VERSION ""

NS_ :

BS_:

BU_: SMART_CORE

BO_ 1911 MGM_DIAG_REQ: 8 SMART_CORE
 SG_ DIAG_MGM_REQ_DATA : 0|64@1+ (1,0) [0|1.8446744074E+019] ""  SMART_CORE

BO_ 1980 LDC_DIAG_RES: 8 Vector__XXX
 SG_ DIAG_LDC_RES_DATA : 0|64@1+ (1,0) [0|1.8446744074E+019] "NA"  SMART_CORE

BO_ 2008 MCU_DIAG_RES: 8 Vector__XXX
 SG_ DIAG_MCU_RES_DATA : 0|64@1+ (1,0) [0|0] ""  SMART_CORE

BO_ 579 VCU_EVCAN_WAKEUP: 8 Vector__XXX
 SG_ VCU_EVCAN_WAKEUPREASONRESERVED2 : 24|40@1+ (1,0) [0|5] "NA"  SMART_CORE
 SG_ VCU_EVCAN_WAKEUPREASONRESERVED1 : 0|8@1+ (1,0) [0|5] "NA"  SMART_CORE
 SG_ VCU_EVCAN_WAKEUPREASON : 8|16@1+ (1,0) [0|5] "NA"  SMART_CORE

BO_ 936 VCU_EVCAN_SLEEP: 8 Vector__XXX
 SG_ VCU_EVCAN_SLEEPRESERVED : 0|64@1+ (1,0) [0|0] "NA"  SMART_CORE

BO_ 1933 ETL_DIAG_RES: 8 Vector__XXX
 SG_ DIAG_ETL_RES_DATA : 0|64@1+ (1,0) [0|1.8446744074E+019] "NA"  SMART_CORE

BO_ 1981 OBC_DIAG_RES: 8 Vector__XXX
 SG_ DIAG_OBC_RES_DATA : 0|64@1+ (1,0) [0|1.8446744074E+019] "NA"  SMART_CORE

BO_ 1976 BMS_DIAG_RES: 8 Vector__XXX
 SG_ DIAG_BMS_RES_DATA : 0|64@1+ (1,0) [0|1.8446744074E+019] "NA"  SMART_CORE

BO_ 1972 LDC_DIAG_REQ: 8 SMART_CORE
 SG_ DIAG_LDC_REQ_DATA : 0|64@1+ (1,0) [0|1.8446744074E+019] "NA" Vector__XXX

BO_ 1925 ETL_DIAG_REQ: 8 SMART_CORE
 SG_ DIAG_ETL_REQ_DATA : 0|64@1+ (1,0) [0|1.8446744074E+019] "NA" Vector__XXX

BO_ 1973 OBC_DIAG_REQ: 8 SMART_CORE
 SG_ DIAG_OBC_REQ_DATA : 0|64@1+ (1,0) [0|1.8446744074E+019] "NA" Vector__XXX

BO_ 2000 MCU_DIAG_REQ: 8 SMART_CORE
 SG_ DIAG_MCU_REQ_DATA : 0|64@1+ (1,0) [0|1.8446744074E+019] "NA" Vector__XXX

BO_ 1968 BMS_DIAG_REQ: 8 SMART_CORE
 SG_ DIAG_BMS_REQ_DATA : 0|64@1+ (1,0) [0|1.8446744074E+019] "NA" Vector__XXX

BO_ 336 BMS18_50: 8 Vector__XXX
 SG_ BMS_TotalCycle_Time : 48|16@1+ (1,0) [0|65535] "Min"  SMART_CORE
 SG_ BMS_DischargeCycle_Time : 32|16@1+ (1,0) [0|65535] "Min"  SMART_CORE
 SG_ BMS_ChargeCycle_Time : 16|16@1+ (1,0) [0|65535] "Min"  SMART_CORE
 SG_ BMS_CycleNumber : 0|16@1+ (1,0) [0|65534] ""  SMART_CORE

BO_ 285 BMS16_10: 8 Vector__XXX
 SG_ BMS_BattPack_PwrLimitErr_Common : 39|1@1+ (1,0) [0|1] ""  SMART_CORE
 SG_ BMS_Bat_I_OvrExtCurr_Flt_Dischrg : 41|1@1+ (1,0) [0|1] ""  SMART_CORE
 SG_ BMS_Bat_I_OverCurr_Flt_Discharge : 42|1@1+ (1,0) [0|1] ""  SMART_CORE
 SG_ BMS_BattOverVolt_Cutoff_Charge : 6|1@1+ (1,0) [0|1] ""  SMART_CORE
 SG_ BMS_ClntInlet_High_Temp_Charge : 15|1@1+ (1,0) [0|1] ""  SMART_CORE
 SG_ BMS_ClntInlet_Low_Temp_Charge : 14|1@1+ (1,0) [0|1] ""  SMART_CORE
 SG_ BMS_ClntOutlet_Low_Temp_Charge : 22|1@1+ (1,0) [0|1] ""  SMART_CORE
 SG_ BMS_Clntoutlet_High_Temp_Charge : 23|1@1+ (1,0) [0|1] ""  SMART_CORE
 SG_ BMS_BattOver_Temp_Cutoff_common : 31|1@1+ (1,0) [0|1] ""  SMART_CORE
 SG_ BMS_BattUnder_Temp_Cutoff_common : 30|1@1+ (1,0) [0|1] ""  SMART_CORE
 SG_ BMS_ClntSen_Thres_Fault_Charge : 21|1@1+ (1,0) [0|1] ""  SMART_CORE
 SG_ BMS_ReverseCurrDetect_Charge : 20|1@1+ (1,0) [0|1] ""  SMART_CORE
 SG_ BMS_PLP_Stop_Charge : 19|1@1+ (1,0) [0|1] ""  SMART_CORE
 SG_ BMS_CellUnderVolt_Cutoff_Common : 29|1@1+ (1,0) [0|1] ""  SMART_CORE
 SG_ BMS_BattUnderVolt_Cutoff_Common : 28|1@1+ (1,0) [0|1] ""  SMART_CORE
 SG_ BMS_ModuleOverTemp_Cutoff_Common : 27|1@1+ (1,0) [0|1] ""  SMART_CORE
 SG_ BMS_MdleUnderTemp_Cutoff_Common : 26|1@1+ (1,0) [0|1] ""  SMART_CORE
 SG_ BMS_ShortCircuitCurr_Flt_Common : 38|1@1+ (1,0) [0|1] ""  SMART_CORE
 SG_ BMS_Sensor_Failure_Common : 37|1@1+ (1,0) [0|1] ""  SMART_CORE
 SG_ BMS_Ibatt_392_25sec_Common : 36|1@1+ (1,0) [0|1] ""  SMART_CORE
 SG_ BMS_PilotLine_Detect_Common : 35|1@1+ (1,0) [0|1] ""  SMART_CORE
 SG_ BMS_Revive_Common : 34|1@1+ (1,0) [0|1] ""  SMART_CORE
 SG_ BMS_HeaterSys_Flt_Common : 47|1@1+ (1,0) [0|1] ""  SMART_CORE
 SG_ BMS_Clnt_TempSens_Flt_Common : 46|1@1+ (1,0) [0|1] ""  SMART_CORE
 SG_ BMS_Heater_Flt_Common : 45|1@1+ (1,0) [0|1] ""  SMART_CORE
 SG_ BMS_IsoFLt_Red_Discharge : 44|1@1+ (1,0) [0|1] ""  SMART_CORE
 SG_ BMS_LowSOC_Cutoff_Discharge : 43|1@1+ (1,0) [0|1] ""  SMART_CORE
 SG_ BMS_Bat_I_ExtCurr_Flt_Dischrg : 40|1@1+ (1,0) [0|1] ""  SMART_CORE
 SG_ BMS_MTM_ActvLimit_Common : 33|1@1+ (1,0) [0|1] ""  SMART_CORE
 SG_ BMS_ClntSys_Flt_Common : 32|1@1+ (1,0) [0|1] ""  SMART_CORE
 SG_ BMS_Pump_DryRun_Err_Common : 25|1@1+ (1,0) [0|1] ""  SMART_CORE
 SG_ BMS_CrashDtct_P_F_Open_Common : 24|1@1+ (1,0) [0|1] ""  SMART_CORE
 SG_ BMS_HVIL_Err_Dischrg : 55|1@1+ (1,0) [0|1] ""  SMART_CORE
 SG_ BMS_No_Cntctr_Close : 54|1@1+ (1,0) [0|1] ""  SMART_CORE
 SG_ BMS_CntctrOpen_Rqst_VCU_Dischrg : 52|1@1+ (1,0) [0|1] ""  SMART_CORE
 SG_ BMS_CntctrOpen_Rqst_VCU_Chrg : 53|1@1+ (1,0) [0|1] ""  SMART_CORE
 SG_ BMS_InitCntctrOpen_Dischrg : 51|1@1+ (1,0) [0|1] ""  SMART_CORE
 SG_ BMS_InitCntctrOpen_Charge : 50|1@1+ (1,0) [0|1] ""  SMART_CORE
 SG_ BMS_FSBIM_bAcvDrtdMode : 49|1@1+ (1,0) [0|1] ""  SMART_CORE
 SG_ BMS_FSPLP_bAcvDrtdMode : 48|1@1+ (1,0) [0|1] ""  SMART_CORE
 SG_ BMS_ILC_AcvDrtdCdn : 60|1@1+ (1,0) [0|1] ""  SMART_CORE
 SG_ BMS_IDMStsIsInErr_Yellow : 61|1@1+ (1,0) [0|1] ""  SMART_CORE
 SG_ BMS_FSPLP_bAcvPackOverUDrtd : 63|1@1+ (1,0) [0|1] ""  SMART_CORE
 SG_ BMS_BIM_bAcvHighRateDchaDrdt2 : 59|1@1+ (1,0) [0|1] ""  SMART_CORE
 SG_ BMS_FSPLP_bAcvPackUnderUDrtd : 62|1@1+ (1,0) [0|1] ""  SMART_CORE
 SG_ BMS_BIMbAcvReqDrtdMode : 58|1@1+ (1,0) [0|1] ""  SMART_CORE
 SG_ BMS_BTFD_bAcvReqDrtdMode : 57|1@1+ (1,0) [0|1] ""  SMART_CORE
 SG_ BMS_CUM_bAcvOwDrtd : 56|1@1+ (1,0) [0|1] ""  SMART_CORE
 SG_ BMS_CellOverVolt_Cutoff_Charge : 7|1@1+ (1,0) [0|1] ""  SMART_CORE
 SG_ BMS_Reason_HV_Disconnected : 16|3@1+ (1,0) [0|7] ""  SMART_CORE
 SG_ BMS_Reason_HV_Disconnect_Request : 8|6@1+ (1,0) [0|28] ""  SMART_CORE
 SG_ BMS_Reason_Derating : 0|6@1+ (1,0) [0|30] ""  SMART_CORE

BO_ 1954 ESCL_DIAG_REQ: 8 SMART_CORE
 SG_ DIAG_ESCL_REQ_DATA : 0|64@1+ (1,0) [0|1.84467440737096E+019] "" Vector__XXX

BO_ 1962 ESCL_DIAG_RES: 8 Vector__XXX
 SG_ DIAG_ESCL_RES_DATA : 0|64@1+ (1,0) [0|1.84467440737096E+019] ""  SMART_CORE

BO_ 920 HLCU1_100: 8 Vector__XXX
 SG_ STS_HIGHBEAM_BOOSTER : 0|1@1+ (1,0) [0|1] ""  SMART_CORE
 SG_ HEADLAMP_AUTO_LEVEL : 1|1@1+ (1,0) [0|1] ""  SMART_CORE

BO_ 921 HLCU2_100: 8 Vector__XXX
 SG_ STS_HIGHBEAM_BOOSTER_1 : 0|1@1+ (1,0) [0|1] ""  SMART_CORE

BO_ 667 HLCU2_NSM: 8 Vector__XXX
 SG_ RESERVED_HLCU : 0|64@1+ (1,0) [0|0] ""  SMART_CORE

BO_ 654 IS_NSM: 8 SMART_CORE
 SG_ RESERVED_IS : 0|64@1+ (1,0) [0|0] "" Vector__XXX

BO_ 662 APA_NSM: 8 Vector__XXX
 SG_ RESERVED_APA : 0|64@1+ (1,0) [0|0] ""  SMART_CORE

BO_ 771 FATC2_200: 8 Vector__XXX
 SG_ PASSIVE_VENT_FATC_STS : 36|1@1+ (1,0) [0|1] ""  SMART_CORE
 SG_ DISP_AMBT_TEMP_FATC : 0|8@1+ (1,-40) [-40|215] "deg C."  SMART_CORE

BO_ 809 WLC_NSM: 8 Vector__XXX
 SG_ RESERVED_WLC : 0|64@1+ (1,0) [0|0] ""  SMART_CORE

BO_ 1711 WLC3_2000: 8 Vector__XXX
 SG_ FOD_ALERT : 8|1@1+ (1,0) [0|1] ""  SMART_CORE
 SG_ TIME_TO_CHARGE : 0|8@1+ (1,0) [0|255] "min"  SMART_CORE

BO_ 768 FATC1_200: 8 Vector__XXX
 SG_ STS_IONIZER : 60|1@1+ (1,0) [0|1] ""  SMART_CORE
 SG_ AC_SWT_STS : 48|1@1+ (1,0) [0|1] ""  SMART_CORE
 SG_ AUTO_RECIRC : 46|1@1+ (1,0) [0|1] ""  SMART_CORE
 SG_ AUTO_DEFROST : 63|1@1+ (1,0) [0|1] ""  SMART_CORE
 SG_ STS_REAR_AC : 51|1@1+ (1,0) [0|1] ""  SMART_CORE
 SG_ MEM_DISP : 8|4@1+ (1,0) [0|15] ""  SMART_CORE
 SG_ FRONT_LEFT_SET_TEMP : 32|8@1+ (0.5,-40) [-40|87.5] "Deg C"  SMART_CORE
 SG_ FRESH_RECIRC : 54|2@1+ (1,0) [0|3] ""  SMART_CORE
 SG_ FATC_ECON : 44|2@1+ (1,0) [0|3] ""  SMART_CORE
 SG_ FATC_AUTO : 40|2@1+ (1,0) [0|3] ""  SMART_CORE
 SG_ FRONT_RIGHT_SET_TEMP : 24|8@1+ (0.5,-40) [-40|87] "Deg C"  SMART_CORE
 SG_ DISP_OFF : 56|2@1+ (1,0) [0|3] ""  SMART_CORE
 SG_ DISP_MODE : 16|4@1+ (1,0) [0|15] ""  SMART_CORE
 SG_ DISP_DUAL : 42|2@1+ (1,0) [0|3] ""  SMART_CORE
 SG_ DISP_AC : 49|2@1+ (1,0) [0|3] ""  SMART_CORE
 SG_ INCAR_TEMP : 0|8@1+ (1,-40) [-40|214] "Deg C"  SMART_CORE
 SG_ DISP_BLOWER : 20|4@1+ (1,0) [0|15] ""  SMART_CORE

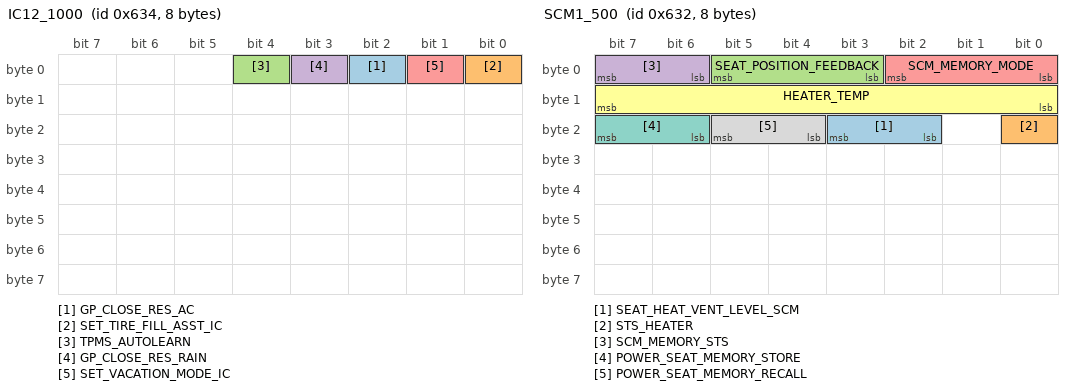
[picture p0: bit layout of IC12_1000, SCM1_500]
BO_ 1588 IC12_1000: 8 SMART_CORE
 SG_ GP_CLOSE_RES_AC : 2|1@1+ (1,0) [0|1] "" Vector__XXX
 SG_ SET_TIRE_FILL_ASST_IC : 0|1@1+ (1,0) [0|1] "" Vector__XXX
 SG_ TPMS_AUTOLEARN : 4|1@1+ (1,0) [0|1] "" Vector__XXX
 SG_ GP_CLOSE_RES_RAIN : 3|1@1+ (1,0) [0|1] "" Vector__XXX
 SG_ SET_VACATION_MODE_IC : 1|1@1+ (1,0) [0|1] "" Vector__XXX

BO_ 1586 SCM1_500: 8 Vector__XXX
 SG_ SEAT_HEAT_VENT_LEVEL_SCM : 18|2@1+ (1,0) [0|3] ""  SMART_CORE
 SG_ STS_HEATER : 16|1@1+ (1,0) [0|1] ""  SMART_CORE
 SG_ SEAT_POSITION_FEEDBACK : 3|3@1+ (1,0) [0|7] ""  SMART_CORE
 SG_ SCM_MEMORY_STS : 6|2@1+ (1,0) [0|3] ""  SMART_CORE
 SG_ SCM_MEMORY_MODE : 0|3@1+ (1,0) [0|7] ""  SMART_CORE
 SG_ HEATER_TEMP : 8|8@1+ (1,-40) [-40|214] "deg C."  SMART_CORE
 SG_ POWER_SEAT_MEMORY_STORE : 22|2@1+ (1,0) [0|3] ""  SMART_CORE
 SG_ POWER_SEAT_MEMORY_RECALL : 20|2@1+ (1,0) [0|3] ""  SMART_CORE

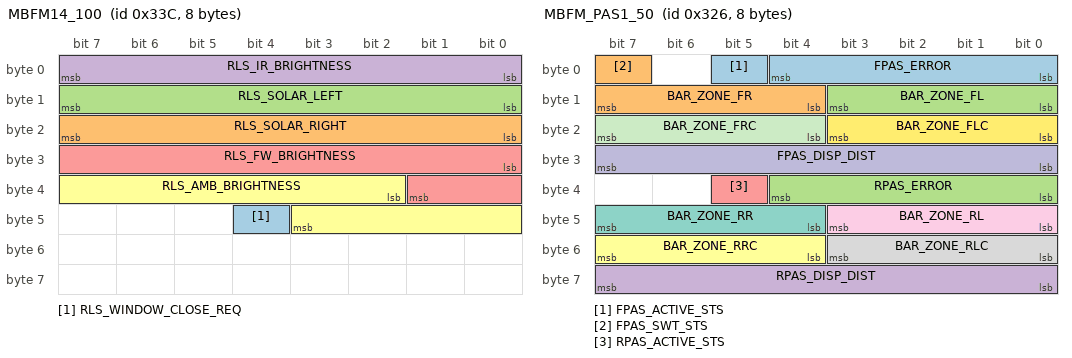
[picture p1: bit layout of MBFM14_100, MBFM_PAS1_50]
BO_ 828 MBFM14_100: 8 Vector__XXX
 SG_ RLS_WINDOW_CLOSE_REQ : 44|1@1+ (1,0) [0|1] ""  SMART_CORE
 SG_ RLS_SOLAR_RIGHT : 16|8@1+ (5,0) [0|1200] "w/m2"  SMART_CORE
 SG_ RLS_SOLAR_LEFT : 8|8@1+ (5,0) [0|1200] "w/m2"  SMART_CORE
 SG_ RLS_IR_BRIGHTNESS : 0|8@1+ (400,0) [0|101200] "Lux"  SMART_CORE
 SG_ RLS_FW_BRIGHTNESS : 24|10@1+ (6,0) [0|6126] "Lux"  SMART_CORE
 SG_ RLS_AMB_BRIGHTNESS : 34|10@1+ (20,0) [0|20460] "Lux"  SMART_CORE

BO_ 806 MBFM_PAS1_50: 8 Vector__XXX
 SG_ FPAS_ACTIVE_STS : 5|1@1+ (1,0) [0|1] ""  SMART_CORE
 SG_ FPAS_SWT_STS : 7|1@1+ (1,0) [0|0] "NA"  SMART_CORE
 SG_ RPAS_ERROR : 32|5@1+ (1,0) [0|31] ""  SMART_CORE
 SG_ RPAS_DISP_DIST : 56|8@1+ (1,0) [0|255] ""  SMART_CORE
 SG_ RPAS_ACTIVE_STS : 37|1@1+ (1,0) [0|1] ""  SMART_CORE
 SG_ BAR_ZONE_RRC : 52|4@1+ (1,0) [0|15] ""  SMART_CORE
 SG_ BAR_ZONE_RR : 44|4@1+ (1,0) [0|15] ""  SMART_CORE
 SG_ BAR_ZONE_RLC : 48|4@1+ (1,0) [0|15] ""  SMART_CORE
 SG_ BAR_ZONE_RL : 40|4@1+ (1,0) [0|15] ""  SMART_CORE
 SG_ FPAS_DISP_DIST : 24|8@1+ (1,0) [0|255] ""  SMART_CORE
 SG_ BAR_ZONE_FRC : 20|4@1+ (1,0) [0|15] ""  SMART_CORE
 SG_ BAR_ZONE_FLC : 16|4@1+ (1,0) [0|15] ""  SMART_CORE
 SG_ FPAS_ERROR : 0|5@1+ (1,0) [0|31] ""  SMART_CORE
 SG_ BAR_ZONE_FR : 12|4@1+ (1,0) [0|15] ""  SMART_CORE
 SG_ BAR_ZONE_FL : 8|4@1+ (1,0) [0|15] ""  SMART_CORE

BO_ 2029 MBFM_DIAG_RES: 8 Vector__XXX
 SG_ DIAG_MBFM_RES_DATA : 0|64@1+ (1,0) [0|1.8446744074E+019] ""  SMART_CORE

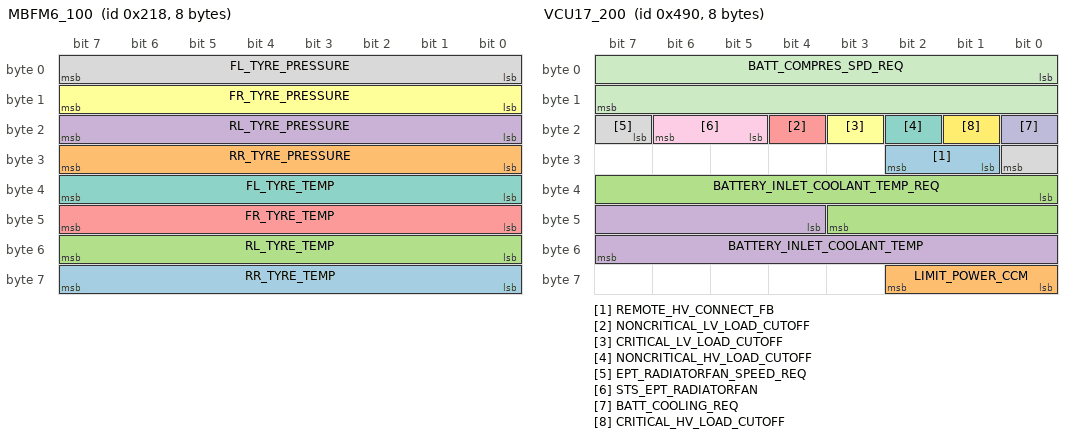
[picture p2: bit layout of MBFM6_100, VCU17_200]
BO_ 536 MBFM6_100: 8 Vector__XXX
 SG_ RR_TYRE_TEMP : 56|8@1+ (1,-40) [-40|214] "deg C"  SMART_CORE
 SG_ RR_TYRE_PRESSURE : 24|8@1+ (0.25,0) [0|63.5] "Psi"  SMART_CORE
 SG_ RL_TYRE_TEMP : 48|8@1+ (1,-40) [-40|214] "deg C"  SMART_CORE
 SG_ RL_TYRE_PRESSURE : 16|8@1+ (0.25,0) [0|63.5] "Psi"  SMART_CORE
 SG_ FR_TYRE_TEMP : 40|8@1+ (1,-40) [-40|214] "deg C"  SMART_CORE
 SG_ FR_TYRE_PRESSURE : 8|8@1+ (0.25,0) [0|63.5] "Psi"  SMART_CORE
 SG_ FL_TYRE_TEMP : 32|8@1+ (1,-40) [-40|214] "deg C"  SMART_CORE
 SG_ FL_TYRE_PRESSURE : 0|8@1+ (0.25,0) [0|63.5] "Psi"  SMART_CORE

BO_ 1056 CCM3_200: 8 Vector__XXX
 SG_ CABIN_HVAC_STS_CCM : 34|2@1+ (1,0) [0|3] ""  SMART_CORE
 SG_ HEATER_INPUT_DC_VOLT : 48|16@1+ (1,0) [0|510] "V"  SMART_CORE
 SG_ CABIN_HEATER_POWER_CONSUMPTION : 24|8@1+ (50,0) [0|10000] "watts"  SMART_CORE
 SG_ AC_OFF_CODE : 0|8@1+ (1,0) [0|202] ""  SMART_CORE
 SG_ REMOTE_HVAC_STS_CCM : 32|2@1+ (1,0) [0|3] ""  SMART_CORE

BO_ 940 CCM_ACTIVE: 8 Vector__XXX
 SG_ RESERVED_CCM_ACTIVE : 0|64@1+ (1,0) [0|1.8446744074E+019] ""  SMART_CORE

BO_ 1001 BMS3_100: 8 Vector__XXX
 SG_ BMS_ChargeVoltageLimit : 48|14@1+ (0.1,0) [0|430] "V"  SMART_CORE
 SG_ BMS_ChargeCurrentLimit : 32|14@1+ (0.1,0) [0|400] "A"  SMART_CORE
 SG_ BMS_DischargeCurrentlimit : 0|14@1+ (0.1,0) [0|500] "A"  SMART_CORE

BO_ 1168 VCU17_200: 8 Vector__XXX
 SG_ REMOTE_HV_CONNECT_FB : 25|2@1+ (1,0) [0|3] ""  SMART_CORE
 SG_ LIMIT_POWER_CCM : 56|3@1+ (1,0) [0|7] ""  SMART_CORE
 SG_ BATTERY_INLET_COOLANT_TEMP_REQ : 32|12@1+ (0.1,-40) [-40|125] "Deg C"  SMART_CORE
 SG_ BATTERY_INLET_COOLANT_TEMP : 44|12@1+ (0.1,-40) [-40|125] "Deg C"  SMART_CORE
 SG_ NONCRITICAL_LV_LOAD_CUTOFF : 20|1@1+ (1,0) [0|1] ""  SMART_CORE
 SG_ CRITICAL_LV_LOAD_CUTOFF : 19|1@1+ (1,0) [0|1] ""  SMART_CORE
 SG_ NONCRITICAL_HV_LOAD_CUTOFF : 18|1@1+ (1,0) [0|1] ""  SMART_CORE
 SG_ EPT_RADIATORFAN_SPEED_REQ : 23|2@1+ (1,0) [0|3] "NA"  SMART_CORE
 SG_ STS_EPT_RADIATORFAN : 21|2@1+ (1,0) [0|3] "NA"  SMART_CORE
 SG_ BATT_COOLING_REQ : 16|1@1+ (1,0) [0|1] ""  SMART_CORE
 SG_ BATT_COMPRES_SPD_REQ : 0|16@1+ (1,0) [0|65534] "RPM"  SMART_CORE
 SG_ CRITICAL_HV_LOAD_CUTOFF : 17|1@1+ (1,0) [0|1] ""  SMART_CORE

BO_ 1865 CCM_DIAG_RES: 8 Vector__XXX
 SG_ DIAG_CCM_RES_DATA : 0|64@1+ (1,0) [0|1.8446744074E+019] ""  SMART_CORE

BO_ 1857 CCM_DIAG_REQ: 8 SMART_CORE
 SG_ DIAG_CCM_REQ_DATA : 0|64@1+ (1,0) [0|1.8446744074E+019] "" Vector__XXX

BO_ 965 IS_ACTIVE: 8 SMART_CORE
 SG_ RESERVED_2 : 0|64@1+ (1,0) [0|1.84467440737096E+019] "" Vector__XXX

BO_ 159 VCU_WAKEUP: 8 Vector__XXX
 SG_ VCU_WAKEUP_REASON : 8|16@1+ (1,0) [0|65535] ""  SMART_CORE

BO_ 942 VCU_SLEEP: 8 Vector__XXX
 SG_ RESERVED_2 : 0|64@1+ (1,0) [0|1.84467440737096E+019] ""  SMART_CORE

BO_ 943 VCU_ACTIVE: 8 Vector__XXX
 SG_ VCU_ACTIVE_RESERVED : 0|64@1+ (1,0) [0|0] "NA"  SMART_CORE

BO_ 954 FATC_ACTIVE: 8 Vector__XXX
 SG_ RESERVED_4 : 0|64@1+ (1,0) [0|1.8446744074E+019] ""  SMART_CORE

BO_ 564 IC_ACTIVE: 8 SMART_CORE
 SG_ RESERVED_2 : 0|64@1+ (1,0) [0|1.84467440737096E+019] "" Vector__XXX

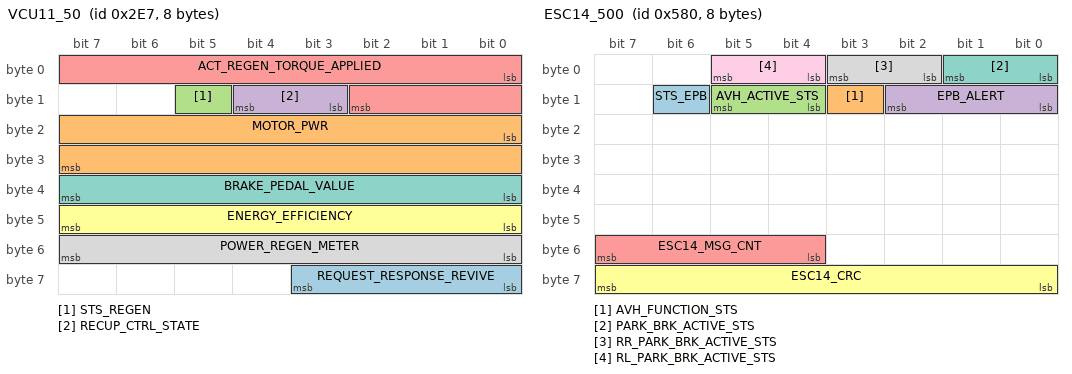
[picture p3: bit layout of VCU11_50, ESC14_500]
BO_ 743 VCU11_50: 8 Vector__XXX
 SG_ REQUEST_RESPONSE_REVIVE : 56|4@1+ (1,0) [0|15] ""  SMART_CORE
 SG_ MOTOR_PWR : 16|16@1+ (5,-163840) [-163840|163835] "W"  SMART_CORE
 SG_ STS_REGEN : 13|1@1+ (1,0) [0|1] ""  SMART_CORE
 SG_ RECUP_CTRL_STATE : 11|2@1+ (1,0) [0|3] ""  SMART_CORE
 SG_ ACT_REGEN_TORQUE_APPLIED : 0|11@1+ (1,-1023) [-1023|1024] "Nm"  SMART_CORE
 SG_ ENERGY_EFFICIENCY : 40|8@1+ (0.1,0) [0|25] "km/kWh"  SMART_CORE
 SG_ BRAKE_PEDAL_VALUE : 32|8@1+ (1,0) [0|100] "%"  SMART_CORE
 SG_ POWER_REGEN_METER : 48|8@1+ (1,-100) [-100|100] "%"  SMART_CORE

BO_ 1416 IS6_500: 8 SMART_CORE
 SG_ WLC_ENABLE_SETTING_IS : 23|1@1+ (1,0) [0|1] "" Vector__XXX
 SG_ IRVM_AUTO_DIMMING_IS : 41|1@1+ (1,0) [0|1] "" Vector__XXX
 SG_ SUNROOF_WINDOW_OPEN_IS : 18|1@1+ (1,0) [0|1] "" Vector__XXX
 SG_ POWER_SEAT_RECALL_IS : 10|2@1+ (1,0) [0|3] "" Vector__XXX
 SG_ SET_AUTO_BRAKE_LAMP_IS : 24|2@1+ (1,0) [0|0] "" Vector__XXX
 SG_ DYNAMIC_TRAJ_LINES_RPAS : 22|1@1+ (1,0) [0|0] "" Vector__XXX
 SG_ DYNAMIC_TRAJ_LINE_FPAS_APA : 21|1@1+ (1,0) [0|0] "" Vector__XXX
 SG_ AUTO_TOPVIEW_ON_PAS_FRONT : 20|1@1+ (1,0) [0|0] "" Vector__XXX
 SG_ RVC_TTS : 17|1@1+ (1,0) [0|0] "" Vector__XXX
 SG_ SET_PARKBRAKE_AUTO_ACT_IS : 13|1@1+ (1,0) [0|0] "" Vector__XXX
 SG_ AVM_CONTROL_IS : 12|1@1+ (1,0) [0|0] "" Vector__XXX
 SG_ FOGLAMP_CONTROL_IS : 6|2@1+ (1,0) [0|0] "" Vector__XXX
 SG_ AUTO_TOPVIEW_ON_PAS_REAR : 19|1@1+ (1,0) [0|0] "" Vector__XXX
 SG_ SET_SERVICE_MODE_IS : 48|1@1+ (1,0) [0|0] "" Vector__XXX
 SG_ STS_PROFILE_LOCK_IS : 15|1@1+ (1,0) [0|1] "" Vector__XXX
 SG_ SET_SMART_ENERGY_IS : 32|2@1+ (1,0) [0|3] "" Vector__XXX
 SG_ HEADLAMP_CONTROL_IS : 4|2@1+ (1,0) [0|0] "" Vector__XXX
 SG_ AMBIENT_LIGHT_CONTROL_IS : 2|2@1+ (1,0) [0|0] "" Vector__XXX
 SG_ SUNROOF_CONTROL_IS : 0|2@1+ (1,0) [0|0] "" Vector__XXX
 SG_ PWR_WINDOW_CONTROL_IS : 26|2@1+ (1,0) [0|3] "" Vector__XXX
 SG_ DOOR_LOCK_CONTROL_IS : 8|2@1+ (1,0) [0|0] "" Vector__XXX
 SG_ SET_REMOTE_ENG_STARTSTOP : 40|1@1+ (1,0) [0|1] "" Vector__XXX
 SG_ SET_WALK_AWAY_LCK_IS : 16|1@1+ (1,0) [0|1] "" Vector__XXX
 SG_ SET_APPROACH_UNLCK_IS : 14|1@1+ (1,0) [0|1] "" Vector__XXX

BO_ 812 MCM_NSM: 8 SMART_CORE
 SG_ RESERVED_MCM : 0|64@1+ (1,0) [0|0] ""  SMART_CORE

BO_ 250 MCM_PKE_SP: 8 SMART_CORE
 SG_ IMMOVAL6 : 0|64@1+ (1,0) [0|1.8446744074] "" Vector__XXX

BO_ 1408 ESC14_500: 8 Vector__XXX
 SG_ STS_EPB : 14|1@1+ (1,0) [0|1] ""  SMART_CORE
 SG_ AVH_FUNCTION_STS : 11|1@1+ (1,0) [0|1] ""  SMART_CORE
 SG_ AVH_ACTIVE_STS : 12|2@1+ (1,0) [0|3] ""  SMART_CORE
 SG_ EPB_ALERT : 8|3@1+ (1,0) [0|7] ""  SMART_CORE
 SG_ ESC14_MSG_CNT : 52|4@1+ (1,0) [0|15] ""  SMART_CORE
 SG_ ESC14_CRC : 56|8@1+ (1,0) [0|255] ""  SMART_CORE
 SG_ PARK_BRK_ACTIVE_STS : 0|2@1+ (1,0) [0|3] ""  SMART_CORE
 SG_ RR_PARK_BRK_ACTIVE_STS : 2|2@1+ (1,0) [0|3] ""  SMART_CORE
 SG_ RL_PARK_BRK_ACTIVE_STS : 4|2@1+ (1,0) [0|3] ""  SMART_CORE

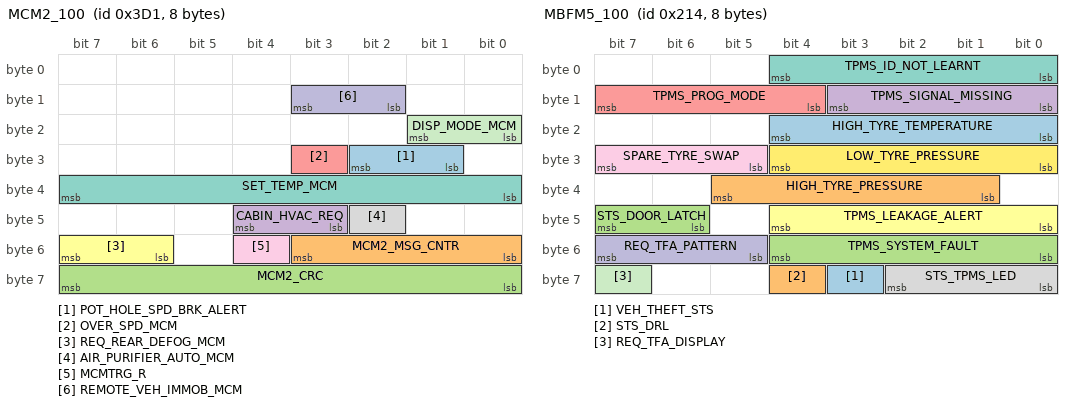
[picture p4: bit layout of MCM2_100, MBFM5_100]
BO_ 977 MCM2_100: 8 SMART_CORE
 SG_ POT_HOLE_SPD_BRK_ALERT : 25|2@1+ (1,0) [0|3] "" Vector__XXX
 SG_ MCM2_MSG_CNTR : 48|4@1+ (1,0) [0|0] "" Vector__XXX
 SG_ MCM2_CRC : 56|8@1+ (1,0) [0|0] "" Vector__XXX
 SG_ CABIN_HVAC_REQ : 43|2@1+ (1,0) [0|3] "" Vector__XXX
 SG_ OVER_SPD_MCM : 27|1@1+ (1,0) [0|1] "" Vector__XXX
 SG_ REQ_REAR_DEFOG_MCM : 54|2@1+ (1,0) [0|3] "" Vector__XXX
 SG_ SET_TEMP_MCM : 32|8@1+ (0.5,-40) [-40|87] "" Vector__XXX
 SG_ AIR_PURIFIER_AUTO_MCM : 42|1@1+ (1,0) [0|0] "" Vector__XXX
 SG_ MCMTRG_R : 52|1@1+ (1,0) [0|1] "" Vector__XXX
 SG_ REMOTE_VEH_IMMOB_MCM : 10|2@1+ (1,0) [0|0] "" Vector__XXX
 SG_ DISP_MODE_MCM : 16|2@1+ (1,0) [0|3] "" Vector__XXX

BO_ 958 ESCL_ACTIVE: 8 Vector__XXX
 SG_ RESERVED_2 : 0|64@1+ (1,0) [0|1.84467440737096E+019] ""  SMART_CORE

BO_ 976 ESCL_NSM: 8 Vector__XXX
 SG_ RESERVED_ESCL : 0|64@1+ (1,0) [0|1.84467440737096E+019] ""  SMART_CORE

BO_ 532 MBFM5_100: 8 Vector__XXX
 SG_ VEH_THEFT_STS : 59|1@1+ (1,0) [0|1] ""  SMART_CORE
 SG_ STS_DRL : 60|1@1+ (1,0) [0|1] ""  SMART_CORE
 SG_ TPMS_SYSTEM_FAULT : 48|5@1+ (1,0) [0|31] ""  SMART_CORE
 SG_ TPMS_SIGNAL_MISSING : 8|4@1+ (1,0) [0|15] ""  SMART_CORE
 SG_ TPMS_PROG_MODE : 12|4@1+ (1,0) [0|15] ""  SMART_CORE
 SG_ TPMS_LEAKAGE_ALERT : 40|5@1+ (1,0) [0|31] ""  SMART_CORE
 SG_ TPMS_ID_NOT_LEARNT : 0|5@1+ (1,0) [0|31] ""  SMART_CORE
 SG_ STS_TPMS_LED : 56|3@1+ (1,0) [0|3] ""  SMART_CORE
 SG_ SPARE_TYRE_SWAP : 29|3@1+ (1,0) [0|4] ""  SMART_CORE
 SG_ REQ_TFA_PATTERN : 53|3@1+ (1,0) [0|5] ""  SMART_CORE
 SG_ REQ_TFA_DISPLAY : 63|1@1+ (1,0) [0|1] ""  SMART_CORE
 SG_ LOW_TYRE_PRESSURE : 24|5@1+ (1,0) [0|31] ""  SMART_CORE
 SG_ HIGH_TYRE_TEMPERATURE : 16|5@1+ (1,0) [0|31] ""  SMART_CORE
 SG_ HIGH_TYRE_PRESSURE : 33|5@1+ (1,0) [0|31] ""  SMART_CORE
 SG_ STS_DOOR_LATCH : 46|2@1+ (1,0) [0|3] ""  SMART_CORE

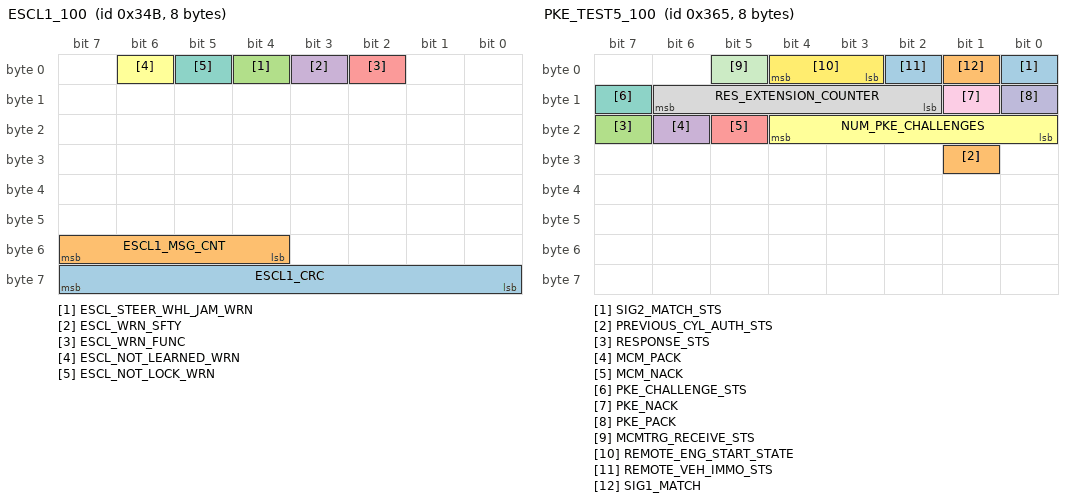
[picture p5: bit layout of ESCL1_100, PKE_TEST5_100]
BO_ 843 ESCL1_100: 8 Vector__XXX
 SG_ ESCL1_CRC : 56|8@1+ (1,0) [0|255] ""  SMART_CORE
 SG_ ESCL1_MSG_CNT : 52|4@1+ (1,0) [0|15] ""  SMART_CORE
 SG_ ESCL_STEER_WHL_JAM_WRN : 4|1@1+ (1,0) [0|1] ""  SMART_CORE
 SG_ ESCL_WRN_SFTY : 3|1@1+ (1,0) [0|1] ""  SMART_CORE
 SG_ ESCL_WRN_FUNC : 2|1@1+ (1,0) [0|1] ""  SMART_CORE
 SG_ ESCL_NOT_LEARNED_WRN : 6|1@1+ (1,0) [0|1] ""  SMART_CORE
 SG_ ESCL_NOT_LOCK_WRN : 5|1@1+ (1,0) [0|1] ""  SMART_CORE

BO_ 151 MBFM_WAKEUP: 8 Vector__XXX
 SG_ MBFM_WAKEUP_REASON : 8|16@1+ (1,0) [0|65535] ""  SMART_CORE

BO_ 964 MBFM_SLEEP: 8 Vector__XXX
 SG_ RESERVED_2 : 0|64@1+ (1,0) [0|1.84467440737096E+019] ""  SMART_CORE

BO_ 961 MBFM_ACTIVE: 8 Vector__XXX
 SG_ RESERVED_2 : 0|64@1+ (1,0) [0|1.84467440737096E+019] ""  SMART_CORE

BO_ 869 PKE_TEST5_100: 8 Vector__XXX
 SG_ SIG2_MATCH_STS : 0|1@1+ (1,0) [0|1] ""  SMART_CORE
 SG_ PREVIOUS_CYL_AUTH_STS : 25|1@1+ (1,0) [0|1] ""  SMART_CORE
 SG_ RESPONSE_STS : 23|1@1+ (1,0) [0|1] ""  SMART_CORE
 SG_ MCM_PACK : 22|1@1+ (1,0) [0|1] ""  SMART_CORE
 SG_ MCM_NACK : 21|1@1+ (1,0) [0|1] ""  SMART_CORE
 SG_ NUM_PKE_CHALLENGES : 16|5@1+ (1,0) [0|31] ""  SMART_CORE
 SG_ PKE_CHALLENGE_STS : 15|1@1+ (1,0) [0|1] ""  SMART_CORE
 SG_ RES_EXTENSION_COUNTER : 10|5@1+ (1,0) [0|31] ""  SMART_CORE
 SG_ PKE_NACK : 9|1@1+ (1,0) [0|0] ""  SMART_CORE
 SG_ PKE_PACK : 8|1@1+ (1,0) [0|0] ""  SMART_CORE
 SG_ MCMTRG_RECEIVE_STS : 5|1@1+ (1,0) [0|1] ""  SMART_CORE
 SG_ REMOTE_ENG_START_STATE : 3|2@1+ (1,0) [0|3] ""  SMART_CORE
 SG_ REMOTE_VEH_IMMO_STS : 2|1@1+ (1,0) [0|1] ""  SMART_CORE
 SG_ SIG1_MATCH : 1|1@1+ (1,0) [0|1] ""  SMART_CORE

BO_ 266 PKE_MCM_SP: 8 Vector__XXX
 SG_ IMMOVAL5 : 0|64@1+ (1,0) [0|1.8446744074] ""  SMART_CORE

BO_ 851 PKE1_100: 8 Vector__XXX
 SG_ LAST_KEYFOB_NUM : 9|3@1+ (1,0) [0|7] ""  SMART_CORE
 SG_ KEYFOB_INSIDE_STATUS : 8|1@1+ (1,0) [0|1] ""  SMART_CORE

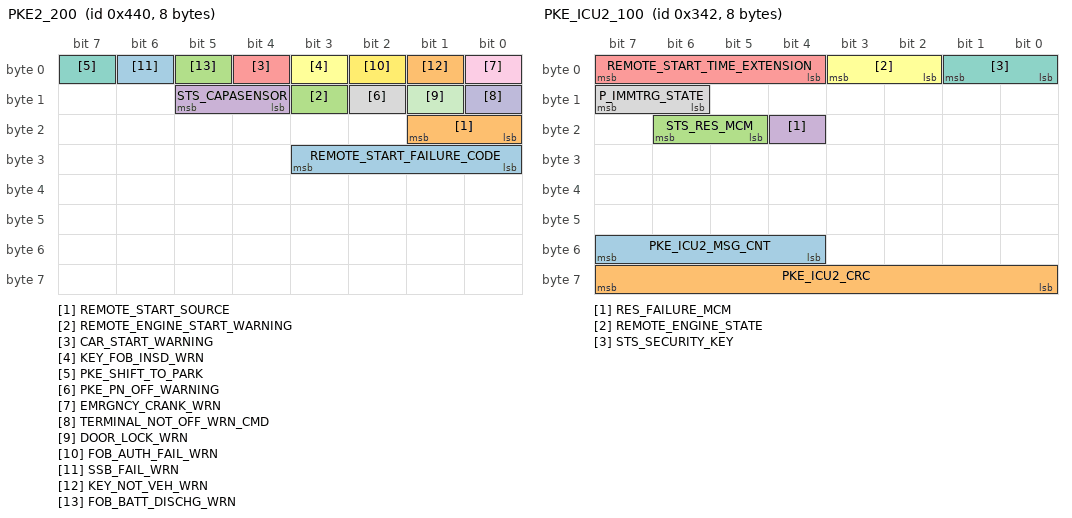
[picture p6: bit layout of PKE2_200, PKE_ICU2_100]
BO_ 1088 PKE2_200: 8 Vector__XXX
 SG_ REMOTE_START_FAILURE_CODE : 24|4@1+ (1,0) [0|0] ""  SMART_CORE
 SG_ REMOTE_START_SOURCE : 16|2@1+ (1,0) [0|0] ""  SMART_CORE
 SG_ REMOTE_ENGINE_START_WARNING : 11|1@1+ (1,0) [0|1] ""  SMART_CORE
 SG_ STS_CAPASENSOR : 12|2@1+ (1,0) [0|3] ""  SMART_CORE
 SG_ CAR_START_WARNING : 4|1@1+ (1,0) [0|1] ""  SMART_CORE
 SG_ KEY_FOB_INSD_WRN : 3|1@1+ (1,0) [0|1] ""  SMART_CORE
 SG_ PKE_SHIFT_TO_PARK : 7|1@1+ (1,0) [0|1] ""  SMART_CORE
 SG_ PKE_PN_OFF_WARNING : 10|1@1+ (1,0) [0|1] ""  SMART_CORE
 SG_ EMRGNCY_CRANK_WRN : 0|1@1+ (1,0) [0|1] ""  SMART_CORE
 SG_ TERMINAL_NOT_OFF_WRN_CMD : 8|1@1+ (1,0) [0|1] ""  SMART_CORE
 SG_ DOOR_LOCK_WRN : 9|1@1+ (1,0) [0|1] ""  SMART_CORE
 SG_ FOB_AUTH_FAIL_WRN : 2|1@1+ (1,0) [0|1] ""  SMART_CORE
 SG_ SSB_FAIL_WRN : 6|1@1+ (1,0) [0|1] ""  SMART_CORE
 SG_ KEY_NOT_VEH_WRN : 1|1@1+ (1,0) [0|1] ""  SMART_CORE
 SG_ FOB_BATT_DISCHG_WRN : 5|1@1+ (1,0) [0|1] ""  SMART_CORE

BO_ 834 PKE_ICU2_100: 8 Vector__XXX
 SG_ PKE_ICU2_MSG_CNT : 52|4@1+ (1,0) [0|15] ""  SMART_CORE
 SG_ PKE_ICU2_CRC : 56|8@1+ (1,0) [0|255] ""  SMART_CORE
 SG_ STS_RES_MCM : 21|2@1+ (1,0) [0|3] ""  SMART_CORE
 SG_ RES_FAILURE_MCM : 20|1@1+ (1,0) [0|0] ""  SMART_CORE
 SG_ REMOTE_START_TIME_EXTENSION : 4|4@1+ (1,0) [0|15] ""  SMART_CORE
 SG_ REMOTE_ENGINE_STATE : 2|2@1+ (1,0) [0|3] ""  SMART_CORE
 SG_ STS_SECURITY_KEY : 0|2@1+ (1,0) [0|3] ""  SMART_CORE
 SG_ P_IMMTRG_STATE : 14|2@1+ (1,0) [0|3] ""  SMART_CORE

BO_ 647 PKE_ICU_NSM: 8 Vector__XXX
 SG_ RESERVED_PKE : 0|64@1+ (1,0) [0|0] ""  SMART_CORE

BO_ 150 PKE_WAKEUP: 8 Vector__XXX
 SG_ PKE_WAKEUP_REASON : 0|16@1+ (1,0) [0|65535] ""  SMART_CORE

BO_ 966 PKE_SLEEP: 8 Vector__XXX
 SG_ RESERVED_2 : 0|64@1+ (1,0) [0|1.84467440737096E+019] ""  SMART_CORE

BO_ 963 PKE_ACTIVE: 8 Vector__XXX
 SG_ RESERVED_2 : 0|64@1+ (1,0) [0|1.84467440737096E+019] ""  SMART_CORE

BO_ 587 FRM1_20: 8 Vector__XXX
 SG_ ACC_SET_DIST : 47|3@1+ (1,0) [0|7] "meter"  SMART_CORE
 SG_ ACC_VEH_SET_SPD : 24|8@1+ (1,0) [0|255] "kmph"  SMART_CORE
 SG_ FRM1_MSG_COUNT : 52|4@1+ (1,0) [0|15] ""  SMART_CORE
 SG_ FRM1_CRC : 56|8@1+ (1,0) [0|255] ""  SMART_CORE
 SG_ ACC_MODE : 50|2@1+ (1,0) [0|3] ""  SMART_CORE

BO_ 928 APA2_50: 8 Vector__XXX
 SG_ FPAS_SPAS_ACTIVE_STS : 57|1@1+ (1,0) [0|1] ""  SMART_CORE
 SG_ FR_SEGMENT : 12|4@1+ (1,0) [0|15] ""  SMART_CORE
 SG_ RL_SEG_WARN : 36|1@1+ (1,0) [0|1] ""  SMART_CORE
 SG_ RPAS_ACTIVE_STS1 : 56|1@1+ (1,0) [0|1] ""  SMART_CORE
 SG_ RL_SEGMENT : 16|4@1+ (1,0) [0|15] ""  SMART_CORE
 SG_ FR_SEG_WARN : 35|1@1+ (1,0) [0|1] ""  SMART_CORE
 SG_ FMR_SEG_WARN : 34|1@1+ (1,0) [0|1] ""  SMART_CORE
 SG_ FML_SEG_WARN : 33|1@1+ (1,0) [0|1] ""  SMART_CORE
 SG_ FL_SEG_WARN : 32|1@1+ (1,0) [0|1] ""  SMART_CORE
 SG_ FMR_SEGMENT : 8|4@1+ (1,0) [0|15] ""  SMART_CORE
 SG_ FML_SEGMENT : 4|4@1+ (1,0) [0|15] ""  SMART_CORE
 SG_ FL_SEGMENT : 0|4@1+ (1,0) [0|15] ""  SMART_CORE
 SG_ RR_SEG_WARN : 39|1@1+ (1,0) [0|1] ""  SMART_CORE
 SG_ RMR_SEG_WARN : 38|1@1+ (1,0) [0|1] ""  SMART_CORE
 SG_ RML_SEG_WARN : 37|1@1+ (1,0) [0|1] ""  SMART_CORE
 SG_ REAR_MIN_DIST : 48|8@1+ (2,0) [0|500] "cm"  SMART_CORE
 SG_ RR_SEGMENT : 28|4@1+ (1,0) [0|15] ""  SMART_CORE
 SG_ RMR_SEGMENT : 24|4@1+ (1,0) [0|0] ""  SMART_CORE
 SG_ RML_SEGMENT : 20|4@1+ (1,0) [0|15] ""  SMART_CORE
 SG_ FRONT_MIN_DIST : 40|8@1+ (2,0) [0|500] "cm"  SMART_CORE

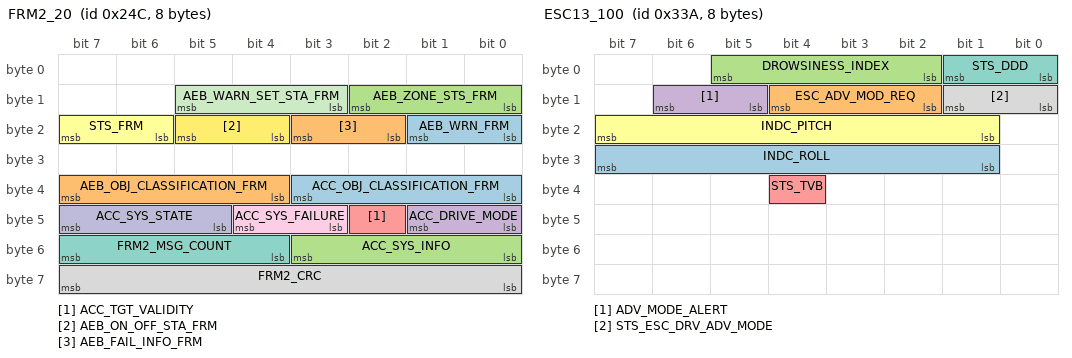
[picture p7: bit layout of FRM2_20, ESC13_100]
BO_ 588 FRM2_20: 8 Vector__XXX
 SG_ ACC_OBJ_CLASSIFICATION_FRM : 32|4@1+ (1,0) [0|15] ""  SMART_CORE
 SG_ AEB_OBJ_CLASSIFICATION_FRM : 36|4@1+ (1,0) [0|15] ""  SMART_CORE
 SG_ ACC_SYS_INFO : 48|4@1+ (1,0) [0|15] ""  SMART_CORE
 SG_ ACC_DRIVE_MODE : 40|2@1+ (1,0) [0|3] ""  SMART_CORE
 SG_ ACC_TGT_VALIDITY : 42|1@1+ (1,0) [0|1] ""  SMART_CORE
 SG_ STS_FRM : 22|2@1+ (1,0) [0|3] ""  SMART_CORE
 SG_ FRM2_MSG_COUNT : 52|4@1+ (1,0) [0|15] ""  SMART_CORE
 SG_ FRM2_CRC : 56|8@1+ (1,0) [0|255] ""  SMART_CORE
 SG_ ACC_SYS_FAILURE : 43|2@1+ (1,0) [0|3] ""  SMART_CORE
 SG_ ACC_SYS_STATE : 45|3@1+ (1,0) [0|7] ""  SMART_CORE
 SG_ AEB_WARN_SET_STA_FRM : 11|3@1+ (1,0) [0|7] ""  SMART_CORE
 SG_ AEB_ON_OFF_STA_FRM : 20|2@1+ (1,0) [0|3] ""  SMART_CORE
 SG_ AEB_WRN_FRM : 16|2@1+ (1,0) [0|3] ""  SMART_CORE
 SG_ AEB_FAIL_INFO_FRM : 18|2@1+ (1,0) [0|3] ""  SMART_CORE
 SG_ AEB_ZONE_STS_FRM : 8|3@1+ (1,0) [0|7] ""  SMART_CORE

BO_ 1843 FCM_DIAG_REQ: 8 SMART_CORE
 SG_ DIAG_FCM_REQ_DATA : 0|64@1+ (1,0) [0|1.8446744074E+019] "" Vector__XXX

BO_ 826 ESC13_100: 8 Vector__XXX
 SG_ INDC_ROLL : 25|7@1+ (1,-62) [-62|65] "Deg"  SMART_CORE
 SG_ ESC_ADV_MOD_REQ : 10|3@1+ (1,0) [0|7] ""  SMART_CORE
 SG_ DROWSINESS_INDEX : 2|4@1+ (1,0) [0|15] ""  SMART_CORE
 SG_ ADV_MODE_ALERT : 13|2@1+ (1,0) [0|3] ""  SMART_CORE
 SG_ STS_TVB : 36|1@1+ (1,0) [0|1] ""  SMART_CORE
 SG_ INDC_PITCH : 17|7@1+ (1,-62) [-62|65] "Deg"  SMART_CORE
 SG_ STS_DDD : 0|2@1+ (1,0) [0|3] ""  SMART_CORE
 SG_ STS_ESC_DRV_ADV_MODE : 8|2@1+ (1,0) [0|3] ""  SMART_CORE

BO_ 829 MBFM15_10: 8 Vector__XXX
 SG_ STS_ELOCKER_MALFUNCTION_LED : 16|1@1+ (1,0) [0|1] ""  SMART_CORE
 SG_ STS_ELOCKER_ACTIVATION_LED : 6|2@1+ (1,0) [0|3] ""  SMART_CORE

BO_ 655 EPS_NSM: 8 Vector__XXX
 SG_ RESERVED_EPS : 0|64@1+ (1,0) [0|0] ""  SMART_CORE

BO_ 651 IC_NSM: 8 SMART_CORE
 SG_ RESERVED_IC : 0|64@1+ (1,0) [0|0] "" Vector__XXX

BO_ 649 ESC_NSM: 8 Vector__XXX
 SG_ RESERVED_ESC : 0|64@1+ (1,0) [0|0] ""  SMART_CORE

BO_ 310 TCU5_10: 8 Vector__XXX
 SG_ SHIFTING : 58|1@1+ (1,0) [0|1] ""  SMART_CORE
 SG_ GEAR_TARGET : 52|4@1+ (1,0) [0|15] ""  SMART_CORE
 SG_ GEAR_ACTUAL : 48|4@1+ (1,0) [0|15] ""  SMART_CORE

BO_ 645 EMS_NSM: 8 Vector__XXX
 SG_ RESERVED_EMS : 0|64@1+ (1,0) [0|0] ""  SMART_CORE

BO_ 643 GW_HEARTBEAT: 8 Vector__XXX
 SG_ GW_CH_STS : 24|8@1+ (1,0) [0|255] ""  SMART_CORE
 SG_ IGN_STS : 0|1@1+ (1,0) [0|1] ""  SMART_CORE
 SG_ IGN_CNTR : 32|16@1+ (1,0) [0|15] ""  SMART_CORE
 SG_ BATT_VOLTAGE : 16|8@1+ (0.1,0) [0|25] "VOLT"  SMART_CORE

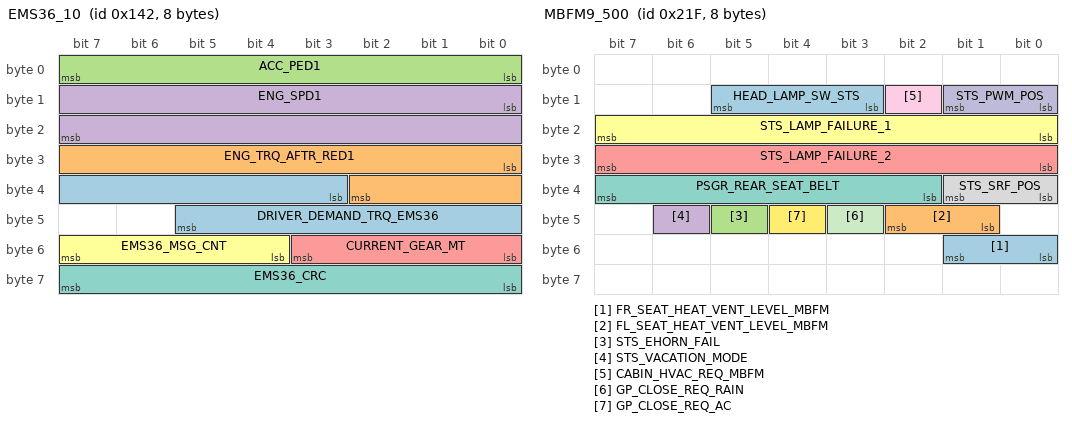
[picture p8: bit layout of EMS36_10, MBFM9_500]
BO_ 322 EMS36_10: 8 Vector__XXX
 SG_ DRIVER_DEMAND_TRQ_EMS36 : 35|11@1+ (1,-1024) [-1024|1022] "Nm"  SMART_CORE
 SG_ ENG_TRQ_AFTR_RED1 : 24|11@1+ (1,-1024) [-1024|1022] "Nm"  SMART_CORE
 SG_ ACC_PED1 : 0|8@1+ (0.4,0) [0|100] "%"  SMART_CORE
 SG_ ENG_SPD1 : 8|16@1+ (1,0) [0|7999] "rpm"  SMART_CORE
 SG_ CURRENT_GEAR_MT : 48|4@1+ (1,0) [0|15] "" Vector__XXX
 SG_ EMS36_MSG_CNT : 52|4@1+ (1,0) [0|15] ""  SMART_CORE
 SG_ EMS36_CRC : 56|8@1+ (1,0) [0|255] ""  SMART_CORE

BO_ 642 ESC12_10: 8 Vector__XXX
 SG_ ODO_DISTANCE_ESC12 : 0|16@1+ (1,0) [0|65535] "m"  SMART_CORE
 SG_ ESC12_MSG_CNT : 52|4@1+ (1,0) [0|15] ""  SMART_CORE
 SG_ ESC12_CRC : 56|8@1+ (1,0) [0|255] ""  SMART_CORE
 SG_ VEHICLE_SPEED_ESC12 : 16|16@1+ (0.015625,0) [0|300] "kmph"  SMART_CORE

BO_ 646 SYNC_MSG_SP: 8 Vector__XXX
 SG_ RESERVED_EMS_SP : 0|64@1+ (1,0) [0|0] ""  SMART_CORE

BO_ 543 MBFM9_500: 8 Vector__XXX
 SG_ FR_SEAT_HEAT_VENT_LEVEL_MBFM : 48|2@1+ (1,0) [0|3] ""  SMART_CORE
 SG_ FL_SEAT_HEAT_VENT_LEVEL_MBFM : 41|2@1+ (1,0) [0|3] ""  SMART_CORE
 SG_ STS_EHORN_FAIL : 45|1@1+ (1,0) [0|0] "NA"  SMART_CORE
 SG_ STS_VACATION_MODE : 46|1@1+ (1,0) [0|1] ""  SMART_CORE
 SG_ STS_LAMP_FAILURE_2 : 24|8@1+ (1,0) [0|255] ""  SMART_CORE
 SG_ STS_LAMP_FAILURE_1 : 16|8@1+ (1,0) [0|255] ""  SMART_CORE
 SG_ PSGR_REAR_SEAT_BELT : 34|6@1+ (1,0) [0|63] ""  SMART_CORE
 SG_ STS_SRF_POS : 32|2@1+ (1,0) [0|3] ""  SMART_CORE
 SG_ CABIN_HVAC_REQ_MBFM : 10|1@1+ (1,0) [0|1] ""  SMART_CORE
 SG_ STS_PWM_POS : 8|2@1+ (1,0) [0|3] ""  SMART_CORE
 SG_ GP_CLOSE_REQ_RAIN : 43|1@1+ (1,0) [0|1] ""  SMART_CORE
 SG_ GP_CLOSE_REQ_AC : 44|1@1+ (1,0) [0|1] ""  SMART_CORE
 SG_ HEAD_LAMP_SW_STS : 11|3@1+ (1,0) [0|7] ""  SMART_CORE

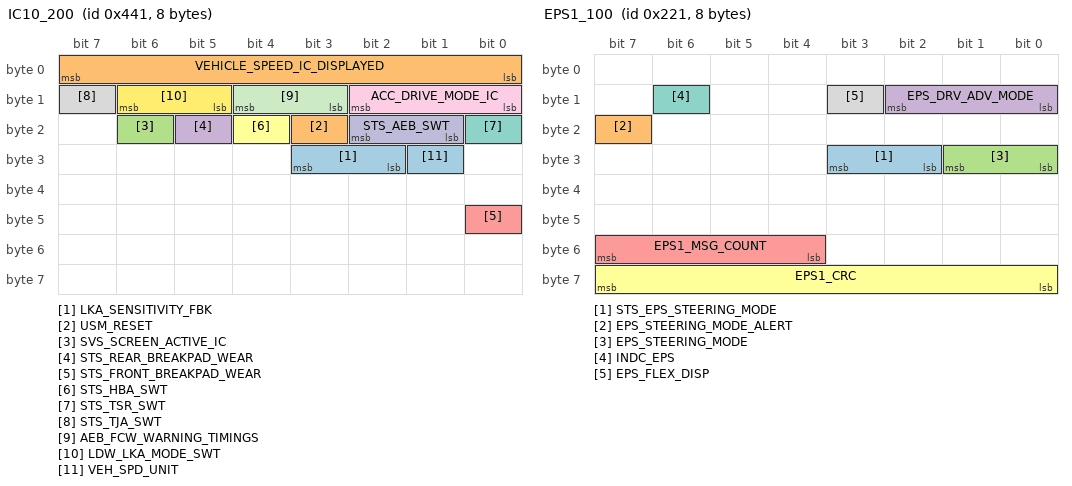
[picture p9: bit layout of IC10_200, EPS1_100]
BO_ 1089 IC10_200: 8 SMART_CORE
 SG_ LKA_SENSITIVITY_FBK : 26|2@1+ (1,0) [0|3] "" Vector__XXX
 SG_ USM_RESET : 19|1@1+ (1,0) [0|1] "" Vector__XXX
 SG_ SVS_SCREEN_ACTIVE_IC : 22|1@1+ (1,0) [0|1] "" Vector__XXX
 SG_ STS_REAR_BREAKPAD_WEAR : 21|1@1+ (1,0) [0|0] "" Vector__XXX
 SG_ STS_FRONT_BREAKPAD_WEAR : 40|1@1+ (1,0) [0|0] "" Vector__XXX
 SG_ STS_HBA_SWT : 20|1@1+ (1,0) [0|1] "" Vector__XXX
 SG_ STS_TSR_SWT : 16|1@1+ (1,0) [0|1] "" Vector__XXX
 SG_ STS_TJA_SWT : 15|1@1+ (1,0) [0|1] "" Vector__XXX
 SG_ ACC_DRIVE_MODE_IC : 8|3@1+ (1,0) [0|7] "" Vector__XXX
 SG_ STS_AEB_SWT : 17|2@1+ (1,0) [0|3] "" Vector__XXX
 SG_ AEB_FCW_WARNING_TIMINGS : 11|2@1+ (1,0) [0|3] "" Vector__XXX
 SG_ LDW_LKA_MODE_SWT : 13|2@1+ (1,0) [0|3] "" Vector__XXX
 SG_ VEH_SPD_UNIT : 25|1@1+ (1,0) [0|1] "" Vector__XXX
 SG_ VEHICLE_SPEED_IC_DISPLAYED : 0|8@1+ (1,0) [0|255] "" Vector__XXX

BO_ 650 MBFM_NSM: 8 Vector__XXX
 SG_ RESERVED_MBFM : 0|64@1+ (1,0) [0|0] ""  SMART_CORE

BO_ 545 EPS1_100: 8 Vector__XXX
 SG_ STS_EPS_STEERING_MODE : 26|2@1+ (1,0) [0|3] ""  SMART_CORE
 SG_ EPS_STEERING_MODE_ALERT : 23|1@1+ (1,0) [0|1] ""  SMART_CORE
 SG_ EPS_STEERING_MODE : 24|2@1+ (1,0) [0|3] ""  SMART_CORE
 SG_ EPS_DRV_ADV_MODE : 8|3@1+ (1,0) [0|7] ""  SMART_CORE
 SG_ EPS1_MSG_COUNT : 52|4@1+ (1,0) [0|15] ""  SMART_CORE
 SG_ EPS1_CRC : 56|8@1+ (1,0) [0|255] ""  SMART_CORE
 SG_ INDC_EPS : 14|1@1+ (1,0) [0|1] ""  SMART_CORE
 SG_ EPS_FLEX_DISP : 11|1@1+ (1,0) [0|1] ""  SMART_CORE

BO_ 1851 FCM_DIAG_RES: 8 Vector__XXX
 SG_ DIAG_FCM_RES_DATA : 0|64@1+ (1,0) [0|1.8446744074E+019] ""  SMART_CORE

BO_ 1407 FCM_TSR_100: 8 Vector__XXX
 SG_ TSR_OVER_TAKE_SIGN : 12|2@1+ (1,0) [0|3] ""  SMART_CORE
 SG_ FCM_TSR_OPT_USM : 10|2@1+ (1,0) [0|3] ""  SMART_CORE
 SG_ TSR_DSP_SPD : 0|8@1+ (1,0) [0|255] ""  SMART_CORE
 SG_ TSR_SYS_STATE : 8|2@1+ (1,0) [0|3] ""  SMART_CORE

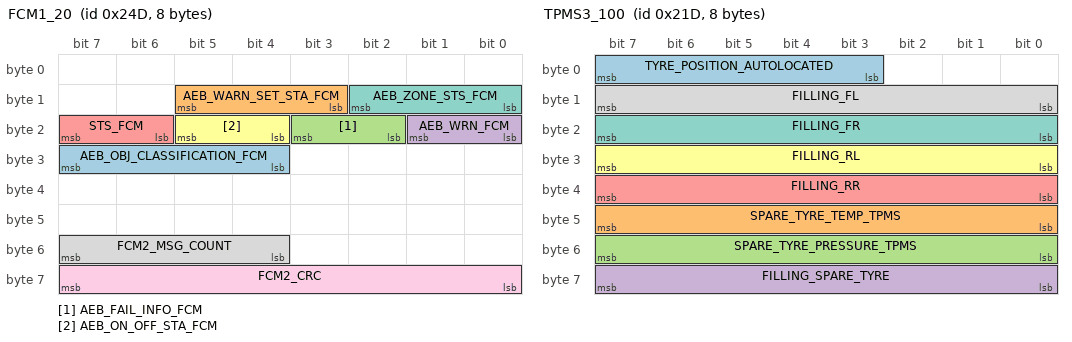
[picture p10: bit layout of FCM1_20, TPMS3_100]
BO_ 589 FCM1_20: 8 Vector__XXX
 SG_ AEB_OBJ_CLASSIFICATION_FCM : 28|4@1+ (1,0) [0|15] ""  SMART_CORE
 SG_ AEB_WARN_SET_STA_FCM : 11|3@1+ (1,0) [0|7] ""  SMART_CORE
 SG_ AEB_FAIL_INFO_FCM : 18|2@1+ (1,0) [0|3] ""  SMART_CORE
 SG_ AEB_WRN_FCM : 16|2@1+ (1,0) [0|3] ""  SMART_CORE
 SG_ STS_FCM : 22|2@1+ (1,0) [0|3] ""  SMART_CORE
 SG_ AEB_ON_OFF_STA_FCM : 20|2@1+ (1,0) [0|3] ""  SMART_CORE
 SG_ AEB_ZONE_STS_FCM : 8|3@1+ (1,0) [0|7] ""  SMART_CORE
 SG_ FCM2_MSG_COUNT : 52|4@1+ (1,0) [0|15] ""  SMART_CORE
 SG_ FCM2_CRC : 56|8@1+ (1,0) [0|255] ""  SMART_CORE

BO_ 592 SBW1_10: 8 Vector__XXX
 SG_ SBW1_MSG_COUNT : 52|4@1+ (1,0) [0|15] ""  SMART_CORE
 SG_ SBW_WARN : 8|8@1+ (1,0) [0|255] ""  SMART_CORE
 SG_ SBW1_CRC : 56|8@1+ (1,0) [0|255] ""  SMART_CORE
 SG_ SBW_FAULT : 3|2@1+ (1,0) [0|3] ""  SMART_CORE
 SG_ SBW_LEVER : 0|3@1+ (1,0) [0|7] ""  SMART_CORE

BO_ 971 IS4_500: 8 SMART_CORE
 SG_ STS_AUTO_HEAT : 62|1@1+ (1,0) [0|1] "" Vector__XXX
 SG_ STS_SEAT_POSITION_DISPLAY : 23|1@1+ (1,0) [0|1] "" Vector__XXX
 SG_ STS_AUTO_VENT : 63|1@1+ (1,0) [0|1] "" Vector__XXX
 SG_ APA_HMI_FBK : 56|6@1+ (1,0) [0|64] "" Vector__XXX
 SG_ PASSIVE_VENT_CONTROL_IS : 51|1@1+ (1,0) [0|1] "" Vector__XXX
 SG_ PASSIVE_VENT_TIMER : 48|3@1+ (1,0) [0|7] "" Vector__XXX
 SG_ PASSIVE_VENT_CYCLE : 46|2@1+ (1,0) [0|3] "" Vector__XXX
 SG_ STS_AUTO_DIP : 19|1@1+ (1,0) [0|1] "" Vector__XXX
 SG_ STS_EASY_ENTRY : 34|1@1+ (1,0) [0|1] "" Vector__XXX
 SG_ STS_EASY_EXIT : 35|1@1+ (1,0) [0|1] "" Vector__XXX
 SG_ STS_SEAT_PROFILE_IS : 24|2@1+ (1,0) [0|3] "" Vector__XXX
 SG_ STS_BS_ORVM_ADJUST : 18|1@1+ (1,0) [0|1] "" Vector__XXX
 SG_ STS_REV_GEAR_SIREN : 16|1@1+ (1,0) [0|1] "" Vector__XXX
 SG_ STS_AUTO_TURN_LAMP : 15|1@1+ (1,0) [0|1] "" Vector__XXX
 SG_ STS_HEAT_VENT_IS : 20|3@1+ (1,0) [0|7] "" Vector__XXX
 SG_ STS_SELECT_UNLOCK : 17|1@1+ (1,0) [0|1] "" Vector__XXX
 SG_ FR_SEAT_HEAT_VENT_LEVEL_IS : 32|2@1+ (1,0) [0|3] "" Vector__XXX
 SG_ FL_SEAT_HEAT_VENT_LEVEL_IS : 52|2@1+ (1,0) [0|3] "" Vector__XXX
 SG_ SET_TIRE_FILL_ASST_IS : 26|1@1+ (1,0) [0|1] "" Vector__XXX
 SG_ TPMS_AUTOLEARN_IS : 7|1@1+ (1,0) [0|1] "" Vector__XXX
 SG_ INST_ECO_INDEX : 8|7@1+ (1,0) [0|127] "" Vector__XXX
 SG_ ECO_INDEX : 0|7@1+ (1,0) [0|127] "" Vector__XXX
 SG_ RES_DRIVESCORE_INFO : 55|1@1+ (1,0) [0|1] "" Vector__XXX

BO_ 299 BMS22_100: 8 Vector__XXX
 SG_ BMS_IsolationResis : 32|16@1+ (0.01,0) [0|655.35] "Mohm"  SMART_CORE
 SG_ BMS_NC_Count : 16|16@1+ (1,0) [0|65534] ""  SMART_CORE
 SG_ BMS_FC_Count : 0|16@1+ (1,0) [0|65534] ""  SMART_CORE

BO_ 1004 BMS20_100: 8 Vector__XXX
 SG_ BMS_CellVoltage44 m7 : 14|10@1+ (5,0) [0|5000] "mV"  SMART_CORE
 SG_ BMS_CellVoltage43 m7 : 4|10@1+ (5,0) [0|5000] "mV"  SMART_CORE
 SG_ BMS_CellVoltage42 m6 : 54|10@1+ (5,0) [0|5000] "mV"  SMART_CORE
 SG_ BMS_CellVoltage41 m6 : 44|10@1+ (5,0) [0|5000] "mV"  SMART_CORE
 SG_ BMS_CellVoltage40 m6 : 34|10@1+ (5,0) [0|5000] "mV"  SMART_CORE
 SG_ BMS_CellVoltage4 m0 : 34|10@1+ (5,0) [0|5000] "mV"  SMART_CORE
 SG_ BMS_CellVoltage39 m6 : 24|10@1+ (5,0) [0|5000] "mV"  SMART_CORE
 SG_ BMS_CellVoltage38 m6 : 14|10@1+ (5,0) [0|5000] "mV"  SMART_CORE
 SG_ BMS_CellVoltage37 m6 : 4|10@1+ (5,0) [0|5000] "mV"  SMART_CORE
 SG_ BMS_CellVoltage36 m5 : 54|10@1+ (5,0) [0|5000] "mV"  SMART_CORE
 SG_ BMS_CellVoltage35 m5 : 44|10@1+ (5,0) [0|5000] "mV"  SMART_CORE
 SG_ BMS_CellVoltage34 m5 : 34|10@1+ (5,0) [0|5000] "mV"  SMART_CORE
 SG_ BMS_CellVoltage33 m5 : 24|10@1+ (5,0) [0|5000] "mV"  SMART_CORE
 SG_ BMS_CellVoltage32 m5 : 14|10@1+ (5,0) [0|5000] "mV"  SMART_CORE
 SG_ BMS_CellVoltage31 m5 : 4|10@1+ (5,0) [0|5000] "mV"  SMART_CORE
 SG_ BMS_CellVoltage30 m4 : 54|10@1+ (5,0) [0|5000] "mV"  SMART_CORE
 SG_ BMS_CellVoltage3 m0 : 24|10@1+ (5,0) [0|5000] "mV"  SMART_CORE
 SG_ BMS_CellVoltage29 m4 : 44|10@1+ (5,0) [0|5000] "mV"  SMART_CORE
 SG_ BMS_CellVoltage28 m4 : 34|10@1+ (5,0) [0|5000] "mV"  SMART_CORE
 SG_ BMS_CellVoltage27 m4 : 24|10@1+ (5,0) [0|5000] "mV"  SMART_CORE
 SG_ BMS_CellVoltage26 m4 : 14|10@1+ (5,0) [0|5000] "mV"  SMART_CORE
 SG_ BMS_CellVoltage25 m4 : 4|10@1+ (5,0) [0|5000] "mV"  SMART_CORE
 SG_ BMS_CellVoltage24 m3 : 54|10@1+ (5,0) [0|5000] "mV"  SMART_CORE
 SG_ BMS_CellVoltage23 m3 : 44|10@1+ (5,0) [0|5000] "mV"  SMART_CORE
 SG_ BMS_CellVoltage22 m3 : 34|10@1+ (5,0) [0|5000] "mV"  SMART_CORE
 SG_ BMS_CellVoltage21 m3 : 24|10@1+ (5,0) [0|5000] "mV"  SMART_CORE
 SG_ BMS_CellVoltage20 m3 : 14|10@1+ (5,0) [0|5000] "mV"  SMART_CORE
 SG_ BMS_CellVoltage96 m15 : 54|10@1+ (5,0) [0|5000] "mV"  SMART_CORE
 SG_ BMS_CellVoltage95 m15 : 44|10@1+ (5,0) [0|5000] "mV"  SMART_CORE
 SG_ BMS_CellVoltage94 m15 : 34|10@1+ (5,0) [0|5000] "mV"  SMART_CORE
 SG_ BMS_CellVoltage93 m15 : 24|10@1+ (5,0) [0|5000] "mV"  SMART_CORE
 SG_ BMS_CellVoltage92 m15 : 14|10@1+ (5,0) [0|5000] "mV"  SMART_CORE
 SG_ BMS_CellVoltage91 m15 : 4|10@1+ (5,0) [0|5000] "mV"  SMART_CORE
 SG_ BMS_CellVoltage90 m14 : 54|10@1+ (5,0) [0|5000] "mV"  SMART_CORE
 SG_ BMS_CellVoltage9 m1 : 24|10@1+ (5,0) [0|5000] "mV"  SMART_CORE
 SG_ BMS_CellVoltage89 m14 : 44|10@1+ (5,0) [0|5000] "mV"  SMART_CORE
 SG_ BMS_CellVoltage88 m14 : 34|10@1+ (5,0) [0|5000] "mV"  SMART_CORE
 SG_ BMS_CellVoltage87 m14 : 24|10@1+ (5,0) [0|5000] "mV"  SMART_CORE
 SG_ BMS_CellVoltage86 m14 : 14|10@1+ (5,0) [0|5000] "mV"  SMART_CORE
 SG_ BMS_CellVoltage85 m14 : 4|10@1+ (5,0) [0|5000] "mV"  SMART_CORE
 SG_ BMS_CellVoltage84 m13 : 54|10@1+ (5,0) [0|5000] "mV"  SMART_CORE
 SG_ BMS_CellVoltage83 m13 : 44|10@1+ (5,0) [0|5000] "mV"  SMART_CORE
 SG_ BMS_CellVoltage82 m13 : 34|10@1+ (5,0) [0|5000] "mV"  SMART_CORE
 SG_ BMS_CellVoltage81 m13 : 24|10@1+ (5,0) [0|5000] "mV"  SMART_CORE
 SG_ BMS_CellVoltage80 m13 : 14|10@1+ (5,0) [0|5000] "mV"  SMART_CORE
 SG_ BMS_CellVoltage8 m1 : 14|10@1+ (5,0) [0|5000] "mV"  SMART_CORE
 SG_ BMS_CellVoltage79 m13 : 4|10@1+ (5,0) [0|5000] "mV"  SMART_CORE
 SG_ BMS_CellVoltage78 m12 : 54|10@1+ (5,0) [0|5000] "mV"  SMART_CORE
 SG_ BMS_CellVoltage77 m12 : 44|10@1+ (5,0) [0|5000] "mV"  SMART_CORE
 SG_ BMS_CellVoltage76 m12 : 34|10@1+ (5,0) [0|5000] "mV"  SMART_CORE
 SG_ BMS_CellVoltage75 m12 : 24|10@1+ (5,0) [0|5000] "mV"  SMART_CORE
 SG_ BMS_CellVoltage74 m12 : 14|10@1+ (5,0) [0|5000] "mV"  SMART_CORE
 SG_ BMS_CellVoltage73 m12 : 4|10@1+ (5,0) [0|5000] "mV"  SMART_CORE
 SG_ BMS_CellVoltage72 m11 : 54|10@1+ (5,0) [0|5000] "mV"  SMART_CORE
 SG_ BMS_CellVoltage71 m11 : 44|10@1+ (5,0) [0|5000] "mV"  SMART_CORE
 SG_ BMS_CellVoltage70 m11 : 34|10@1+ (5,0) [0|5000] "mV"  SMART_CORE
 SG_ BMS_CellVoltage7 m1 : 4|10@1+ (5,0) [0|5000] "mV"  SMART_CORE
 SG_ BMS_CellVoltage69 m11 : 24|10@1+ (5,0) [0|5000] "mV"  SMART_CORE
 SG_ BMS_CellVoltage68 m11 : 14|10@1+ (5,0) [0|5000] "mV"  SMART_CORE
 SG_ BMS_CellVoltage67 m11 : 4|10@1+ (5,0) [0|5000] "mV"  SMART_CORE
 SG_ BMS_CellVoltage66 m10 : 54|10@1+ (5,0) [0|5000] "mV"  SMART_CORE
 SG_ BMS_CellVoltage65 m10 : 44|10@1+ (5,0) [0|5000] "mV"  SMART_CORE
 SG_ BMS_CellVoltage64 m10 : 34|10@1+ (5,0) [0|5000] "mV"  SMART_CORE
 SG_ BMS_CellVoltage63 m10 : 24|10@1+ (5,0) [0|5000] "mV"  SMART_CORE
 SG_ BMS_CellVoltage62 m10 : 14|10@1+ (5,0) [0|5000] "mV"  SMART_CORE
 SG_ BMS_CellVoltage61 m10 : 4|10@1+ (5,0) [0|5000] "mV"  SMART_CORE
 SG_ BMS_CellVoltage60 m9 : 54|10@1+ (5,0) [0|5000] "mV"  SMART_CORE
 SG_ BMS_CellVoltage6 m0 : 54|10@1+ (5,0) [0|5000] "mV"  SMART_CORE
 SG_ BMS_CellVoltage59 m9 : 44|10@1+ (5,0) [0|5000] "mV"  SMART_CORE
 SG_ BMS_CellVoltage58 m9 : 34|10@1+ (5,0) [0|5000] "mV"  SMART_CORE
 SG_ BMS_CellVoltage57 m9 : 24|10@1+ (5,0) [0|5000] "mV"  SMART_CORE
 SG_ BMS_CellVoltage56 m9 : 14|10@1+ (5,0) [0|5000] "mV"  SMART_CORE
 SG_ BMS_CellVoltage55 m9 : 4|10@1+ (5,0) [0|5000] "mV"  SMART_CORE
 SG_ BMS_CellVoltage54 m8 : 54|10@1+ (5,0) [0|5000] "mV"  SMART_CORE
 SG_ BMS_CellVoltage53 m8 : 44|10@1+ (5,0) [0|5000] "mV"  SMART_CORE
 SG_ BMS_CellVoltage52 m8 : 34|10@1+ (5,0) [0|5000] "mV"  SMART_CORE
 SG_ BMS_CellVoltage51 m8 : 24|10@1+ (5,0) [0|5000] "mV"  SMART_CORE
 SG_ BMS_CellVoltage50 m8 : 14|10@1+ (5,0) [0|5000] "mV"  SMART_CORE
 SG_ BMS_CellVoltage5 m0 : 44|10@1+ (5,0) [0|5000] "mV"  SMART_CORE
 SG_ BMS_CellVoltage49 m8 : 4|10@1+ (5,0) [0|5000] "mV"  SMART_CORE
 SG_ BMS_CellVoltage48 m7 : 54|10@1+ (5,0) [0|5000] "mV"  SMART_CORE
 SG_ BMS_CellVoltage47 m7 : 44|10@1+ (5,0) [0|5000] "mV"  SMART_CORE
 SG_ BMS_CellVoltage46 m7 : 34|10@1+ (5,0) [0|5000] "mV"  SMART_CORE
 SG_ BMS_CellVoltage45 m7 : 24|10@1+ (5,0) [0|5000] "mV"  SMART_CORE
 SG_ BMS_CellVoltage2 m0 : 14|10@1+ (5,0) [0|5000] "mV"  SMART_CORE
 SG_ BMS_CellVoltage19 m3 : 4|10@1+ (5,0) [0|5000] "mV"  SMART_CORE
 SG_ BMS_CellVoltage18 m2 : 54|10@1+ (5,0) [0|5000] "mV"  SMART_CORE
 SG_ BMS_CellVoltage17 m2 : 44|10@1+ (5,0) [0|5000] "mV"  SMART_CORE
 SG_ BMS_CellVoltage16 m2 : 34|10@1+ (5,0) [0|5000] "mV"  SMART_CORE
 SG_ BMS_CellVoltage15 m2 : 24|10@1+ (5,0) [0|5000] "mV"  SMART_CORE
 SG_ BMS_CellVoltage14 m2 : 14|10@1+ (5,0) [0|5000] "mV"  SMART_CORE
 SG_ BMS_CellVoltage13 m2 : 4|10@1+ (5,0) [0|5000] "mV"  SMART_CORE
 SG_ BMS_CellVoltage12 m1 : 54|10@1+ (5,0) [0|5000] "mV"  SMART_CORE
 SG_ BMS_CellVoltage11 m1 : 44|10@1+ (5,0) [0|5000] "mV"  SMART_CORE
 SG_ BMS_CellVoltage10 m1 : 34|10@1+ (5,0) [0|5000] "mV"  SMART_CORE
 SG_ BMS_CellVoltage1 m0 : 4|10@1+ (5,0) [0|5000] "mV"  SMART_CORE
 SG_ BMS_CellVoltage_Index M : 0|4@1+ (1,0) [0|15] ""  SMART_CORE

BO_ 770 CCM1_200: 8 Vector__XXX
 SG_ DISCHARGE_LINE_PRESSURE : 52|9@1+ (0.1,0) [0|51.1] "bar"  SMART_CORE
 SG_ STS_PTC_HEATER : 16|2@1+ (1,0) [0|3] ""  SMART_CORE
 SG_ REQ_ACC_ON : 47|1@1+ (1,0) [0|1] ""  SMART_CORE
 SG_ COMPRESSURE_SPD : 0|16@1+ (1,0) [0|65534] "rpm"  SMART_CORE

BO_ 1849 RVC_DIAG_RES: 8 Vector__XXX
 SG_ DIAG_RVC_RES_DATA : 0|64@1+ (1,0) [0|1.8446744074] ""  SMART_CORE

BO_ 1841 RVC_DIAG_REQ: 8 SMART_CORE
 SG_ DIAG_RVC_REQ_DATA : 0|64@1+ (1,0) [0|1.8446744074E+019] "" Vector__XXX

BO_ 541 TPMS3_100: 8 Vector__XXX
 SG_ TYRE_POSITION_AUTOLOCATED : 3|5@1+ (1,0) [0|32] ""  SMART_CORE
 SG_ SPARE_TYRE_TEMP_TPMS : 40|8@1+ (1,-40) [-40|214] "deg C"  SMART_CORE
 SG_ SPARE_TYRE_PRESSURE_TPMS : 48|8@1+ (0.25,0) [0|63.5] "Psi"  SMART_CORE
 SG_ FILLING_SPARE_TYRE : 56|8@1+ (1,0) [0|255] ""  SMART_CORE
 SG_ FILLING_RR : 32|8@1+ (1,0) [0|255] ""  SMART_CORE
 SG_ FILLING_RL : 24|8@1+ (1,0) [0|255] ""  SMART_CORE
 SG_ FILLING_FR : 16|8@1+ (1,0) [0|255] ""  SMART_CORE
 SG_ FILLING_FL : 8|8@1+ (1,0) [0|255] ""  SMART_CORE

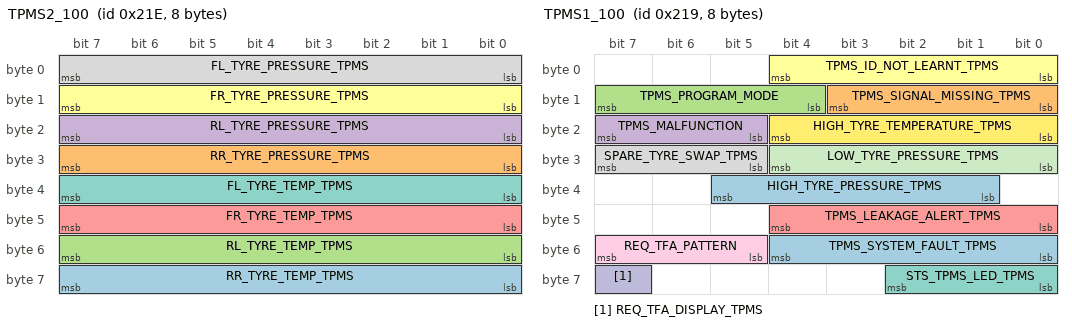
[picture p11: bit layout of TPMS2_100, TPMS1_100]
BO_ 542 TPMS2_100: 8 Vector__XXX
 SG_ RR_TYRE_TEMP_TPMS : 56|8@1+ (1,-40) [-40|214] "deg C"  SMART_CORE
 SG_ RR_TYRE_PRESSURE_TPMS : 24|8@1+ (0.25,0) [0|63.5] "Psi"  SMART_CORE
 SG_ RL_TYRE_TEMP_TPMS : 48|8@1+ (1,-40) [-40|214] "deg C"  SMART_CORE
 SG_ RL_TYRE_PRESSURE_TPMS : 16|8@1+ (0.25,0) [0|63.5] "Psi"  SMART_CORE
 SG_ FR_TYRE_TEMP_TPMS : 40|8@1+ (1,-40) [-40|214] "deg C"  SMART_CORE
 SG_ FR_TYRE_PRESSURE_TPMS : 8|8@1+ (0.25,0) [0|63.5] "Psi"  SMART_CORE
 SG_ FL_TYRE_TEMP_TPMS : 32|8@1+ (1,-40) [-40|214] "deg C"  SMART_CORE
 SG_ FL_TYRE_PRESSURE_TPMS : 0|8@1+ (0.25,0) [0|63.5] "Psi"  SMART_CORE

BO_ 537 TPMS1_100: 8 Vector__XXX
 SG_ TPMS_SYSTEM_FAULT_TPMS : 48|5@1+ (1,0) [0|31] ""  SMART_CORE
 SG_ TPMS_SIGNAL_MISSING_TPMS : 8|4@1+ (1,0) [0|15] ""  SMART_CORE
 SG_ TPMS_PROGRAM_MODE : 12|4@1+ (1,0) [0|15] ""  SMART_CORE
 SG_ TPMS_MALFUNCTION : 21|3@1+ (1,0) [0|7] ""  SMART_CORE
 SG_ TPMS_LEAKAGE_ALERT_TPMS : 40|5@1+ (1,0) [0|31] ""  SMART_CORE
 SG_ TPMS_ID_NOT_LEARNT_TPMS : 0|5@1+ (1,0) [0|31] ""  SMART_CORE
 SG_ STS_TPMS_LED_TPMS : 56|3@1+ (1,0) [0|3] ""  SMART_CORE
 SG_ SPARE_TYRE_SWAP_TPMS : 29|3@1+ (1,0) [0|4] ""  SMART_CORE
 SG_ REQ_TFA_PATTERN : 53|3@1+ (1,0) [0|5] "" Vector__XXX
 SG_ REQ_TFA_DISPLAY_TPMS : 63|1@1+ (1,0) [0|1] ""  SMART_CORE
 SG_ LOW_TYRE_PRESSURE_TPMS : 24|5@1+ (1,0) [0|31] ""  SMART_CORE
 SG_ HIGH_TYRE_TEMPERATURE_TPMS : 16|5@1+ (1,0) [0|31] ""  SMART_CORE
 SG_ HIGH_TYRE_PRESSURE_TPMS : 33|5@1+ (1,0) [0|31] ""  SMART_CORE

BO_ 1872 IS_DIAG_REQ: 8 Vector__XXX
 SG_ DIAG_IS_REQ_DATA : 0|64@1+ (1,0) [0|1.8446744074E+019] ""  SMART_CORE

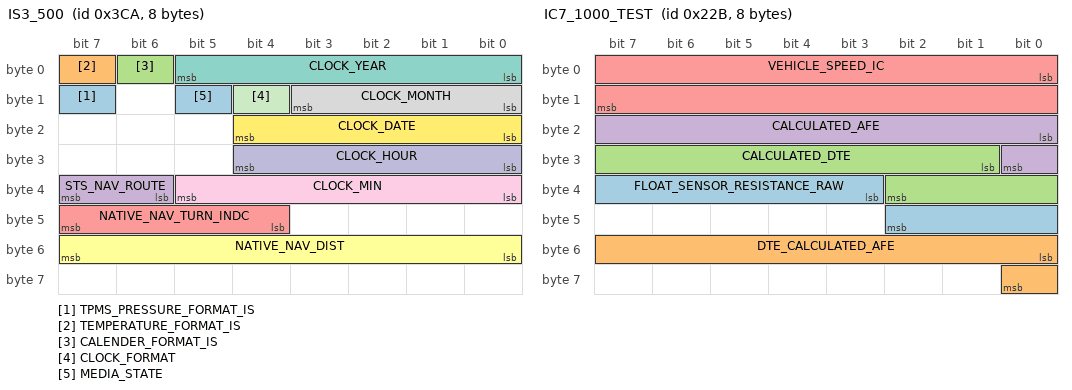
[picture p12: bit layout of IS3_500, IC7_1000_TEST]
BO_ 970 IS3_500: 8 SMART_CORE
 SG_ TPMS_PRESSURE_FORMAT_IS : 15|1@1+ (1,0) [0|0] "" Vector__XXX
 SG_ TEMPERATURE_FORMAT_IS : 7|1@1+ (1,0) [0|0] "" Vector__XXX
 SG_ CALENDER_FORMAT_IS : 6|1@1+ (1,0) [0|0] "" Vector__XXX
 SG_ STS_NAV_ROUTE : 38|2@1+ (1,0) [0|3] "" Vector__XXX
 SG_ NATIVE_NAV_TURN_INDC : 44|4@1+ (1,0) [0|15] "" Vector__XXX
 SG_ NATIVE_NAV_DIST : 48|8@1+ (10,0) [0|500] "Mts" Vector__XXX
 SG_ CLOCK_YEAR : 0|6@1+ (1,2000) [2016|2063] "" Vector__XXX
 SG_ CLOCK_MONTH : 8|4@1+ (1,0) [0|12] "" Vector__XXX
 SG_ CLOCK_MIN : 32|6@1+ (1,0) [0|59] "Minute" Vector__XXX
 SG_ CLOCK_HOUR : 24|5@1+ (1,0) [0|23] "Hour" Vector__XXX
 SG_ CLOCK_FORMAT : 12|1@1+ (1,0) [0|1] "" Vector__XXX
 SG_ CLOCK_DATE : 16|5@1+ (1,0) [0|31] "" Vector__XXX
 SG_ MEDIA_STATE : 13|1@1+ (1,0) [0|1] "" Vector__XXX

BO_ 1880 IS_DIAG_RES: 8 SMART_CORE
 SG_ DIAG_IS_RES_DATA : 0|64@1+ (1,0) [0|1.8446744074E+019] "" Vector__XXX

BO_ 769 EMS9_500: 8 Vector__XXX
 SG_ REMAINING_OIL_LIFE_PERCENT : 48|7@1+ (1,0) [0|100] "%"  SMART_CORE
 SG_ DPF_ANAMOLY_RESERVED : 11|4@1- (1,0) [0|0] ""  SMART_CORE
 SG_ DPF_BAD_REGEN_EFFICIENCY : 6|2@1- (1,0) [0|3] ""  SMART_CORE
 SG_ BATT_OCV : 55|9@1+ (20,6000) [6000|16000] "mV"  SMART_CORE

BO_ 555 IC7_1000_TEST: 8 SMART_CORE
 SG_ FLOAT_SENSOR_RESISTANCE_RAW : 35|8@1+ (1,0) [0|255] "" Vector__XXX
 SG_ DTE_CALCULATED_AFE : 48|9@1+ (0.1,0) [0|51] "kmpl" Vector__XXX
 SG_ CALCULATED_DTE : 25|10@1+ (1,0) [0|999] "km" Vector__XXX
 SG_ CALCULATED_AFE : 16|9@1+ (0.1,0) [0|51] "kmpl" Vector__XXX
 SG_ VEHICLE_SPEED_IC : 0|16@1+ (0.015625,0) [0|300] "kmph" Vector__XXX

BO_ 547 IC6_1000_TEST: 8 SMART_CORE
 SG_ CALCULATED_AFE_GD : 52|9@1+ (0.1,0) [0|51] "KMPL" Vector__XXX
 SG_ FLOAT_RESISTANCE_FILTER : 42|10@1+ (0.00489,0) [0|5] "Volt" Vector__XXX
 SG_ FLOAT_RESISTANCE_RAW : 32|10@1+ (0.00489,0) [0|5] "Volt" Vector__XXX
 SG_ FUEL_LVL_DTE_FILTER : 16|16@1+ (1,0) [0|65535] "" Vector__XXX
 SG_ FUEL_LVL_RAW : 0|16@1+ (1,0) [0|65534] "" Vector__XXX

BO_ 548 IC4_1000_TEST: 8 SMART_CORE
 SG_ FUEL_CONSMP_ACCUMULATED : 48|16@1+ (1,0) [0|65534] "ml" Vector__XXX
 SG_ AFE_ACCUMULATED_FUEL_CONSMP : 16|13@1+ (1,0) [0|5000] "ml" Vector__XXX
 SG_ AFE_ACCUMULATED_DISTANCE : 0|11@1+ (0.01,0) [0|20] "km" Vector__XXX

BO_ 2016 EMS_DIAG_REQ: 8 SMART_CORE
 SG_ DIAG_EMS_REQ_DATA : 0|64@1+ (1,0) [0|1.8446744074E+019] "" Vector__XXX

BO_ 2024 EMS_DIAG_RES: 8 Vector__XXX
 SG_ DIAG_EMS_RES_DATA : 0|64@1+ (1,0) [0|1.8446744074] ""  SMART_CORE

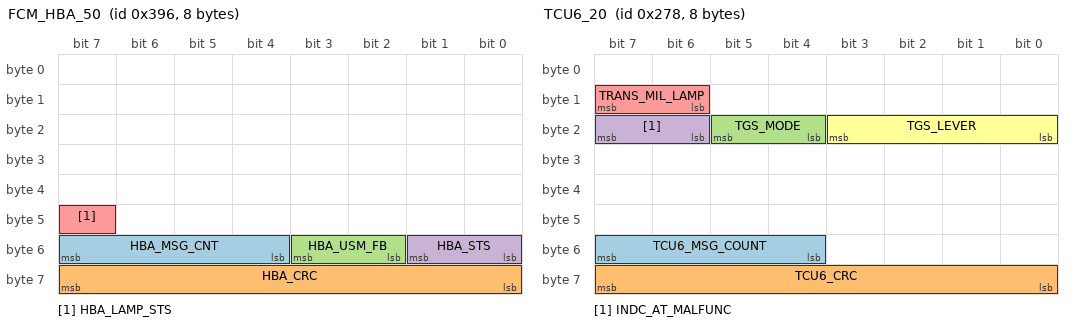
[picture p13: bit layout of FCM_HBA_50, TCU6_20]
BO_ 918 FCM_HBA_50: 8 Vector__XXX
 SG_ HBA_MSG_CNT : 52|4@1+ (1,0) [0|15] ""  SMART_CORE
 SG_ HBA_CRC : 56|8@1+ (1,0) [0|255] ""  SMART_CORE
 SG_ HBA_USM_FB : 50|2@1+ (1,0) [0|2] ""  SMART_CORE
 SG_ HBA_STS : 48|2@1+ (1,0) [0|3] ""  SMART_CORE
 SG_ HBA_LAMP_STS : 47|1@1+ (1,0) [0|1] ""  SMART_CORE

BO_ 902 ACC2_500: 8 Vector__XXX
 SG_ ACC_HVIL_STATUS : 44|2@1+ (1,0) [0|3] ""  SMART_CORE
 SG_ COMPRESSOR_TEMPERATURE : 8|8@1+ (1,-50) [-50|150] "degC"  SMART_CORE
 SG_ ACC_CTRL_OUTPUT_POWER : 16|16@1+ (1,0) [0|4000] "W"  SMART_CORE

BO_ 901 ACC1_500: 8 Vector__XXX
 SG_ STS_ACC_COMPRESSOR : 48|1@1+ (1,0) [0|1] ""  SMART_CORE
 SG_ ACC_CONTROLLER_OVERHEAT_FAULT : 46|1@1+ (1,0) [0|1] ""  SMART_CORE
 SG_ ACC_OVERCURRENT_FAULT : 45|1@1+ (1,0) [0|1] ""  SMART_CORE
 SG_ ACC_OVERVOLTAGE_FAULT : 44|1@1+ (1,0) [0|1] ""  SMART_CORE
 SG_ ACC_UNDERVOLTAGE_FAULT : 43|1@1+ (1,0) [0|1] ""  SMART_CORE
 SG_ ACC_MOTOR_OVERHEAT_FAULT : 42|1@1+ (1,0) [0|1] ""  SMART_CORE
 SG_ ACC_INPUT_DC_CURRENT : 32|6@1+ (1,0) [0|63] "A"  SMART_CORE
 SG_ ACC_COM_FAULT : 49|1@1+ (1,0) [0|1] ""  SMART_CORE

BO_ 632 TCU6_20: 8 Vector__XXX
 SG_ TCU6_MSG_COUNT : 52|4@1+ (1,0) [0|15] ""  SMART_CORE
 SG_ TCU6_CRC : 56|8@1+ (1,0) [0|255] ""  SMART_CORE
 SG_ TGS_MODE : 20|2@1+ (1,0) [0|3] ""  SMART_CORE
 SG_ INDC_AT_MALFUNC : 22|2@1+ (1,0) [0|2] ""  SMART_CORE
 SG_ TRANS_MIL_LAMP : 14|2@1+ (1,0) [0|2] ""  SMART_CORE
 SG_ TGS_LEVER : 16|4@1+ (1,0) [0|15] ""  SMART_CORE

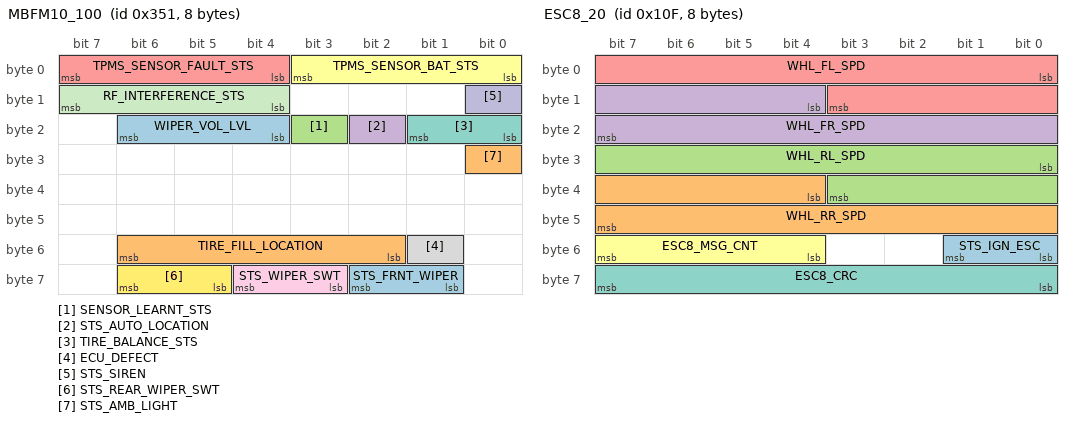
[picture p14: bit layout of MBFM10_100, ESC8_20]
BO_ 849 MBFM10_100: 8 Vector__XXX
 SG_ WIPER_VOL_LVL : 20|3@1+ (1,0) [0|7] ""  SMART_CORE
 SG_ TIRE_FILL_LOCATION : 50|5@1+ (1,0) [0|31] ""  SMART_CORE
 SG_ SENSOR_LEARNT_STS : 19|1@1+ (1,0) [0|1] ""  SMART_CORE
 SG_ STS_AUTO_LOCATION : 18|1@1+ (1,0) [0|1] ""  SMART_CORE
 SG_ TPMS_SENSOR_FAULT_STS : 4|4@1+ (1,0) [0|15] ""  SMART_CORE
 SG_ TPMS_SENSOR_BAT_STS : 0|4@1+ (1,0) [0|15] ""  SMART_CORE
 SG_ TIRE_BALANCE_STS : 16|2@1+ (1,0) [0|3] ""  SMART_CORE
 SG_ ECU_DEFECT : 49|1@1+ (1,0) [0|1] ""  SMART_CORE
 SG_ STS_WIPER_SWT : 59|2@1+ (1,0) [0|3] ""  SMART_CORE
 SG_ STS_SIREN : 8|1@1+ (1,0) [0|1] ""  SMART_CORE
 SG_ RF_INTERFERENCE_STS : 12|4@1+ (1,0) [0|15] ""  SMART_CORE
 SG_ STS_REAR_WIPER_SWT : 61|2@1+ (1,0) [0|3] ""  SMART_CORE
 SG_ STS_FRNT_WIPER : 57|2@1+ (1,0) [0|3] ""  SMART_CORE
 SG_ STS_AMB_LIGHT : 24|1@1+ (1,0) [0|1] ""  SMART_CORE

BO_ 2020 ESC_DIAG_REQ: 8 SMART_CORE
 SG_ DIAG_ESC_REQ_DATA : 0|64@1+ (1,0) [0|1.8446744074E+019] "" Vector__XXX

BO_ 2028 ESC_DIAG_RES: 8 Vector__XXX
 SG_ DIAG_ESC_RES_DATA : 0|64@1+ (1,0) [0|1.8446744074E+019] ""  SMART_CORE

BO_ 369 ESC10_20: 8 Vector__XXX
 SG_ MASTER_CYL_PRESSURE : 0|16@1+ (0.05,-40) [-40|400] "Bar"  SMART_CORE

BO_ 368 ESC7_20: 8 Vector__XXX
 SG_ YAW_RATE : 32|16@1+ (0.005,-163.84) [-163.84|163.83] "deg/sec"  SMART_CORE
 SG_ LONG_ACCEL : 16|16@1+ (0.000127465,-4.1768) [-4.1768|4.1765] "g"  SMART_CORE
 SG_ LATTERAL_ACCEL : 0|16@1+ (0.000127465,-4.1768) [-4.1768|4.1765] "g"  SMART_CORE
 SG_ ESC7_MSG_CNT : 52|4@1+ (1,0) [0|15] ""  SMART_CORE
 SG_ ESC7_CRC : 56|8@1+ (1,0) [0|255] ""  SMART_CORE

BO_ 271 ESC8_20: 8 Vector__XXX
 SG_ STS_IGN_ESC : 48|2@1+ (1,0) [0|3] ""  SMART_CORE
 SG_ WHL_RR_SPD : 36|12@1+ (1,0) [0|4095] "rpm"  SMART_CORE
 SG_ WHL_RL_SPD : 24|12@1+ (1,0) [0|4095] "rpm"  SMART_CORE
 SG_ WHL_FR_SPD : 12|12@1+ (1,0) [0|4095] "rpm"  SMART_CORE
 SG_ WHL_FL_SPD : 0|12@1+ (1,0) [0|4095] "rpm"  SMART_CORE
 SG_ ESC8_MSG_CNT : 52|4@1+ (1,0) [0|15] ""  SMART_CORE
 SG_ ESC8_CRC : 56|8@1+ (1,0) [0|255] ""  SMART_CORE

BO_ 544 IS1_100: 8 SMART_CORE
 SG_ FRONT_RIGHT_SET_TEMP_IS : 0|8@1+ (0.5,-40) [-40|87.5] "Deg C" Vector__XXX
 SG_ FRONT_LEFT_SET_TEMP_IS : 8|8@1+ (0.5,-40) [-40|87.5] "Deg C" Vector__XXX
 SG_ DISP_DUAL_IS : 59|2@1+ (1,0) [0|3] "" Vector__XXX
 SG_ VALET_MODE_STATE : 57|2@1+ (1,0) [0|3] "" Vector__XXX
 SG_ STS_REAR_DEFOG_IS : 42|2@1+ (1,0) [0|3] "" Vector__XXX
 SG_ STS_REAR_AC_IS : 54|2@1+ (1,0) [0|2] "" Vector__XXX
 SG_ MEM_DISP_IS : 32|4@1+ (1,0) [0|15] "" Vector__XXX
 SG_ REQ_TRIP_RESET : 56|1@1+ (1,0) [0|1] "" Vector__XXX
 SG_ ILLUMINATION_LEVEL : 24|4@1+ (1,0) [0|15] "" Vector__XXX
 SG_ FRESH_RECIRC_IS : 30|2@1+ (1,0) [0|2] "" Vector__XXX
 SG_ IS_RVC_VIDEO_ENBL : 51|3@1+ (1,0) [0|7] "" Vector__XXX
 SG_ CMD_USER_INPUT1 : 48|3@1+ (1,0) [0|6] "" Vector__XXX
 SG_ RESET_AFE : 63|1@1+ (1,0) [0|1] "" Vector__XXX
 SG_ DRL_EN_SW : 62|1@1+ (1,0) [0|1] "" Vector__XXX
 SG_ DISP_OFF_IS : 40|2@1+ (1,0) [0|2] "" Vector__XXX
 SG_ DISP_ECON_IS : 46|2@1+ (1,0) [0|2] "" Vector__XXX
 SG_ DISP_BLOWER_IS : 20|4@1+ (1,0) [0|14] "" Vector__XXX
 SG_ DISP_AUTO_IS : 28|2@1+ (1,0) [0|2] "" Vector__XXX
 SG_ AC_REQ_IS : 44|2@1+ (1,0) [0|3] "" Vector__XXX
 SG_ DISP_MODE_IS : 16|4@1+ (1,0) [0|14] "" Vector__XXX

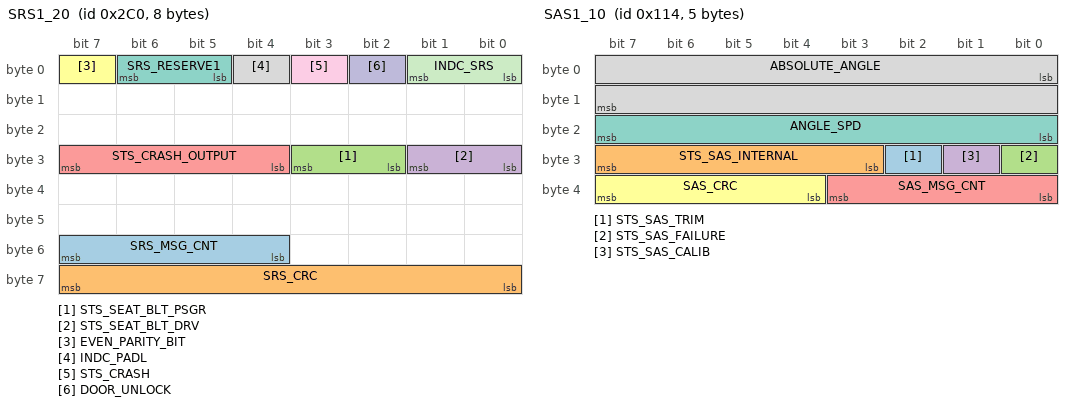
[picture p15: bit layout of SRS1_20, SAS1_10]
BO_ 704 SRS1_20: 8 Vector__XXX
 SG_ SRS_MSG_CNT : 52|4@1+ (1,0) [0|15] ""  SMART_CORE
 SG_ SRS_CRC : 56|8@1+ (1,0) [0|255] ""  SMART_CORE
 SG_ STS_SEAT_BLT_PSGR : 26|2@1+ (1,0) [0|3] ""  SMART_CORE
 SG_ STS_SEAT_BLT_DRV : 24|2@1+ (1,0) [0|3] ""  SMART_CORE
 SG_ STS_CRASH_OUTPUT : 28|4@1+ (1,0) [0|15] ""  SMART_CORE
 SG_ EVEN_PARITY_BIT : 7|1@1+ (1,0) [0|1] ""  SMART_CORE
 SG_ SRS_RESERVE1 : 5|2@1+ (1,0) [0|3] ""  SMART_CORE
 SG_ INDC_PADL : 4|1@1+ (1,0) [0|1] ""  SMART_CORE
 SG_ STS_CRASH : 3|1@1+ (1,0) [0|1] ""  SMART_CORE
 SG_ DOOR_UNLOCK : 2|1@1+ (1,0) [0|1] ""  SMART_CORE
 SG_ INDC_SRS : 0|2@1+ (1,0) [0|3] ""  SMART_CORE

BO_ 276 SAS1_10: 5 Vector__XXX
 SG_ STS_SAS_TRIM : 26|1@1+ (1,0) [0|1] ""  SMART_CORE
 SG_ STS_SAS_INTERNAL : 27|5@1+ (1,0) [0|31] ""  SMART_CORE
 SG_ STS_SAS_FAILURE : 24|1@1+ (1,0) [0|1] ""  SMART_CORE
 SG_ STS_SAS_CALIB : 25|1@1+ (1,0) [0|1] ""  SMART_CORE
 SG_ SAS_MSG_CNT : 32|4@1+ (1,0) [0|15] ""  SMART_CORE
 SG_ SAS_CRC : 36|4@1+ (1,0) [0|15] ""  SMART_CORE
 SG_ ANGLE_SPD : 16|8@1+ (4,0) [0|1020] "deg/sec/bit"  SMART_CORE
 SG_ ABSOLUTE_ANGLE : 0|16@1- (0.1,0) [-780|779.9] "Deg/bit"  SMART_CORE

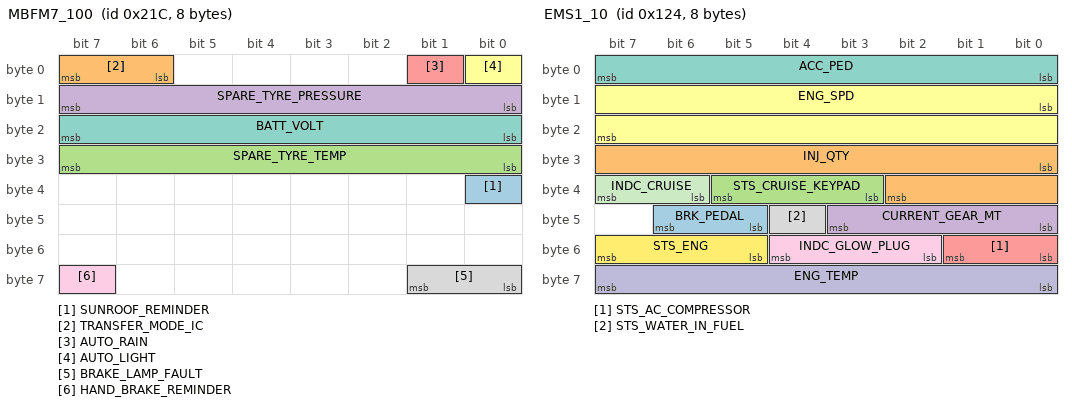
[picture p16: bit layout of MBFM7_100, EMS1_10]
BO_ 540 MBFM7_100: 8 Vector__XXX
 SG_ SUNROOF_REMINDER : 32|1@1+ (1,0) [0|1] ""  SMART_CORE
 SG_ TRANSFER_MODE_IC : 6|2@1+ (1,0) [0|3] "" Vector__XXX
 SG_ SPARE_TYRE_TEMP : 24|8@1+ (1,-40) [-40|214] "deg C"  SMART_CORE
 SG_ SPARE_TYRE_PRESSURE : 8|8@1+ (0.25,0) [0|63.5] "Psi"  SMART_CORE
 SG_ AUTO_RAIN : 1|1@1+ (1,0) [0|1] ""  SMART_CORE
 SG_ AUTO_LIGHT : 0|1@1+ (1,0) [0|1] ""  SMART_CORE
 SG_ BATT_VOLT : 16|8@1+ (0.25,0) [0|63.5] "volt"  SMART_CORE
 SG_ BRAKE_LAMP_FAULT : 56|2@1- (1,0) [0|0] ""  SMART_CORE
 SG_ HAND_BRAKE_REMINDER : 63|1@1+ (1,0) [0|1] ""  SMART_CORE

BO_ 306 EMS14_10: 8 Vector__XXX
 SG_ TURBO_BOOST_PRESSURE_RATIO : 0|7@1+ (1,0) [0|100] ""  SMART_CORE
 SG_ TURBO_BOOST_PRESSURE_ABSOLUTE : 7|5@1+ (1,0) [0|30] "psi"  SMART_CORE
 SG_ T50_STATUS : 62|2@1+ (1,0) [0|3] ""  SMART_CORE

BO_ 960 VCU5_500: 8 Vector__XXX
 SG_ VIN_INDEX M : 56|2@1+ (1,0) [0|3] ""  SMART_CORE
 SG_ VIN_DATA_2 m2 : 0|24@1+ (1,0) [0|16777215] ""  SMART_CORE
 SG_ VIN_DATA_1 m1 : 0|56@1+ (1,0) [0|7.2057594038] ""  SMART_CORE
 SG_ VIN_DATA_0 m0 : 0|56@1+ (1,0) [0|7.2057594038] ""  SMART_CORE

BO_ 293 EMS2_10: 8 Vector__XXX
 SG_ ENG_SPD_RATE : 32|16@1+ (0.5,-16384) [-16384|16383] "rpm/s"  SMART_CORE
 SG_ ODO_DISTANCE_EMS : 16|16@1+ (1,0) [0|65535] "m"  SMART_CORE
 SG_ VEHICLE_SPEED_EMS : 0|16@1+ (0.015625,0) [0|300] "kmph"  SMART_CORE

BO_ 292 EMS1_10: 8 Vector__XXX
 SG_ BRK_PEDAL : 45|2@1+ (1,0) [0|3] ""  SMART_CORE
 SG_ INJ_QTY : 24|11@1+ (0.1,0) [0|204.6] "mg/cyl"  SMART_CORE
 SG_ STS_CRUISE_KEYPAD : 35|3@1+ (1,0) [0|7] ""  SMART_CORE
 SG_ CURRENT_GEAR_MT : 40|4@1+ (1,0) [0|15] ""  SMART_CORE
 SG_ STS_AC_COMPRESSOR : 48|2@1+ (1,0) [0|3] ""  SMART_CORE
 SG_ ENG_SPD : 8|16@1+ (1,0) [0|7999] "rpm"  SMART_CORE
 SG_ ACC_PED : 0|8@1+ (0.4,0) [0|100] "%"  SMART_CORE
 SG_ STS_WATER_IN_FUEL : 44|1@1+ (1,0) [0|1] ""  SMART_CORE
 SG_ INDC_GLOW_PLUG : 50|3@1+ (1,0) [0|7] ""  SMART_CORE
 SG_ ENG_TEMP : 56|8@1+ (1,-40) [-40|214] "DegC"  SMART_CORE
 SG_ INDC_CRUISE : 38|2@1+ (1,0) [0|3] ""  SMART_CORE
 SG_ STS_ENG : 53|3@1+ (1,0) [0|7] ""  SMART_CORE

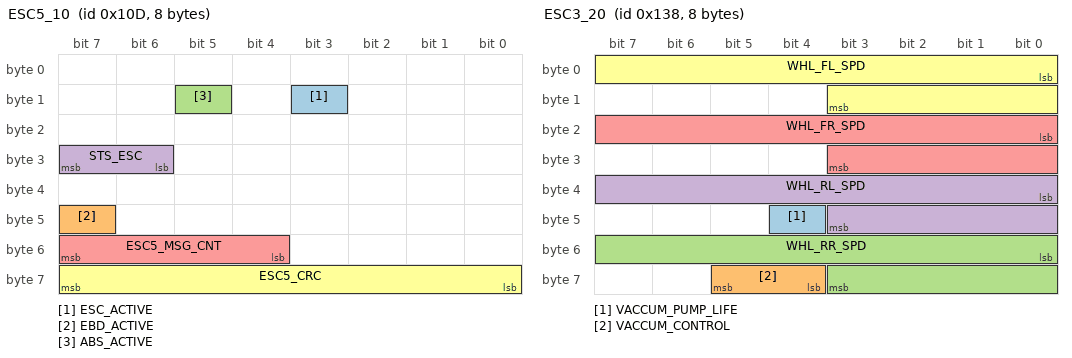
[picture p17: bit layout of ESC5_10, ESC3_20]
BO_ 269 ESC5_10: 8 Vector__XXX
 SG_ ESC_ACTIVE : 11|1@1+ (1,0) [0|1] ""  SMART_CORE
 SG_ EBD_ACTIVE : 47|1@1+ (1,0) [0|1] ""  SMART_CORE
 SG_ ABS_ACTIVE : 13|1@1+ (1,0) [0|1] ""  SMART_CORE
 SG_ STS_ESC : 30|2@1+ (1,0) [0|3] ""  SMART_CORE
 SG_ ESC5_MSG_CNT : 52|4@1+ (1,0) [0|15] ""  SMART_CORE
 SG_ ESC5_CRC : 56|8@1+ (1,0) [0|255] ""  SMART_CORE

BO_ 312 ESC3_20: 8 Vector__XXX
 SG_ VACCUM_PUMP_LIFE : 44|1@1+ (1,0) [0|1] ""  SMART_CORE
 SG_ VACCUM_CONTROL : 60|2@1+ (1,0) [0|3] ""  SMART_CORE
 SG_ WHL_RR_SPD : 48|12@1+ (1,0) [0|4095] "rpm" Vector__XXX
 SG_ WHL_RL_SPD : 32|12@1+ (1,0) [0|4095] "rpm" Vector__XXX
 SG_ WHL_FR_SPD : 16|12@1+ (1,0) [0|4095] "rpm" Vector__XXX
 SG_ WHL_FL_SPD : 0|12@1+ (1,0) [0|4095] "rpm" Vector__XXX

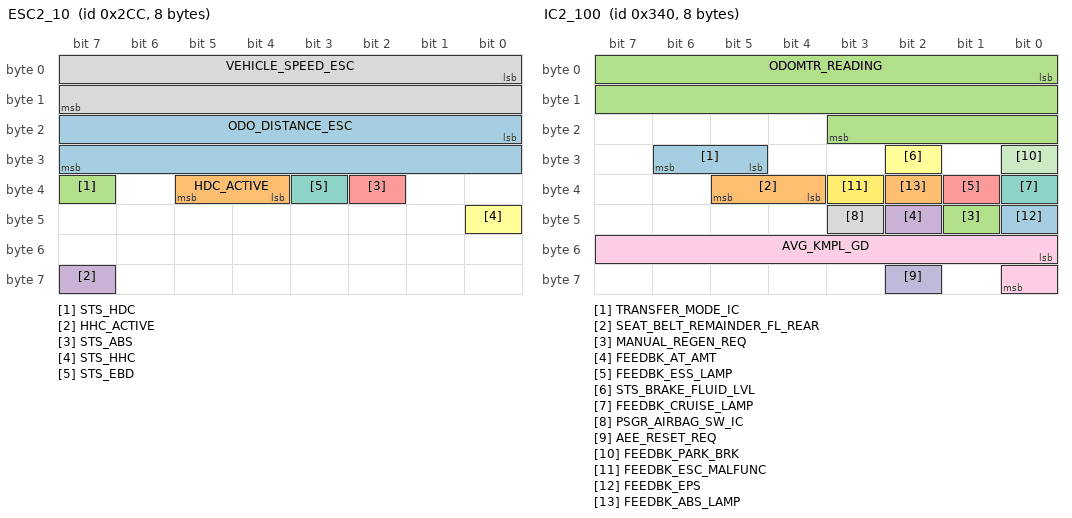
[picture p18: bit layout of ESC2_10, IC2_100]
BO_ 716 ESC2_10: 8 Vector__XXX
 SG_ ODO_DISTANCE_ESC : 16|16@1+ (1,0) [0|65535] "m"  SMART_CORE
 SG_ HDC_ACTIVE : 36|2@1+ (1,0) [0|3] ""  SMART_CORE
 SG_ STS_HDC : 39|1@1+ (1,0) [0|1] ""  SMART_CORE
 SG_ HHC_ACTIVE : 63|1@1+ (1,0) [0|1] ""  SMART_CORE
 SG_ STS_ABS : 34|1@1+ (1,0) [0|1] ""  SMART_CORE
 SG_ STS_HHC : 40|1@1+ (1,0) [0|1] ""  SMART_CORE
 SG_ STS_EBD : 35|1@1+ (1,0) [0|1] ""  SMART_CORE
 SG_ VEHICLE_SPEED_ESC : 0|16@1+ (0.015625,0) [0|300] "kmph"  SMART_CORE

BO_ 832 IC2_100: 8 SMART_CORE
 SG_ TRANSFER_MODE_IC : 29|2@1+ (1,0) [0|3] "" Vector__XXX
 SG_ SEAT_BELT_REMAINDER_FL_REAR : 36|2@1+ (1,0) [0|3] "" Vector__XXX
 SG_ MANUAL_REGEN_REQ : 41|1@1+ (1,0) [0|1] "" Vector__XXX
 SG_ FEEDBK_AT_AMT : 42|1@1+ (1,0) [0|1] "" Vector__XXX
 SG_ FEEDBK_ESS_LAMP : 33|1@1+ (1,0) [0|1] "" Vector__XXX
 SG_ STS_BRAKE_FLUID_LVL : 26|1@1+ (1,0) [0|1] "" Vector__XXX
 SG_ FEEDBK_CRUISE_LAMP : 32|1@1+ (1,0) [0|1] "" Vector__XXX
 SG_ PSGR_AIRBAG_SW_IC : 43|1@1+ (1,0) [0|1] "" Vector__XXX
 SG_ AVG_KMPL_GD : 48|9@1+ (0.1,0) [0|51] "km/l" Vector__XXX
 SG_ AEE_RESET_REQ : 58|1@1+ (1,0) [0|1] "" Vector__XXX
 SG_ FEEDBK_PARK_BRK : 24|1@1+ (1,0) [0|1] "" Vector__XXX
 SG_ FEEDBK_ESC_MALFUNC : 35|1@1+ (1,0) [0|1] "" Vector__XXX
 SG_ FEEDBK_EPS : 40|1@1+ (1,0) [0|1] "" Vector__XXX
 SG_ FEEDBK_ABS_LAMP : 34|1@1+ (1,0) [0|1] "" Vector__XXX
 SG_ ODOMTR_READING : 0|20@1+ (1,0) [0|999999] "km" Vector__XXX

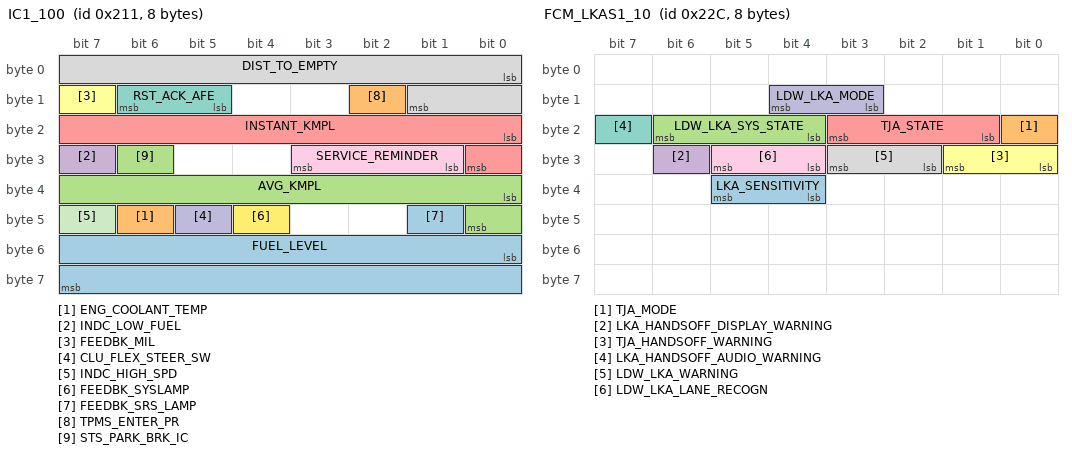
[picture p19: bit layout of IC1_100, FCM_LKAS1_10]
BO_ 529 IC1_100: 8 SMART_CORE
 SG_ FUEL_LEVEL : 48|16@1+ (1,0) [0|65533] "ml" Vector__XXX
 SG_ ENG_COOLANT_TEMP : 46|1@1+ (1,0) [0|1] "" Vector__XXX
 SG_ AVG_KMPL : 32|9@1+ (0.1,0) [0|51] "km/l" Vector__XXX
 SG_ INDC_LOW_FUEL : 31|1@1+ (1,0) [0|1] "" Vector__XXX
 SG_ INSTANT_KMPL : 16|9@1+ (0.1,0) [0|50] "" Vector__XXX
 SG_ FEEDBK_MIL : 15|1@1+ (1,0) [0|1] "" Vector__XXX
 SG_ RST_ACK_AFE : 13|2@1+ (1,0) [0|3] "" Vector__XXX
 SG_ DIST_TO_EMPTY : 0|10@1+ (1,0) [0|1000] "Km" Vector__XXX
 SG_ SERVICE_REMINDER : 25|3@1+ (1,0) [0|7] "" Vector__XXX
 SG_ CLU_FLEX_STEER_SW : 45|1@1+ (1,0) [0|1] "" Vector__XXX
 SG_ INDC_HIGH_SPD : 47|1@1+ (1,0) [0|1] "" Vector__XXX
 SG_ FEEDBK_SYSLAMP : 44|1@1+ (1,0) [0|1] "" Vector__XXX
 SG_ FEEDBK_SRS_LAMP : 41|1@1+ (1,0) [0|1] "" Vector__XXX
 SG_ TPMS_ENTER_PR : 10|1@1+ (1,0) [0|1] "" Vector__XXX
 SG_ STS_PARK_BRK_IC : 30|1@1+ (1,0) [0|1] "" Vector__XXX

BO_ 840 MBFM1_100: 8 Vector__XXX
 SG_ SECURITY_LED_MBFM : 28|2@1+ (1,0) [0|3] ""  SMART_CORE
 SG_ PARK_LAMP_ON_REMINDER : 12|1@1+ (1,0) [0|1] ""  SMART_CORE
 SG_ KEY_IN_REMINDER : 11|1@1+ (1,0) [0|1] ""  SMART_CORE
 SG_ STS_BRAKE_FLUID_LVL : 15|1@1+ (1,0) [0|1] ""  SMART_CORE
 SG_ INDC_PARK_BRK : 2|1@1+ (1,0) [0|1] ""  SMART_CORE
 SG_ INDC_REAR_FOG : 1|1@1+ (1,0) [0|1] ""  SMART_CORE
 SG_ STS_IGN : 8|3@1+ (1,0) [0|7] ""  SMART_CORE
 SG_ STS_RKE : 53|3@1+ (1,0) [0|7] ""  SMART_CORE
 SG_ STS_TRAILER : 44|1@1+ (1,0) [0|1] ""  SMART_CORE
 SG_ STS_RKE_BATT : 38|1@1+ (1,0) [0|1] ""  SMART_CORE
 SG_ ENG_OFF_TIME : 16|11@1+ (1,0) [0|1920] "min"  SMART_CORE
 SG_ STS_REAR_DEFOG_LOAD : 46|1@1+ (1,0) [0|1] ""  SMART_CORE
 SG_ STS_LOW_BEAM : 52|1@1+ (1,0) [0|1] ""  SMART_CORE
 SG_ STS_HIGH_BEAM : 45|1@1+ (1,0) [0|1] ""  SMART_CORE
 SG_ INDC_TURN_FLSHR : 6|2@1+ (1,0) [0|3] ""  SMART_CORE
 SG_ STS_SEAT_BLT_PSGR_MBFM : 50|2@1+ (1,0) [0|3] "" Vector__XXX
 SG_ STS_SEAT_BLT_DRV_MBFM : 48|2@1+ (1,0) [0|3] ""  SMART_CORE
 SG_ STS_DOOR : 32|6@1+ (1,0) [0|63] ""  SMART_CORE
 SG_ STS_PARKLAMP : 4|2@1+ (1,0) [0|3] ""  SMART_CORE
 SG_ INDC_FRNT_FOG : 0|1@1+ (1,0) [0|1] ""  SMART_CORE

BO_ 1848 SRS_DIAG_RES: 8 Vector__XXX
 SG_ DIAG_SRS_RES_DATA : 0|64@1+ (1,0) [0|1.8446744074] ""  SMART_CORE

BO_ 556 FCM_LKAS1_10: 8 Vector__XXX
 SG_ LKA_SENSITIVITY : 36|2@1+ (1,0) [0|3] ""  SMART_CORE
 SG_ TJA_MODE : 16|1@1+ (1,0) [0|1] ""  SMART_CORE
 SG_ LDW_LKA_SYS_STATE : 20|3@1+ (1,0) [0|7] ""  SMART_CORE
 SG_ LKA_HANDSOFF_DISPLAY_WARNING : 30|1@1+ (1,0) [0|1] ""  SMART_CORE
 SG_ TJA_STATE : 17|3@1+ (1,0) [0|7] ""  SMART_CORE
 SG_ TJA_HANDSOFF_WARNING : 24|2@1+ (1,0) [0|3] ""  SMART_CORE
 SG_ LKA_HANDSOFF_AUDIO_WARNING : 23|1@1+ (1,0) [0|1] ""  SMART_CORE
 SG_ LDW_LKA_WARNING : 26|2@1+ (1,0) [0|3] ""  SMART_CORE
 SG_ LDW_LKA_LANE_RECOGN : 28|2@1+ (1,0) [0|3] ""  SMART_CORE
 SG_ LDW_LKA_MODE : 11|2@1+ (1,0) [0|3] ""  SMART_CORE

BO_ 665 FCM_NSM: 8 Vector__XXX
 SG_ RESERVED_FCM : 0|64@1+ (1,0) [0|0] ""  SMART_CORE

BO_ 1840 SRS_DIAG_REQ: 8 SMART_CORE
 SG_ DIAG_SRS_REQ_DATA : 0|64@1+ (1,0) [0|1.8446744074E+019] "" Vector__XXX

BO_ 1970 PKE_DIAG_REQ: 8 SMART_CORE
 SG_ DIAG_PKE_REQ_DATA : 0|64@1+ (1,0) [0|1.8446744074E+019] "" Vector__XXX

BO_ 1978 PKE_DIAG_RES: 8 Vector__XXX
 SG_ DIAG_PKE_RES_DATA : 0|64@1+ (1,0) [0|1.8446744074E+019] ""  SMART_CORE

BO_ 1912 EPS_DIAG_RES: 8 Vector__XXX
 SG_ DIAG_ECPS_RES_DATA : 0|64@1+ (1,0) [0|1.8446744074E+019] ""  SMART_CORE

BO_ 1904 EPS_DIAG_REQ: 8 SMART_CORE
 SG_ DIAG_ECPS_REQ_DATA : 0|64@1+ (1,0) [0|1.8446744074E+019] "" Vector__XXX

BO_ 2021 MBFM_DIAG_REQ: 8 SMART_CORE
 SG_ DIAG_MBFM_REQ_DATA : 0|64@1+ (1,0) [0|1.8446744074E+019] "" Vector__XXX

BO_ 2026 IC_DIAG_RES: 8 SMART_CORE
 SG_ DIAG_IC_RES_DATA : 0|64@1+ (1,0) [0|1.8446744074E+019] "" Vector__XXX

BO_ 2018 IC_DIAG_REQ: 8 Vector__XXX
 SG_ DIAG_IC_REQ_DATA : 0|64@1+ (1,0) [0|1.8446744074E+019] ""  SMART_CORE

BO_ 776 EMS6_500: 8 Vector__XXX
 SG_ DISP_AMBT_TEMP_EMS : 8|8@1+ (1,-40) [-40|214] "deg C."  SMART_CORE
 SG_ STS_REMOTE_ENG : 3|2@1+ (1,0) [0|3] ""  SMART_CORE
 SG_ VALET_MODE_STATUS : 2|1@1+ (1,0) [0|1] ""  SMART_CORE
 SG_ ENG_ON_TIME : 16|16@1+ (1,0) [0|65534] "min"  SMART_CORE

BO_ 1928 VCU_DIAG_RES: 8 Vector__XXX
 SG_ VCU_DIAG_RES_DATA : 0|64@1+ (1,0) [0|1.8446744074E+019] ""  SMART_CORE

BO_ 1920 VCU_DIAG_REQ: 8 SMART_CORE
 SG_ DIAG_VCU_REQ_DATA : 0|64@1+ (1,0) [0|1.8446744074E+019] "NA" Vector__XXX

BO_ 778 VCU10_100: 8 Vector__XXX
 SG_ Reduce_Power_Mode_TT : 28|2@1+ (1,0) [0|3] ""  SMART_CORE
 SG_ REGEN_LEVELS : 61|3@1+ (1,0) [0|7] ""  SMART_CORE
 SG_ Sts_Regen_Cutoff_TT : 7|1@1+ (1,0) [0|3] ""  SMART_CORE
 SG_ LOW_AUX_BATT_TT : 58|2@1+ (1,0) [0|3] ""  SMART_CORE
 SG_ HIGH_TEMP_LIGHT_OP : 56|2@1+ (1,0) [0|3] ""  SMART_CORE
 SG_ STS_SERVICE_LIGHT_TT : 54|2@1+ (1,0) [0|3] ""  SMART_CORE
 SG_ STS_HV_BATT_TT : 52|2@1+ (1,0) [0|3] ""  SMART_CORE
 SG_ STS_EVWARNING_TT : 50|2@1+ (1,0) [0|3] ""  SMART_CORE
 SG_ STS_CHARGE_LIGHT_TT : 48|2@1+ (1,0) [0|3] ""  SMART_CORE
 SG_ ALERT_MSGS : 40|8@1+ (1,0) [0|255] ""  SMART_CORE
 SG_ PRESS_BRAKE : 4|1@1+ (1,0) [0|1] "NA"  SMART_CORE
 SG_ EV_READY_TT : 24|2@1+ (1,0) [0|3] ""  SMART_CORE
 SG_ DRIVE_EFFICIENCY : 8|8@1+ (1,-100) [-100|100] "%"  SMART_CORE
 SG_ TIME_TO_CHARGE_VCU : 32|8@1+ (5,0) [0|1275] "min"  SMART_CORE
 SG_ STATE_OF_CHARGE : 16|8@1+ (1,0) [0|100] "%"  SMART_CORE
 SG_ INDC_DRIVE_ENABLE : 5|2@1+ (1,0) [0|2] ""  SMART_CORE
 SG_ AEE_RESET_REQ_FB : 60|1@1+ (1,0) [0|1] ""  SMART_CORE
 SG_ GEAR_ACTUAL_VCU : 0|4@1+ (1,0) [0|15] ""  SMART_CORE

BO_ 1424 VCU16_500: 8 Vector__XXX
 SG_ AVAIL_PWR_COMPRESSOR : 16|8@1+ (50,0) [0|12750] "W"  SMART_CORE
 SG_ AVAIL_PWR_CABIN_HEATER : 24|8@1+ (50,0) [0|12750] "W"  SMART_CORE
 SG_ DTE : 6|10@1+ (1,0) [0|999] "km"  SMART_CORE
 SG_ VEHICLE_MODE : 1|3@1+ (1,0) [0|7] ""  SMART_CORE
 SG_ VESS_DISABLE : 0|1@1+ (1,0) [0|1] ""  SMART_CORE

BO_ 2015 GLOBAL_DIAG_REQ: 8 Vector__XXX
 SG_ DIAG_GLOBAL_REQ_DATA : 0|64@1+ (1,0) [0|1.8446744074E+019] ""  SMART_CORE

CM_ BO_ 1980 "OBCLDC Diagnostic Response";
CM_ SG_ 1980 DIAG_LDC_RES_DATA "Diagnostic Res from LDC to Tool";
CM_ SG_ 2008 DIAG_MCU_RES_DATA "MCU Diagnostic Response";
CM_ BO_ 579 "VCU EVCAN Wakeup Frame.It would be sent spontaneously after every 20ms for 60ms (3 times)";
CM_ SG_ 579 VCU_EVCAN_WAKEUPREASONRESERVED2 "VCU EV CAN Wakeup Reason";
CM_ SG_ 579 VCU_EVCAN_WAKEUPREASONRESERVED1 "VCU EV CAN Wakeup Reason";
CM_ SG_ 579 VCU_EVCAN_WAKEUPREASON "VCU EV CAN Wakeup Reason";
CM_ BO_ 936 "VCU EVCAN Sleep Frame";
CM_ SG_ 936 VCU_EVCAN_SLEEPRESERVED "VCU EVCAN Sleep Reserved";
CM_ BO_ 1933 "ETL Diagnotic Response";
CM_ SG_ 1933 DIAG_ETL_RES_DATA "Diagnostic Res from ETL  to Tool";
CM_ BO_ 1981 "OBCLDC Diagnostic Response";
CM_ SG_ 1981 DIAG_OBC_RES_DATA "Diagnostic Res from OBC to Tool";
CM_ BO_ 1976 "BMS Diagnostic Response";
CM_ SG_ 1976 DIAG_BMS_RES_DATA "Diagnostic Res from BMS to Tool";
CM_ BO_ 1972 "OBCLDC Diagnostic Request";
CM_ SG_ 1972 DIAG_LDC_REQ_DATA "Diagnostic Req from Tool to LDC";
CM_ BO_ 1925 "ETL Diagnostic Request";
CM_ SG_ 1925 DIAG_ETL_REQ_DATA "Diagnostic Req from Tool to ETL";
CM_ BO_ 1973 "OBCLDC Diagnostic Request";
CM_ SG_ 1973 DIAG_OBC_REQ_DATA "Diagnostic Req from Tool to OBC";
CM_ BO_ 2000 "MCU Diagnostic Request";
CM_ SG_ 2000 DIAG_MCU_REQ_DATA "Diagnostic Req from Tool to MCU";
CM_ BO_ 1968 "BMS Diagnostic Request";
CM_ SG_ 1968 DIAG_BMS_REQ_DATA "Diagnostic Req from Tool to BMS";
CM_ SG_ 336 BMS_TotalCycle_Time "BMS CYCLE TIME 
>Cycle time is the summation of charge cycle time and discharge cycle time
>Cycle time should be calculated at the instant when the cumulative charge cycle number and the discharge cycle get incremented by 1 
";
CM_ SG_ 336 BMS_DischargeCycle_Time "BMSDischargeCycle time
>Discharge cycle time set point is when IGN connected 
>Discharge cycle time finish point is till next charge plug connected or till BMS sleep

";
CM_ SG_ 336 BMS_ChargeCycle_Time "BMS Charge cycle time
>Charge cycle time set point is when charge plug is connected
>Charge cycle time finish point is end of charge concurrence/unplugging of the charger
";
CM_ SG_ 336 BMS_CycleNumber "BMS CYCLE NUMBER ";
CM_ SG_ 285 BMS_BattPack_PwrLimitErr_Common "Battery Pack Power limit Error";
CM_ SG_ 285 BMS_Bat_I_OvrExtCurr_Flt_Dischrg "Battery over extreme current fault during discharge ( I between 392 to 500 A )";
CM_ SG_ 285 BMS_Bat_I_OverCurr_Flt_Discharge "Battery over current fault during discharge ( I = 392 A )";
CM_ SG_ 285 BMS_BattOverVolt_Cutoff_Charge "Battery Over Voltage Cutoff at Charge
";
CM_ SG_ 285 BMS_ClntInlet_High_Temp_Charge "Coolant Inlet High Temp at charging

";
CM_ SG_ 285 BMS_ClntInlet_Low_Temp_Charge "Coolant Inlet Low Temp at Charging";
CM_ SG_ 285 BMS_ClntOutlet_Low_Temp_Charge "Coolant Outlet Low temp while Charging
";
CM_ SG_ 285 BMS_Clntoutlet_High_Temp_Charge "Coolant Outlet High Temp while Charging";
CM_ SG_ 285 BMS_BattOver_Temp_Cutoff_common "Battery Over Temp cutoff
";
CM_ SG_ 285 BMS_BattUnder_Temp_Cutoff_common "Battery Under temp cutoff";
CM_ SG_ 285 BMS_ClntSen_Thres_Fault_Charge "Coolant Sensor Threshold fault during charging";
CM_ SG_ 285 BMS_ReverseCurrDetect_Charge "Reverse current detected while charging
";
CM_ SG_ 285 BMS_PLP_Stop_Charge "Pack Level protection: Stop Charge";
CM_ SG_ 285 BMS_CellUnderVolt_Cutoff_Common "Cell under Voltage Cutoff";
CM_ SG_ 285 BMS_BattUnderVolt_Cutoff_Common "Battery Under Voltage Cutoff";
CM_ SG_ 285 BMS_ModuleOverTemp_Cutoff_Common "Module Over temp cutoff";
CM_ SG_ 285 BMS_MdleUnderTemp_Cutoff_Common "Module Under Temperature cutoff ";
CM_ SG_ 285 BMS_ShortCircuitCurr_Flt_Common "Short Circuit Current Fault";
CM_ SG_ 285 BMS_Sensor_Failure_Common "Sesor Failure";
CM_ SG_ 285 BMS_Ibatt_392_25sec_Common "Ibatt=392 for 25 sec";
CM_ SG_ 285 BMS_PilotLine_Detect_Common "Pilot Line Detection fault";
CM_ SG_ 285 BMS_Revive_Common "Revive fault
";
CM_ SG_ 285 BMS_HeaterSys_Flt_Common "Heater System Fault";
CM_ SG_ 285 BMS_Clnt_TempSens_Flt_Common "Coolant Temperature Sensor Fault";
CM_ SG_ 285 BMS_Heater_Flt_Common "Heater Fault";
CM_ SG_ 285 BMS_IsoFLt_Red_Discharge "Isolation Fault Red during Discharge";
CM_ SG_ 285 BMS_LowSOC_Cutoff_Discharge "Low SOC Cutoff during Dishcharging";
CM_ SG_ 285 BMS_Bat_I_ExtCurr_Flt_Dischrg "Battery extreme current fault during discharge ( Greater than 500 A )";
CM_ SG_ 285 BMS_MTM_ActvLimit_Common "Module Temperature Monitoring active limit";
CM_ SG_ 285 BMS_ClntSys_Flt_Common "Coolant system fault
";
CM_ SG_ 285 BMS_Pump_DryRun_Err_Common "Pump Dry run Error";
CM_ SG_ 285 BMS_CrashDtct_P_F_Open_Common "Crash detected: Pyro fuse Open";
CM_ SG_ 285 BMS_HVIL_Err_Dischrg "BMS HVIL ERROR_discharge";
CM_ SG_ 285 BMS_No_Cntctr_Close "No contactor close";
CM_ SG_ 285 BMS_CntctrOpen_Rqst_VCU_Dischrg "Request Vcu to open conatctors in discharge";
CM_ SG_ 285 BMS_CntctrOpen_Rqst_VCU_Chrg "Request Vcu to open conatctors in charge ";
CM_ SG_ 285 BMS_InitCntctrOpen_Dischrg "BMS initiate conatctor open_discharge";
CM_ SG_ 285 BMS_InitCntctrOpen_Charge "BMS initiate conatctor open_charge";
CM_ SG_ 285 BMS_FSBIM_bAcvDrtdMode "Derate due to FusA- battery current monitoring function";
CM_ SG_ 285 BMS_FSPLP_bAcvDrtdMode "Derate due to pack level protection function";
CM_ SG_ 285 BMS_ILC_AcvDrtdCdn "Derate due to Current limit coordination";
CM_ SG_ 285 BMS_IDMStsIsInErr_Yellow "Derate due to DC isolation monitoring ";
CM_ SG_ 285 BMS_FSPLP_bAcvPackOverUDrtd "Derate due to pack level protection - Over current ";
CM_ SG_ 285 BMS_BIM_bAcvHighRateDchaDrdt2 "Dearte due to high rate discharge";
CM_ SG_ 285 BMS_FSPLP_bAcvPackUnderUDrtd "Derate due to pack level protection function - Under current ";
CM_ SG_ 285 BMS_BTFD_bAcvReqDrtdMode "Derate due to battery thermal fault handling";
CM_ SG_ 285 BMS_CUM_bAcvOwDrtd "Derate due to Cell volatge monitoring";
CM_ SG_ 285 BMS_CellOverVolt_Cutoff_Charge "Cell Over Volatge cutoff while Charging";
CM_ SG_ 285 BMS_Reason_HV_Disconnected "Reason for HV DisconnectReason for HV Disconnect";
CM_ SG_ 285 BMS_Reason_HV_Disconnect_Request "Reason for HV Disconnect RequestReason for HV Disconnect Request";
CM_ SG_ 285 BMS_Reason_Derating "Reason for derated modeReason for derated mode";
CM_ SG_ 920 STS_HIGHBEAM_BOOSTER "Highbeam booster status";
CM_ SG_ 920 HEADLAMP_AUTO_LEVEL "Head Lamp Auto Level  ";
CM_ SG_ 921 STS_HIGHBEAM_BOOSTER_1 "Highbeam booster status";
CM_ SG_ 771 DISP_AMBT_TEMP_FATC "Outside Temperature";
CM_ SG_ 1711 FOD_ALERT "User alert in case of FOD ( Foreign Object Detection)";
CM_ SG_ 1711 TIME_TO_CHARGE "Time to Charge";
CM_ SG_ 768 AUTO_RECIRC "It will indicate the about the status of auto recirculation mode.";
CM_ SG_ 768 AUTO_DEFROST "Auto defrost signal will indicate whether it is enable or disble. When there will be moisture in the window then hot air will be released according to the ambient temperature to defrost it.";
CM_ SG_ 1588 GP_CLOSE_RES_AC "Glasspanel smart close response for AC";
CM_ SG_ 1588 GP_CLOSE_RES_RAIN "Glasspanel smart close response for Rain";
CM_ BO_ 1586 "Seat Control Module";
CM_ SG_ 1586 SEAT_HEAT_VENT_LEVEL_SCM "seat heat/ vent level 
";
CM_ SG_ 1586 STS_HEATER "Heater ON / OFF Status";
CM_ SG_ 1586 SEAT_POSITION_FEEDBACK "Feedback signal ";
CM_ SG_ 1586 SCM_MEMORY_STS "Memory status based on SCM Memory Mode signal (Status will be update to fail or succeed)";
CM_ SG_ 1586 SCM_MEMORY_MODE "SCM Memory and Operation Mode";
CM_ SG_ 1586 HEATER_TEMP "Seat Heater Temperature";
CM_ SG_ 1586 POWER_SEAT_MEMORY_STORE "Power Seat Memory Store

3 seat positions  can be stored in 3 memories M (1, 2 and 3)";
CM_ SG_ 1586 POWER_SEAT_MEMORY_RECALL "Power Seat Memory Restore

Seat position  can be Restored based on stored position in memory";
CM_ SG_ 828 RLS_FW_BRIGHTNESS "RLS Forward Brightness";
CM_ SG_ 828 RLS_AMB_BRIGHTNESS "RLS Ambient Brightness";
CM_ SG_ 806 FPAS_ACTIVE_STS "FPAS Function Active Status";
CM_ SG_ 806 RPAS_ERROR "Bit 0 : Rear left corner
Bit 1 : Rear left center
Bit 2 : Rear right center
Bit 3 : Rear right corner
Bit 4 : ECU fault (RPAS not functional)

0 - No error
1 - Error";
CM_ SG_ 806 RPAS_DISP_DIST "RPAS Display distance";
CM_ SG_ 806 RPAS_ACTIVE_STS "RPAS Function Active Status";
CM_ SG_ 806 BAR_ZONE_RRC "RPAS Bar Zone value for RRC";
CM_ SG_ 806 BAR_ZONE_RR "RPAS Bar Zone value for RR";
CM_ SG_ 806 BAR_ZONE_RLC "RPAS Bar Zone value for RLC";
CM_ SG_ 806 BAR_ZONE_RL "RPAS Bar Zone value for RL";
CM_ SG_ 806 FPAS_DISP_DIST "FPAS Display distance";
CM_ SG_ 806 BAR_ZONE_FRC "FPAS Bar Zone value for FRC";
CM_ SG_ 806 BAR_ZONE_FLC "FPAS Bar Zone value for FLC";
CM_ SG_ 806 FPAS_ERROR "Bit 0 : Frent left corner
Bit 1 : Frent left center
Bit 2 : Frent right center
Bit 3 : Frent right corner
Bit 4 : ECU fault (FPAS not functional)

0 - No error
1 - Error";
CM_ SG_ 806 BAR_ZONE_FR "FPAS Bar Zone value for FR";
CM_ SG_ 806 BAR_ZONE_FL "FPAS Bar Zone value for FL";
CM_ SG_ 2029 DIAG_MBFM_RES_DATA "Keyword 2000 Diagnostic Message Response Data";
CM_ SG_ 1056 HEATER_INPUT_DC_VOLT "Input DC voltage";
CM_ BO_ 1001 "BMS Normal Signals 01";
CM_ SG_ 1001 BMS_ChargeVoltageLimit "Charge Voltage Limit of Battery Pack";
CM_ SG_ 1001 BMS_ChargeCurrentLimit "Charge current request from BMS  (AC / DC Charging Limitation of PACK)";
CM_ SG_ 1001 BMS_DischargeCurrentlimit "HV Battery allowable discharge current limit ";
CM_ SG_ 1168 EPT_RADIATORFAN_SPEED_REQ "EPT COOLING RADIATOR FAN SPEED REQUEST";
CM_ SG_ 1168 STS_EPT_RADIATORFAN "EPT COOLING RADIATOR FAN ON/ OFF REQUEST";
CM_ SG_ 1168 BATT_COOLING_REQ "BATTERY COOLING REQUEST";
CM_ SG_ 1168 BATT_COMPRES_SPD_REQ "BATTERY COMPRESSOR SPEED REQUEST TO ETC";
CM_ SG_ 159 VCU_WAKEUP_REASON "Reason for wake-up.
Need to defined
";
CM_ SG_ 943 VCU_ACTIVE_RESERVED "VCU EVCAN Active Reserved";
CM_ SG_ 743 REQUEST_RESPONSE_REVIVE "Response for Revive Request";
CM_ SG_ 743 MOTOR_PWR "Motor Power";
CM_ SG_ 743 RECUP_CTRL_STATE "Recuperation Inhibition to be updated even if Recup is disabled because of internal or NM faults. Indicates recuperation cannot happen in the vehicle as long as this is 1.";
CM_ SG_ 1416 SUNROOF_WINDOW_OPEN_IS "Sunroof & Window open during door unlock feature turn ON or OFF";
CM_ SG_ 1416 POWER_SEAT_RECALL_IS "Power Seat Recall ";
CM_ SG_ 250 IMMOVAL6 "MCM to PKE Handshaking Message";
CM_ SG_ 1408 AVH_FUNCTION_STS "AVH Function available status";
CM_ SG_ 1408 AVH_ACTIVE_STS "AVH function active status";
CM_ SG_ 1408 EPB_ALERT "Electronic Park Brake Alerts";
CM_ SG_ 1408 PARK_BRK_ACTIVE_STS "Electronic Park Brake Active Status";
CM_ SG_ 1408 RR_PARK_BRK_ACTIVE_STS "Rear Right Electronic Park Brake Active Status";
CM_ SG_ 1408 RL_PARK_BRK_ACTIVE_STS "Rear Left Electronic Park Brake Active Status";
CM_ SG_ 977 CABIN_HVAC_REQ "CABIN COOLING/ HEATING REQUEST";
CM_ SG_ 977 MCMTRG_R "Trigger from MCM to PKE,to wakeup pke to initiate authentication";
CM_ SG_ 532 TPMS_SYSTEM_FAULT "TPMS Malfunction Indication - Sensor Low Battery/ Transmitter Fault

Bit description
0      Front Left tyre
1      Front Right tyre
2      Rear Right tyre
3      Rear Left tyre
4      TPMS Receiver Fault

0 : Normal
1 : Faulty";
CM_ SG_ 532 TPMS_SIGNAL_MISSING "Bit Position Description :-
Bit 0 : FL tyre
Bit 1 : FR tyre
Bit 2 : RR tyre
Bit 3 : RL tyre

Value Description :-
0 : Normal
1 : Signal missing";
CM_ SG_ 532 TPMS_LEAKAGE_ALERT "Bit Position Description :-
Bit 0 : FL tyre
Bit 1 : FR tyre
Bit 2 : RR tyre
Bit 3 : RL tyre
Bit 4 : Spare tyre

Value Description :-
0 : Normal
1 : Leakage";
CM_ BO_ 843 "ESCL MESSAGE";
CM_ SG_ 843 ESCL1_CRC "CRC-Checksum over all signals for E2E-Protection";
CM_ SG_ 843 ESCL1_MSG_CNT "Message counter for E2E protection";
CM_ SG_ 843 ESCL_STEER_WHL_JAM_WRN "ESCL_Prompt_Rotate_Steer_Wheel - Prompt Drive to Rotate Steering Wheel
";
CM_ SG_ 843 ESCL_WRN_SFTY "Warning of Safety Failure";
CM_ SG_ 843 ESCL_WRN_FUNC "ESCL_Warn_function - Warning of Functional Failure";
CM_ BO_ 869 "MCM to PKE Authentication message";
CM_ SG_ 869 PKE_CHALLENGE_STS "PKE Challenge Recieve status";
CM_ SG_ 266 IMMOVAL5 "MCM to PKE Handshaking Message";
CM_ SG_ 851 LAST_KEYFOB_NUM "Last Used Key Fob Number








";
CM_ SG_ 851 KEYFOB_INSIDE_STATUS "PKE KeyFobIn state [Inside the vehicle or not]




";
CM_ SG_ 1088 REMOTE_ENGINE_START_WARNING "Transition from RemoteEngine 
start to Normal(Speed Restriction removed) ";
CM_ SG_ 1088 STS_CAPASENSOR "Because of INTERNAL FAILURE of CAPA Sensor or continuous detection for more than 60 sec.";
CM_ SG_ 1088 CAR_START_WARNING "Just after IGN OFF to ON,
whether break pressed or not";
CM_ SG_ 1088 KEY_FOB_INSD_WRN "ID inside Warning Signal


";
CM_ SG_ 1088 PKE_SHIFT_TO_PARK "Shift 'P' to Turn OFF Warning Signal";
CM_ SG_ 1088 PKE_PN_OFF_WARNING "Shift P/N to Engine Start warning Signal
";
CM_ SG_ 1088 EMRGNCY_CRANK_WRN "Emergency Crank Warning Signal";
CM_ SG_ 1088 TERMINAL_NOT_OFF_WRN_CMD "Terminal Not OFF Warning Signal


";
CM_ SG_ 1088 DOOR_LOCK_WRN "Door open Warning / door lock Warning Signal


";
CM_ SG_ 1088 FOB_AUTH_FAIL_WRN "Transponder Authentication Status
Authentication with Keyfob Fail Signal


Transponder Authentication Status";
CM_ SG_ 1088 SSB_FAIL_WRN "PASEM Fail Warn CmdPASEM Fail Warn Cmd

Status signal for SSB Switch Failure";
CM_ SG_ 1088 KEY_NOT_VEH_WRN "Key not in vehicle Warning RequestCommand";
CM_ SG_ 1088 FOB_BATT_DISCHG_WRN "FOBBattery Discharge Warning Request Command

FOB Low Battery Warning Signal


FOBBattery Discharge Warning Request Command";
CM_ SG_ 834 PKE_ICU2_MSG_CNT "Message counter signal.";
CM_ SG_ 834 PKE_ICU2_CRC "Checksum signal";
CM_ SG_ 150 PKE_WAKEUP_REASON "Reason for PKE wake-up";
CM_ SG_ 587 ACC_VEH_SET_SPD "set vehicle speed";
CM_ SG_ 587 ACC_MODE "Mode Indication for ACC function";
CM_ SG_ 928 FPAS_SPAS_ACTIVE_STS "FPAS Function Active Status";
CM_ SG_ 928 FR_SEGMENT "Front Right Corner Sensor Display Segment .";
CM_ SG_ 928 RL_SEG_WARN "Rear Left Corner Sensor Warning status.";
CM_ SG_ 928 RPAS_ACTIVE_STS1 "RPAS Function Active Status";
CM_ SG_ 928 RL_SEGMENT "Rear Left Corner Sensor Display Segment .";
CM_ SG_ 928 FR_SEG_WARN "Front Right Corner Sensor Warning status.";
CM_ SG_ 928 FMR_SEG_WARN "Front Middle Right Sensor Warning status.";
CM_ SG_ 928 FML_SEG_WARN "Front Middle Left Sensor Warning status.";
CM_ SG_ 928 FL_SEG_WARN "Front Left Corner Sensor Warning status.";
CM_ SG_ 928 FMR_SEGMENT "Front Middle Right Sensor Display Segment.";
CM_ SG_ 928 FML_SEGMENT "Front Middle Left Sensor Display Segment .";
CM_ SG_ 928 FL_SEGMENT "Front Left Corner Sensor Display Segment.";
CM_ SG_ 928 RR_SEG_WARN "Rear Right Corner Sensor Warning status.";
CM_ SG_ 928 RMR_SEG_WARN "Rear Middle Right Sensor Warning status.";
CM_ SG_ 928 RML_SEG_WARN "Rear Middle Left Sensor Warning status.";
CM_ SG_ 928 REAR_MIN_DIST "Minimum obstacle distance detected by RPAS sensors .";
CM_ SG_ 928 RR_SEGMENT "Rear Right Corner Sensor Display Segment .";
CM_ SG_ 928 RMR_SEGMENT "Rear Middle Right Sensor Display Segment .";
CM_ SG_ 928 RML_SEGMENT "Rear Middle Left Sensor Display Segment .";
CM_ SG_ 928 FRONT_MIN_DIST "Minimum obstacle distance detected by FPAS sensors .";
CM_ SG_ 588 ACC_DRIVE_MODE "indicate Driving Beheavior   -  aggressive (fast), Normal / Slow driving pattern";
CM_ SG_ 588 ACC_TGT_VALIDITY "INDICATION TO DETECT VALID OBJECT ";
CM_ SG_ 588 ACC_SYS_STATE "Internal state indication for ACC function.";
CM_ SG_ 588 AEB_ZONE_STS_FRM "AEB warning zones status (prefil,partial braking ,full braking and stop request)";
CM_ SG_ 826 DROWSINESS_INDEX "Driver drowsiness index";
CM_ SG_ 826 ADV_MODE_ALERT "Adventure Drive mode alert.
It is required when there is a need to change in the mode like 2WD or 4WH or 4WL according to drive mode like grass, snow etc.
";
CM_ SG_ 826 STS_TVB "Torque Vectoring By braking";
CM_ SG_ 826 STS_DDD "Driver drowsiness";
CM_ SG_ 310 SHIFTING "Indicates when the transmision is shifting between gears.
Controllable engine loads (example AC Cutch) should not change state when this bit is set";
CM_ SG_ 310 GEAR_TARGET "Target gear";
CM_ SG_ 310 GEAR_ACTUAL "Actual Gear State of the Transmission
If Shifting flag is set then transition to desired gear is occuring
Actual Gear is updated at the end of the shift
Used cruise control shutoff in appropriate gear";
CM_ SG_ 643 GW_CH_STS "bit0: channel 1
bit1: channel 2
bit2:channel 3
bit3: channel 4
bit4:channel 5
bit5:channel 6

0: OK
1: Not OK

the failure of particular channel is indicated.";
CM_ SG_ 322 ENG_SPD1 "Engine Speed Signal";
CM_ SG_ 322 EMS36_MSG_CNT "EMS36 message counter";
CM_ SG_ 322 EMS36_CRC "EMS36 message checksum ";
CM_ SG_ 543 FR_SEAT_HEAT_VENT_LEVEL_MBFM "Seat heat/vent level control from MBFM to SCM";
CM_ SG_ 543 FL_SEAT_HEAT_VENT_LEVEL_MBFM "Seat heat/vent level control from MBFM to SCM";
CM_ SG_ 543 STS_LAMP_FAILURE_2 "BIT 0:- FL Turn Lamp
BIT 1:- FR Turn Lamp
BIT 2:- RL Turn Lamp
BIT 3:- RR Turn Lamp
BIT 4:- Front Fog Lamp
BIT 5:- Rear Fog Lamp
BIT 6:- Left DRL Lamp
BIT 7:- Right DRL Lamp
 
0x0:- OK/Default
0x1:-NOT OK
";
CM_ SG_ 543 STS_LAMP_FAILURE_1 "BIT 0:-FR Corner Lamp
BIT 1:-FL Corner Lamp
BIT 2:- Right Low Beam
BIT 3:- Left Low Beam
BIT 4:- Right High Beam
BIT 5:- Left High Beam
BIT 6:- Rear Park Lamp
BIT 7:- Brake Lamp

 
0x0:- OK/Default
0x1:-NOT OK";
CM_ SG_ 543 PSGR_REAR_SEAT_BELT "BIT 0:- Rear Left Passenger
BIT 1:- Rear Middle Passenger
BIT 2:- Rear Right Passenger
BIT 3:- Rear 3rd RowLeft Passenger
BIT 4:- Rear 3rd Row Middle Passenger
BIT 5:- Rear 3rd Row Right Passenger

0x0:-Not Buckled/DV
0x1:-Buckled";
CM_ SG_ 543 STS_SRF_POS "Status of Sunroof Position.";
CM_ SG_ 543 CABIN_HVAC_REQ_MBFM "Blower ON request";
CM_ SG_ 543 STS_PWM_POS "Status of Power Window Module Position.";
CM_ SG_ 543 GP_CLOSE_REQ_RAIN "Glasspanel Smart Close request due to Rain";
CM_ SG_ 543 GP_CLOSE_REQ_AC "Glasspanel Smart Close request due to AC";
CM_ SG_ 543 HEAD_LAMP_SW_STS "Head lamp Combi switch status signal.";
CM_ SG_ 1089 USM_RESET "Manual Reset ";
CM_ SG_ 1089 STS_TSR_SWT "Traffic Sign Recognization (TSR) Switch Status Indication";
CM_ SG_ 1089 STS_TJA_SWT "Traffic Jam Assist (TJA) Switch Status Indication";
CM_ SG_ 1089 ACC_DRIVE_MODE_IC "ACC Drive Mode Indication ";
CM_ SG_ 1089 STS_AEB_SWT "AEB Switch Status Indication";
CM_ SG_ 1089 AEB_FCW_WARNING_TIMINGS "Autonomous Emergency Braking (AEB) Warning ";
CM_ SG_ 1089 LDW_LKA_MODE_SWT "LDW/ LKAS Function Enable Indication ";
CM_ SG_ 1089 VEHICLE_SPEED_IC_DISPLAYED "Vehicle Speed Displayed by Cluster";
CM_ SG_ 545 STS_EPS_STEERING_MODE "EPS steering Mode status";
CM_ SG_ 545 EPS_STEERING_MODE_ALERT "EPS steering Mode alert";
CM_ SG_ 545 EPS_STEERING_MODE "EPS steering Mode";
CM_ SG_ 545 EPS_DRV_ADV_MODE "Flex & Drive modes have same signal mapping (Feature code control)
Flex steer Tx Map:
0x0 - Mode 1 / Normal 
0x1 - Mode 2 / Sports
0x2 - Mode 3 / Comfort";
CM_ SG_ 545 EPS_FLEX_DISP "Flex Map Display";
CM_ SG_ 1407 TSR_SYS_STATE "TSR(Traffic sign Recognition) system operating state";
CM_ SG_ 589 AEB_ZONE_STS_FCM "AEB warning zones status (prefil,partial braking ,full braking and stop request)";
CM_ SG_ 592 SBW1_MSG_COUNT "Message Counter for TGS message";
CM_ SG_ 592 SBW1_CRC "CRC for TGS message";
CM_ SG_ 592 SBW_FAULT "This Signal will indicate to the AMTCU, as to when should the AMT MIL has to be turned ON";
CM_ SG_ 592 SBW_LEVER "Transmission Gear Select lever position.
This would be used by the instrument cluster when the TCU mode is not DSI Mode or Range Mode";
CM_ SG_ 971 STS_AUTO_HEAT "Auto Heat Enable/ Disable from Smartcore";
CM_ SG_ 971 STS_SEAT_POSITION_DISPLAY "Seat Alert Enable/Disable from Smart Core";
CM_ SG_ 971 STS_AUTO_VENT "Auto Vent Enable/ Disable from Smartcore";
CM_ SG_ 971 STS_AUTO_DIP "When reversed gear is engaged , infotainment will request MBFM to Tilt ORVM downward";
CM_ SG_ 971 STS_EASY_ENTRY "EASY ENTRY  ENABLE FROM IS";
CM_ SG_ 971 STS_EASY_EXIT "EASY EXIT ENABLE FROM IS";
CM_ SG_ 971 STS_SEAT_PROFILE_IS "Keyfob1 linkage with seat position (1,2,3) ";
CM_ SG_ 971 STS_BS_ORVM_ADJUST "ORVM adjust for Blind spot Enable disable from IS";
CM_ SG_ 971 STS_REV_GEAR_SIREN "siren for reverse gear enable disable setting from IS";
CM_ SG_ 971 STS_AUTO_TURN_LAMP "Auto turn lamp enable disable from IS";
CM_ SG_ 971 STS_SELECT_UNLOCK "SECLECTIVE UNLOCK ENABLE FROM IS";
CM_ SG_ 971 FR_SEAT_HEAT_VENT_LEVEL_IS "Seat heat/vent level control through HMI";
CM_ SG_ 971 FL_SEAT_HEAT_VENT_LEVEL_IS "Seat heat/vent level control through HMI";
CM_ SG_ 299 BMS_IsolationResis "Isolation resistance value";
CM_ SG_ 299 BMS_NC_Count "Battery Notmal Charge Count
";
CM_ SG_ 299 BMS_FC_Count "Battery  Fast Charge Count
";
CM_ SG_ 1004 BMS_CellVoltage44 "BMS Cell Voltage 44";
CM_ SG_ 1004 BMS_CellVoltage43 "BMS Cell Voltage 43";
CM_ SG_ 1004 BMS_CellVoltage42 "BMS Cell Voltage 42";
CM_ SG_ 1004 BMS_CellVoltage41 "BMS Cell Voltage 41";
CM_ SG_ 1004 BMS_CellVoltage40 "BMS Cell Voltage 40";
CM_ SG_ 1004 BMS_CellVoltage4 "BMS Cell Voltage 4";
CM_ SG_ 1004 BMS_CellVoltage39 "BMS Cell Voltage 39";
CM_ SG_ 1004 BMS_CellVoltage38 "BMS Cell Voltage 38";
CM_ SG_ 1004 BMS_CellVoltage37 "BMS Cell Voltage 37";
CM_ SG_ 1004 BMS_CellVoltage36 "BMS Cell Voltage 36";
CM_ SG_ 1004 BMS_CellVoltage35 "BMS Cell Voltage 35";
CM_ SG_ 1004 BMS_CellVoltage34 "BMS Cell Voltage 34";
CM_ SG_ 1004 BMS_CellVoltage33 "BMS Cell Voltage 33";
CM_ SG_ 1004 BMS_CellVoltage32 "BMS Cell Voltage 32";
CM_ SG_ 1004 BMS_CellVoltage31 "BMS Cell Voltage 31";
CM_ SG_ 1004 BMS_CellVoltage30 "BMS Cell Voltage 30";
CM_ SG_ 1004 BMS_CellVoltage3 "BMS Cell Voltage 3";
CM_ SG_ 1004 BMS_CellVoltage29 "BMS Cell Voltage 29";
CM_ SG_ 1004 BMS_CellVoltage28 "BMS Cell Voltage 28";
CM_ SG_ 1004 BMS_CellVoltage27 "BMS Cell Voltage 27";
CM_ SG_ 1004 BMS_CellVoltage26 "BMS Cell Voltage 26";
CM_ SG_ 1004 BMS_CellVoltage25 "BMS Cell Voltage 25";
CM_ SG_ 1004 BMS_CellVoltage24 "BMS Cell Voltage 24";
CM_ SG_ 1004 BMS_CellVoltage23 "BMS Cell Voltage 23";
CM_ SG_ 1004 BMS_CellVoltage22 "BMS Cell Voltage 22";
CM_ SG_ 1004 BMS_CellVoltage21 "BMS Cell Voltage 21";
CM_ SG_ 1004 BMS_CellVoltage20 "BMS Cell Voltage 20";
CM_ SG_ 1004 BMS_CellVoltage96 "BMS Cell Voltage 96";
CM_ SG_ 1004 BMS_CellVoltage95 "BMS Cell Voltage 95";
CM_ SG_ 1004 BMS_CellVoltage94 "BMS Cell Voltage 94";
CM_ SG_ 1004 BMS_CellVoltage93 "BMS Cell Voltage 93";
CM_ SG_ 1004 BMS_CellVoltage92 "BMS Cell Voltage 92";
CM_ SG_ 1004 BMS_CellVoltage91 "BMS Cell Voltage 91";
CM_ SG_ 1004 BMS_CellVoltage90 "BMS Cell Voltage 90";
CM_ SG_ 1004 BMS_CellVoltage9 "BMS Cell Voltage 9";
CM_ SG_ 1004 BMS_CellVoltage89 "BMS Cell Voltage 89";
CM_ SG_ 1004 BMS_CellVoltage88 "BMS Cell Voltage 88";
CM_ SG_ 1004 BMS_CellVoltage87 "BMS Cell Voltage 87";
CM_ SG_ 1004 BMS_CellVoltage86 "BMS Cell Voltage 86";
CM_ SG_ 1004 BMS_CellVoltage85 "BMS Cell Voltage 85";
CM_ SG_ 1004 BMS_CellVoltage84 "BMS Cell Voltage 84";
CM_ SG_ 1004 BMS_CellVoltage83 "BMS Cell Voltage 83";
CM_ SG_ 1004 BMS_CellVoltage82 "BMS Cell Voltage 82";
CM_ SG_ 1004 BMS_CellVoltage81 "BMS Cell Voltage 81";
CM_ SG_ 1004 BMS_CellVoltage80 "BMS Cell Voltage 80";
CM_ SG_ 1004 BMS_CellVoltage8 "BMS Cell Voltage 8";
CM_ SG_ 1004 BMS_CellVoltage79 "BMS Cell Voltage 79";
CM_ SG_ 1004 BMS_CellVoltage78 "BMS Cell Voltage 78";
CM_ SG_ 1004 BMS_CellVoltage77 "BMS Cell Voltage 77";
CM_ SG_ 1004 BMS_CellVoltage76 "BMS Cell Voltage 76";
CM_ SG_ 1004 BMS_CellVoltage75 "BMS Cell Voltage 75";
CM_ SG_ 1004 BMS_CellVoltage74 "BMS Cell Voltage 74";
CM_ SG_ 1004 BMS_CellVoltage73 "BMS Cell Voltage 73";
CM_ SG_ 1004 BMS_CellVoltage72 "BMS Cell Voltage 72";
CM_ SG_ 1004 BMS_CellVoltage71 "BMS Cell Voltage 71";
CM_ SG_ 1004 BMS_CellVoltage70 "BMS Cell Voltage 70";
CM_ SG_ 1004 BMS_CellVoltage7 "BMS Cell Voltage 7";
CM_ SG_ 1004 BMS_CellVoltage69 "BMS Cell Voltage 69";
CM_ SG_ 1004 BMS_CellVoltage68 "BMS Cell Voltage 68";
CM_ SG_ 1004 BMS_CellVoltage67 "BMS Cell Voltage 67";
CM_ SG_ 1004 BMS_CellVoltage66 "BMS Cell Voltage 66";
CM_ SG_ 1004 BMS_CellVoltage65 "BMS Cell Voltage 65";
CM_ SG_ 1004 BMS_CellVoltage64 "BMS Cell Voltage 64";
CM_ SG_ 1004 BMS_CellVoltage63 "BMS Cell Voltage 63";
CM_ SG_ 1004 BMS_CellVoltage62 "BMS Cell Voltage 62";
CM_ SG_ 1004 BMS_CellVoltage61 "BMS Cell Voltage 61";
CM_ SG_ 1004 BMS_CellVoltage60 "BMS Cell Voltage 60";
CM_ SG_ 1004 BMS_CellVoltage6 "BMS Cell Voltage 6";
CM_ SG_ 1004 BMS_CellVoltage59 "BMS Cell Voltage 59";
CM_ SG_ 1004 BMS_CellVoltage58 "BMS Cell Voltage 58";
CM_ SG_ 1004 BMS_CellVoltage57 "BMS Cell Voltage 57";
CM_ SG_ 1004 BMS_CellVoltage56 "BMS Cell Voltage 56";
CM_ SG_ 1004 BMS_CellVoltage55 "BMS Cell Voltage 55";
CM_ SG_ 1004 BMS_CellVoltage54 "BMS Cell Voltage 54";
CM_ SG_ 1004 BMS_CellVoltage53 "BMS Cell Voltage 53";
CM_ SG_ 1004 BMS_CellVoltage52 "BMS Cell Voltage 52";
CM_ SG_ 1004 BMS_CellVoltage51 "BMS Cell Voltage 51";
CM_ SG_ 1004 BMS_CellVoltage50 "BMS Cell Voltage 50";
CM_ SG_ 1004 BMS_CellVoltage5 "BMS Cell Voltage 5";
CM_ SG_ 1004 BMS_CellVoltage49 "BMS Cell Voltage 49";
CM_ SG_ 1004 BMS_CellVoltage48 "BMS Cell Voltage 48";
CM_ SG_ 1004 BMS_CellVoltage47 "BMS Cell Voltage 47";
CM_ SG_ 1004 BMS_CellVoltage46 "BMS Cell Voltage 46";
CM_ SG_ 1004 BMS_CellVoltage45 "BMS Cell Voltage 45";
CM_ SG_ 1004 BMS_CellVoltage2 "BMS Cell Voltage 2";
CM_ SG_ 1004 BMS_CellVoltage19 "BMS Cell Voltage 19";
CM_ SG_ 1004 BMS_CellVoltage18 "BMS Cell Voltage 18";
CM_ SG_ 1004 BMS_CellVoltage17 "BMS Cell Voltage 17";
CM_ SG_ 1004 BMS_CellVoltage16 "BMS Cell Voltage 16";
CM_ SG_ 1004 BMS_CellVoltage15 "BMS Cell Voltage 15";
CM_ SG_ 1004 BMS_CellVoltage14 "BMS Cell Voltage 14";
CM_ SG_ 1004 BMS_CellVoltage13 "BMS Cell Voltage 13";
CM_ SG_ 1004 BMS_CellVoltage12 "BMS Cell Voltage 12";
CM_ SG_ 1004 BMS_CellVoltage11 "BMS Cell Voltage 11";
CM_ SG_ 1004 BMS_CellVoltage10 "BMS Cell Voltage 10";
CM_ SG_ 1004 BMS_CellVoltage1 "BMS Cell Voltage 1";
CM_ SG_ 1004 BMS_CellVoltage_Index "BMS cell Voltage Index";
CM_ SG_ 770 REQ_ACC_ON "Request AC Compressor ON/OFF";
CM_ SG_ 770 COMPRESSURE_SPD "Target Compressor Speed request from ETC";
CM_ SG_ 541 TYRE_POSITION_AUTOLOCATED "Gives information on which tyres have got autolocated with new id values. 
BIT0 = FRONT LEFT
BIT1= FRONT RGHT
BIT2= REAR RIGHT
BIT3= REAR LEFT
0-Not learned, 1-Learned


Signal protected";
CM_ SG_ 541 FILLING_SPARE_TYRE "FILLING OF SPARE TIRE
Signal protected";
CM_ SG_ 541 FILLING_RR "FILLING OF REAR RIGHT TIRE
Signal protected";
CM_ SG_ 541 FILLING_RL "FILLING OF REAR LEFT TIRE
Signal protected";
CM_ SG_ 541 FILLING_FR "FILLING OF FRONT RIGHT TIRE
Signal protected";
CM_ SG_ 541 FILLING_FL "FILLING OF FRONT LEFT TIRE
Signal protected";
CM_ SG_ 537 TPMS_SYSTEM_FAULT_TPMS "TPMS Malfunction Indication - Sensor Low Battery/ Transmitter Fault

Bit description
0      Front Left tyre
1      Front Right tyre
2      Rear Right tyre
3      Rear Left tyre
4      TPMS Receiver Fault

0 : Normal
1 : Faulty";
CM_ SG_ 537 TPMS_SIGNAL_MISSING_TPMS "Bit Position Description :-
Bit 0 : FL tyre
Bit 1 : FR tyre
Bit 2 : RR tyre
Bit 3 : RL tyre

Value Description :-
0 : Normal
1 : Signal missing";
CM_ SG_ 537 TPMS_LEAKAGE_ALERT_TPMS "Bit Position Description :-
Bit 0 : FL tyre
Bit 1 : FR tyre
Bit 2 : RR tyre
Bit 3 : RL tyre
Bit 4 : Spare tyre

Value Description :-
0 : Normal
1 : Leakage";
CM_ SG_ 769 REMAINING_OIL_LIFE_PERCENT "The initial defult value is 100%";
CM_ SG_ 769 BATT_OCV "Batterry open circuit voltage (OCV)";
CM_ SG_ 555 FLOAT_SENSOR_RESISTANCE_RAW "Fuel Float Resistance value";
CM_ BO_ 918 "The message contains information about lights locations and angles to them";
CM_ SG_ 918 HBA_USM_FB "User have to enable HBA function then as a feedback this Signal is given by  HBA to User to indicate whether HBA function is enabled or Not";
CM_ SG_ 918 HBA_STS "This signal indicated HBA system states";
CM_ SG_ 918 HBA_LAMP_STS "HBA Lamp Status";
CM_ BO_ 902 "BLDC parameters";
CM_ SG_ 902 COMPRESSOR_TEMPERATURE "Compressor Temperature";
CM_ SG_ 902 ACC_CTRL_OUTPUT_POWER "AC Compressor Output Power";
CM_ BO_ 901 "BLDC parameters, faults";
CM_ SG_ 901 ACC_CONTROLLER_OVERHEAT_FAULT "ACC Controller Overheat";
CM_ SG_ 901 ACC_OVERCURRENT_FAULT "ACC Over Current Fault";
CM_ SG_ 901 ACC_OVERVOLTAGE_FAULT "Over Voltage Fault";
CM_ SG_ 901 ACC_UNDERVOLTAGE_FAULT "Under Voltage Fault";
CM_ SG_ 901 ACC_MOTOR_OVERHEAT_FAULT "ACC Motor Overheat Fault";
CM_ SG_ 901 ACC_INPUT_DC_CURRENT "Input DC current";
CM_ SG_ 901 ACC_COM_FAULT "ACC Communicaion Fault";
CM_ SG_ 632 TGS_MODE "Mode Switch State";
CM_ SG_ 632 INDC_AT_MALFUNC "Tell tale lamp indicator for Transmission Failure";
CM_ SG_ 632 TRANS_MIL_LAMP "MIL";
CM_ SG_ 632 TGS_LEVER "Transmission Gear Select lever position.
";
CM_ BO_ 849 "MBFM control status for app control";
CM_ SG_ 849 TIRE_FILL_LOCATION "BIT 0:- Front Left Tire 
BIT 1:- Front Right Tire
BIT 2:- Rear RightTire
BIT 3:- Rear LeftTire
BIT 4:- SpareTire


0x0:-No Alert / DV
0x1:-Tyre Fill Alert";
CM_ SG_ 849 TPMS_SENSOR_FAULT_STS "BIT 0:- Front Left Tire 
BIT 1:- Front Right Tire
BIT 2:- Rear LeftTire
BIT 3:- Rear RightTire


0x0:-No Fault / DV
0x1:-TPMS Sensor Faulty";
CM_ SG_ 849 TPMS_SENSOR_BAT_STS "BIT 0:- Front Left Tire 
BIT 1:- Front Right Tire
BIT 2:- Rear LeftTire
BIT 3:- Rear RightTire


0x0:- Normal battery / DV
0x1:-TPMS Sensor Low Battery";
CM_ SG_ 849 STS_WIPER_SWT "status wiper switch";
CM_ SG_ 849 STS_SIREN "Status of siren";
CM_ SG_ 849 RF_INTERFERENCE_STS "BIT 0:- Front Left Tire
BIT 1:- Front Right Tire
BIT 2:- Rear LeftTire
BIT 3:- Rear RightTire


0x0:- No interference/ DV
0x1:- Interference Detected";
CM_ SG_ 849 STS_REAR_WIPER_SWT "Rear wiper switch status";
CM_ SG_ 849 STS_FRNT_WIPER "Status of front wiper";
CM_ SG_ 849 STS_AMB_LIGHT "Status of roof lamp";
CM_ SG_ 271 STS_IGN_ESC "
IVN Remark: for S201 program only TCMPFI ECU required wheel speed information for rough road detection.";
CM_ SG_ 271 WHL_RR_SPD "Wheel Speed Rear Right";
CM_ SG_ 271 WHL_RL_SPD "Wheel Speed Rear Left";
CM_ SG_ 271 WHL_FR_SPD "BCM: for SBL function Wheel speed required

IVN Remark: for S201 program only TCMPFI ECU required wheel speed information for rough road detection.";
CM_ SG_ 271 WHL_FL_SPD "BCM: for SBL function Wheel speed required

IVN Remark: for S201 program only TCMPFI ECU required wheel speed information for rough road detection.";
CM_ SG_ 271 ESC8_MSG_CNT "ESC8 message counter";
CM_ SG_ 271 ESC8_CRC "ESC8 message checksum";
CM_ SG_ 704 STS_SEAT_BLT_DRV "For EMS,
0x2 - Buckle Faulty / Onfail Value";
CM_ SG_ 276 STS_SAS_TRIM "EMS(TCMPFI) will use SAS message for the IDLE control calibration";
CM_ SG_ 276 STS_SAS_INTERNAL "EMS(TCMPFI) will use SAS message for the IDLE control calibration";
CM_ SG_ 276 STS_SAS_FAILURE "EMS(TCMPFI) will use SAS message for the IDLE control calibration";
CM_ SG_ 276 STS_SAS_CALIB "EMS(TCMPFI) will use SAS message for the IDLE control calibration";
CM_ SG_ 276 SAS_MSG_CNT "EMS(TCMPFI) will use SAS message for the IDLE control calibration";
CM_ SG_ 276 SAS_CRC "EMS(TCMPFI) will use SAS message for the IDLE control calibration";
CM_ SG_ 276 ANGLE_SPD "EMS(TCMPFI) will use SAS message for the IDLE control calibration";
CM_ SG_ 276 ABSOLUTE_ANGLE "EMS(TCMPFI) will use SAS message for the IDLE control calibration";
CM_ SG_ 540 TRANSFER_MODE_IC "2WD/4WD Status
this signal to be mapped to EMS only";
CM_ SG_ 960 VIN_INDEX "vehicle identification index";
CM_ SG_ 960 VIN_DATA_2 "vehicle identification no. - byte2";
CM_ SG_ 960 VIN_DATA_1 "vehicle identification no. - byte1";
CM_ SG_ 960 VIN_DATA_0 "vehicle identification no. - byte0";
CM_ SG_ 293 ENG_SPD_RATE "Engine Speed Change Rate";
CM_ SG_ 292 ACC_PED "Accelaratore Pedal position
";
CM_ SG_ 292 STS_WATER_IN_FUEL "Water in fuel signal

this signal to be mapped to EMS only";
CM_ SG_ 292 STS_ENG "during vehicle crank all partner ECU would observe Battery Voltage dip.

 
hence Network monitoring should be OFF during this event & Low voltage DTC should not logged by any ECU.";
CM_ SG_ 269 ABS_ACTIVE "ABS Active/Not active indication

this is functional signal to enable or disable ABS function
no other ECU receives this signal.";
CM_ SG_ 312 VACCUM_PUMP_LIFE "Vaccum Pump Life";
CM_ SG_ 312 VACCUM_CONTROL "Brake Vaccum Management";
CM_ SG_ 312 WHL_RR_SPD "Wheel Speed Rear Right";
CM_ SG_ 312 WHL_RL_SPD "Wheel Speed Rear Left";
CM_ SG_ 312 WHL_FR_SPD "BCM: for SBL function Wheel speed required

IVN Remark: for S201 program only TCMPFI ECU required wheel speed information for rough road detection.";
CM_ SG_ 312 WHL_FL_SPD "BCM: for SBL function Wheel speed required

IVN Remark: for S201 program only TCMPFI ECU required wheel speed information for rough road detection.";
CM_ SG_ 716 HHC_ACTIVE "hill hold control active status- applicable for ESC";
CM_ SG_ 716 STS_HHC "Hill Hold status- applicable only from ESC";
CM_ SG_ 832 TRANSFER_MODE_IC "2WD/4WD Status
this signal to be mapped to EMS only";
CM_ SG_ 832 MANUAL_REGEN_REQ "Regeneration request will be transmitted by IC until regen started by EMS or for 10sec, whichever is earlier.";
CM_ SG_ 832 PSGR_AIRBAG_SW_IC "This will indicate passenger airbag switch";
CM_ SG_ 832 ODOMTR_READING "ODOMETER VALUE";
CM_ SG_ 529 CLU_FLEX_STEER_SW "Flex Steer";
CM_ BO_ 840 "MBFM1_100";
CM_ SG_ 840 SECURITY_LED_MBFM "SECURITY LED MBFM";
CM_ SG_ 840 PARK_LAMP_ON_REMINDER "Park Lamp ON Reminder";
CM_ SG_ 840 KEY_IN_REMINDER "Key In Reminder";
CM_ SG_ 840 STS_LOW_BEAM "Status of High Beam Indicator";
CM_ SG_ 840 STS_HIGH_BEAM "Status of High Beam Indicator";
CM_ SG_ 840 STS_SEAT_BLT_DRV_MBFM "For EMS,
0x2 - Buckle Faulty / Onfail Value";
CM_ SG_ 840 STS_DOOR "Status of Back, Hood, Co-Driver, Driver, Rear Left and Rear Right Doors. 
Bit0 - Back , Bit1 - Hood ,Bit2 - Co-Driver , Bit3 - Driver , Bit4 - Rear Left , Bit5 - Rear Right
0 - Closed, 1 - Open
";
CM_ SG_ 556 LKA_HANDSOFF_DISPLAY_WARNING "Handsoff warning for the driver";
CM_ SG_ 556 TJA_STATE "TJA system state indication";
CM_ SG_ 556 TJA_HANDSOFF_WARNING "TJA warnings";
CM_ SG_ 556 LKA_HANDSOFF_AUDIO_WARNING "Handsoff warning for the driver";
CM_ SG_ 556 LDW_LKA_WARNING "Left/Right Lane departure Warning to user";
CM_ SG_ 556 LDW_LKA_LANE_RECOGN "This signal describes the recognized Lane by Camera module";
CM_ SG_ 2021 DIAG_MBFM_REQ_DATA "Keyword 2000 Diagnostic Message Request Data";
CM_ SG_ 776 DISP_AMBT_TEMP_EMS "Outside Air Temperature";
CM_ SG_ 1920 DIAG_VCU_REQ_DATA "Diagnostic Req from Tool to VCU";
CM_ SG_ 778 Reduce_Power_Mode_TT "Safe Mode TT status";
CM_ SG_ 778 REGEN_LEVELS "Regeneration levels";
CM_ SG_ 778 Sts_Regen_Cutoff_TT "Regeneration status";
CM_ SG_ 778 LOW_AUX_BATT_TT "Low Auxiliary Battery";
CM_ SG_ 778 HIGH_TEMP_LIGHT_OP "High Temperature Light Output Status";
CM_ SG_ 778 STS_SERVICE_LIGHT_TT "Service Light Status";
CM_ SG_ 778 STS_HV_BATT_TT "HV Battery Tell Tale Status";
CM_ SG_ 778 STS_EVWARNING_TT "Electric Vehicle Warning Status";
CM_ SG_ 778 STS_CHARGE_LIGHT_TT "Charge Light Status";
CM_ SG_ 778 ALERT_MSGS "Alert Messages for User";
CM_ SG_ 778 PRESS_BRAKE "PRESS BRAKE";
CM_ SG_ 778 EV_READY_TT "EV Ready Tell Tale only";
CM_ SG_ 778 DRIVE_EFFICIENCY "Drive Efficiency
More Power Less Efficiency
Less Power High Efficiency";
CM_ SG_ 778 TIME_TO_CHARGE_VCU "Time to Charge";
CM_ SG_ 778 STATE_OF_CHARGE "State of Charge";
CM_ SG_ 778 INDC_DRIVE_ENABLE "to indication drive is enabled- should stay in this value as long as drive in enabled.";
CM_ SG_ 778 GEAR_ACTUAL_VCU "Drive Mode";
CM_ SG_ 1424 VEHICLE_MODE "Vehicle Mode";
CM_ SG_ 1424 VESS_DISABLE "Disable VESS through CAN";
CM_ SG_ 2015 DIAG_GLOBAL_REQ_DATA "Keyword 2000 Diagnostic Message Request Data";
BA_DEF_ SG_  "SignalType" STRING ;
BA_DEF_ SG_  "SignalCategory" HEX 10 15;
BA_DEF_ SG_  "GenSigTimeoutTime_IS" INT 0 65535;
BA_DEF_ SG_  "CmxSigDefaultRaw" HEX 0 2147483647;
BA_DEF_ SG_  "GwSigLatencyTime" INT 0 65535;
BA_DEF_ SG_  "GwSigMissingSourceType" ENUM  "Undef","OldValue","DefaultValue","InitialValue";
BA_DEF_ SG_  "GenSigEnvVarType" ENUM  "int","float","undef";
BA_DEF_ SG_  "GenSigEVName" STRING ;
BA_DEF_ SG_  "GenSigStartValue" INT 0 0;
BA_DEF_ SG_  "GenSigSendType" ENUM  "Cyclic","OnWrite","OnWriteWithRepetition","OnChange","OnChangeWithRepetition","IfActive","IfActiveWithRepetition","NoSigSendType";
BA_DEF_ SG_  "GenSigInactiveValue" INT 0 0;
BA_DEF_ SG_  "SigCreator" STRING ;
BA_DEF_ BO_  "NWM-Botschaft" ENUM  "nein","ja";
BA_DEF_ BO_  "GenMsgNrOfRepetitions" INT 1 999999;
BA_DEF_ BO_  "MsgCreator" STRING ;
BA_DEF_ BO_  "GenMsgTimeOut" INT 0 0;
BA_DEF_ BO_  "DiagState" ENUM  "No","Yes";
BA_DEF_ BO_  "DiagRequest" ENUM  "No","Yes";
BA_DEF_ BO_  "DiagResponse" ENUM  "No","Yes";
BA_DEF_ BO_  "TpTxIndex" INT 0 255;
BA_DEF_ BO_  "GenMsgILSupport" ENUM  "No","Yes";
BA_DEF_ BO_  "GenMsgNrOfRepetition" INT 0 3;
BA_DEF_ BO_  "GenMsgDelayTime" INT 0 0;
BA_DEF_ BO_  "GenMsgCycleTimeFast" INT 0 500;
BA_DEF_ BO_  "GenMsgStartDelayTime" INT 0 140;
BA_DEF_ BO_  "GenMsgSendType" ENUM  "Cyclic","Spontaneous","not_used","not_used","not_used","Cyclic","not_used","IfActive","NoMsgSendType";
BA_DEF_ BO_  "GenMsgCycleTime" INT 0 0;
BA_DEF_REL_ BU_SG_REL_  "GenSigTimeoutTime" INT 30 3500;
BA_DEF_DEF_  "SignalType" "";
BA_DEF_DEF_  "SignalCategory" 10;
BA_DEF_DEF_  "GenSigTimeoutTime_IS" 0;
BA_DEF_DEF_  "CmxSigDefaultRaw" 0;
BA_DEF_DEF_  "GwSigLatencyTime" 40;
BA_DEF_DEF_  "GwSigMissingSourceType" "Undef";
BA_DEF_DEF_  "GenSigEnvVarType" "undef";
BA_DEF_DEF_  "GenSigEVName" "";
BA_DEF_DEF_  "GenSigStartValue" 0;
BA_DEF_DEF_  "GenSigSendType" "Cyclic";
BA_DEF_DEF_  "GenSigInactiveValue" 0;
BA_DEF_DEF_  "SigCreator" "M&M-IVN";
BA_DEF_DEF_  "NWM-Botschaft" "nein";
BA_DEF_DEF_  "GenMsgNrOfRepetitions" 1;
BA_DEF_DEF_  "MsgCreator" "M&M-IVN";
BA_DEF_DEF_  "GenMsgTimeOut" 0;
BA_DEF_DEF_  "DiagState" "No";
BA_DEF_DEF_  "DiagRequest" "No";
BA_DEF_DEF_  "DiagResponse" "No";
BA_DEF_DEF_  "TpTxIndex" 0;
BA_DEF_DEF_  "GenMsgILSupport" "Yes";
BA_DEF_DEF_  "GenMsgNrOfRepetition" 0;
BA_DEF_DEF_  "GenMsgDelayTime" 0;
BA_DEF_DEF_  "GenMsgCycleTimeFast" 0;
BA_DEF_DEF_  "GenMsgStartDelayTime" 0;
BA_DEF_DEF_  "GenMsgSendType" "Cyclic";
BA_DEF_DEF_  "GenMsgCycleTime" 0;
BA_DEF_DEF_REL_ "GenSigTimeoutTime" 1400;
BA_ "GenMsgSendType" BO_ 1911 1;
BA_ "DiagRequest" BO_ 1911 1;
BA_ "GenMsgSendType" BO_ 1980 1;
BA_ "DiagState" BO_ 1980 1;
BA_ "GenMsgSendType" BO_ 2008 1;
BA_ "GenMsgCycleTime" BO_ 579 20;
BA_ "GenMsgSendType" BO_ 936 1;
BA_ "GenMsgSendType" BO_ 1933 1;
BA_ "DiagState" BO_ 1933 1;
BA_ "GenMsgSendType" BO_ 1981 1;
BA_ "DiagState" BO_ 1981 1;
BA_ "GenMsgSendType" BO_ 1976 1;
BA_ "DiagState" BO_ 1976 1;
BA_ "GenMsgSendType" BO_ 1972 1;
BA_ "DiagRequest" BO_ 1972 1;
BA_ "DiagState" BO_ 1972 1;
BA_ "GenMsgSendType" BO_ 1925 1;
BA_ "DiagRequest" BO_ 1925 1;
BA_ "DiagState" BO_ 1925 1;
BA_ "GenMsgSendType" BO_ 1973 1;
BA_ "DiagRequest" BO_ 1973 1;
BA_ "DiagState" BO_ 1973 1;
BA_ "GenMsgSendType" BO_ 2000 1;
BA_ "DiagRequest" BO_ 2000 1;
BA_ "DiagState" BO_ 2000 1;
BA_ "GenMsgSendType" BO_ 1968 1;
BA_ "DiagRequest" BO_ 1968 1;
BA_ "DiagState" BO_ 1968 1;
BA_ "GenMsgCycleTime" BO_ 336 50;
BA_ "GenMsgCycleTime" BO_ 285 10;
BA_ "GenMsgSendType" BO_ 1954 1;
BA_ "DiagRequest" BO_ 1954 1;
BA_ "GenMsgSendType" BO_ 1962 1;
BA_ "DiagResponse" BO_ 1962 1;
BA_ "GenMsgCycleTime" BO_ 920 100;
BA_ "GenMsgCycleTime" BO_ 921 100;
BA_ "GenMsgCycleTime" BO_ 667 100;
BA_ "GenMsgCycleTime" BO_ 654 100;
BA_ "GenMsgCycleTime" BO_ 662 100;
BA_ "GenMsgCycleTime" BO_ 771 200;
BA_ "GenMsgCycleTime" BO_ 809 100;
BA_ "GenMsgCycleTime" BO_ 1711 2000;
BA_ "GenMsgCycleTime" BO_ 768 200;
BA_ "GenMsgCycleTime" BO_ 1588 1000;
BA_ "GenMsgCycleTime" BO_ 1586 500;
BA_ "GenMsgCycleTime" BO_ 828 100;
BA_ "GenMsgCycleTime" BO_ 806 50;
BA_ "GenMsgSendType" BO_ 2029 1;
BA_ "DiagResponse" BO_ 2029 1;
BA_ "GenMsgCycleTime" BO_ 536 100;
BA_ "GenMsgCycleTime" BO_ 1056 200;
BA_ "GenMsgCycleTime" BO_ 940 100;
BA_ "GenMsgCycleTime" BO_ 1001 100;
BA_ "GenMsgCycleTime" BO_ 1168 200;
BA_ "GenMsgSendType" BO_ 1865 1;
BA_ "DiagResponse" BO_ 1865 1;
BA_ "GenMsgSendType" BO_ 1857 1;
BA_ "GenMsgDelayTime" BO_ 1857 5;
BA_ "GenMsgILSupport" BO_ 1857 0;
BA_ "DiagRequest" BO_ 1857 1;
BA_ "GenMsgCycleTime" BO_ 965 100;
BA_ "GenMsgCycleTime" BO_ 159 20;
BA_ "GenMsgSendType" BO_ 942 1;
BA_ "GenMsgNrOfRepetition" BO_ 942 1;
BA_ "GenMsgCycleTime" BO_ 943 100;
BA_ "GenMsgCycleTime" BO_ 954 100;
BA_ "GenMsgCycleTime" BO_ 564 100;
BA_ "GenMsgCycleTime" BO_ 743 50;
BA_ "GenMsgCycleTime" BO_ 1416 500;
BA_ "GenMsgCycleTime" BO_ 812 100;
BA_ "GenMsgSendType" BO_ 250 1;
BA_ "GenMsgCycleTime" BO_ 1408 500;
BA_ "GenMsgCycleTime" BO_ 977 100;
BA_ "GenMsgCycleTime" BO_ 958 100;
BA_ "GenMsgCycleTime" BO_ 976 100;
BA_ "GenMsgCycleTime" BO_ 532 100;
BA_ "GenMsgCycleTime" BO_ 843 100;
BA_ "GenMsgCycleTime" BO_ 151 20;
BA_ "GenMsgSendType" BO_ 964 1;
BA_ "GenMsgNrOfRepetition" BO_ 964 1;
BA_ "GenMsgCycleTime" BO_ 961 100;
BA_ "GenMsgCycleTime" BO_ 869 100;
BA_ "GenMsgSendType" BO_ 266 1;
BA_ "GenMsgCycleTime" BO_ 851 100;
BA_ "GenMsgCycleTime" BO_ 1088 200;
BA_ "GenMsgStartDelayTime" BO_ 1088 20;
BA_ "GenMsgCycleTimeFast" BO_ 1088 40;
BA_ "GenMsgNrOfRepetition" BO_ 1088 3;
BA_ "GenMsgCycleTime" BO_ 834 100;
BA_ "GenMsgCycleTime" BO_ 647 100;
BA_ "GenMsgCycleTime" BO_ 150 20;
BA_ "GenMsgSendType" BO_ 966 1;
BA_ "GenMsgNrOfRepetition" BO_ 966 1;
BA_ "GenMsgCycleTime" BO_ 963 100;
BA_ "GenMsgCycleTime" BO_ 587 20;
BA_ "GenMsgCycleTime" BO_ 928 50;
BA_ "GenMsgCycleTime" BO_ 588 20;
BA_ "GenMsgSendType" BO_ 1843 1;
BA_ "DiagRequest" BO_ 1843 1;
BA_ "GenMsgCycleTime" BO_ 826 100;
BA_ "GenMsgCycleTime" BO_ 829 10;
BA_ "GenMsgCycleTime" BO_ 655 100;
BA_ "GenMsgCycleTime" BO_ 651 100;
BA_ "GenMsgCycleTime" BO_ 649 100;
BA_ "GenMsgCycleTime" BO_ 310 10;
BA_ "GenMsgCycleTime" BO_ 645 100;
BA_ "GenMsgCycleTime" BO_ 643 100;
BA_ "GenMsgCycleTime" BO_ 322 10;
BA_ "GenMsgCycleTime" BO_ 642 10;
BA_ "GenMsgSendType" BO_ 646 1;
BA_ "GenMsgCycleTime" BO_ 543 500;
BA_ "GenMsgCycleTime" BO_ 1089 200;
BA_ "GenMsgTimeOut" BO_ 1089 1000;
BA_ "GenMsgCycleTime" BO_ 650 100;
BA_ "GenMsgCycleTime" BO_ 545 100;
BA_ "GenMsgDelayTime" BO_ 545 5;
BA_ "GenMsgSendType" BO_ 1851 1;
BA_ "DiagResponse" BO_ 1851 1;
BA_ "GenMsgCycleTime" BO_ 1407 100;
BA_ "GenMsgCycleTime" BO_ 589 20;
BA_ "GenMsgDelayTime" BO_ 589 20;
BA_ "GenMsgCycleTime" BO_ 592 10;
BA_ "GenMsgTimeOut" BO_ 592 250;
BA_ "GenMsgCycleTime" BO_ 971 500;
BA_ "GenMsgCycleTime" BO_ 299 100;
BA_ "GenMsgCycleTime" BO_ 1004 100;
BA_ "GenMsgCycleTime" BO_ 770 200;
BA_ "GenMsgSendType" BO_ 1849 1;
BA_ "GenMsgSendType" BO_ 1841 1;
BA_ "GenMsgCycleTime" BO_ 541 100;
BA_ "GenMsgCycleTime" BO_ 542 100;
BA_ "GenMsgCycleTime" BO_ 537 100;
BA_ "GenMsgSendType" BO_ 1872 1;
BA_ "GenMsgILSupport" BO_ 1872 0;
BA_ "DiagRequest" BO_ 1872 1;
BA_ "GenMsgCycleTime" BO_ 970 500;
BA_ "GenMsgSendType" BO_ 1880 1;
BA_ "DiagResponse" BO_ 1880 1;
BA_ "GenMsgCycleTime" BO_ 769 500;
BA_ "GenMsgCycleTime" BO_ 555 1000;
BA_ "GenMsgCycleTime" BO_ 547 1000;
BA_ "GenMsgCycleTime" BO_ 548 1000;
BA_ "GenMsgSendType" BO_ 2016 1;
BA_ "DiagRequest" BO_ 2016 1;
BA_ "GenMsgSendType" BO_ 2024 1;
BA_ "DiagResponse" BO_ 2024 1;
BA_ "GenMsgCycleTime" BO_ 918 50;
BA_ "GenMsgCycleTime" BO_ 902 500;
BA_ "GenMsgCycleTime" BO_ 901 500;
BA_ "GenMsgCycleTime" BO_ 632 20;
BA_ "GenMsgCycleTime" BO_ 849 100;
BA_ "GenMsgSendType" BO_ 2020 1;
BA_ "GenMsgSendType" BO_ 2028 1;
BA_ "DiagResponse" BO_ 2028 1;
BA_ "GenMsgCycleTime" BO_ 369 20;
BA_ "GenMsgCycleTime" BO_ 368 20;
BA_ "GenMsgCycleTime" BO_ 271 20;
BA_ "GenMsgCycleTime" BO_ 544 100;
BA_ "GenMsgCycleTime" BO_ 704 20;
BA_ "GenMsgTimeOut" BO_ 704 100;
BA_ "GenMsgCycleTime" BO_ 276 10;
BA_ "GenMsgCycleTime" BO_ 540 100;
BA_ "GenMsgCycleTime" BO_ 306 10;
BA_ "GenMsgCycleTimeFast" BO_ 306 100;
BA_ "GenMsgDelayTime" BO_ 306 20;
BA_ "GenMsgTimeOut" BO_ 306 100;
BA_ "GenMsgCycleTime" BO_ 960 500;
BA_ "GenMsgCycleTime" BO_ 293 10;
BA_ "GenMsgCycleTime" BO_ 292 10;
BA_ "GenMsgTimeOut" BO_ 292 100;
BA_ "GenMsgCycleTime" BO_ 269 10;
BA_ "GenMsgCycleTime" BO_ 312 20;
BA_ "GenMsgCycleTime" BO_ 716 10;
BA_ "GenMsgCycleTime" BO_ 832 100;
BA_ "GenMsgTimeOut" BO_ 832 1000;
BA_ "GenMsgCycleTime" BO_ 529 100;
BA_ "GenMsgCycleTime" BO_ 840 100;
BA_ "GenMsgSendType" BO_ 1848 1;
BA_ "GenMsgDelayTime" BO_ 1848 20;
BA_ "DiagResponse" BO_ 1848 1;
BA_ "GenMsgCycleTime" BO_ 556 10;
BA_ "GenMsgCycleTime" BO_ 665 100;
BA_ "GenMsgSendType" BO_ 1840 1;
BA_ "GenMsgDelayTime" BO_ 1840 20;
BA_ "DiagRequest" BO_ 1840 1;
BA_ "GenMsgSendType" BO_ 1970 1;
BA_ "GenMsgDelayTime" BO_ 1970 20;
BA_ "TpTxIndex" BO_ 1970 106;
BA_ "DiagRequest" BO_ 1970 1;
BA_ "GenMsgSendType" BO_ 1978 1;
BA_ "GenMsgDelayTime" BO_ 1978 20;
BA_ "TpTxIndex" BO_ 1978 106;
BA_ "DiagResponse" BO_ 1978 1;
BA_ "GenMsgSendType" BO_ 1912 1;
BA_ "GenMsgDelayTime" BO_ 1912 5;
BA_ "DiagResponse" BO_ 1912 1;
BA_ "GenMsgSendType" BO_ 1904 1;
BA_ "GenMsgDelayTime" BO_ 1904 5;
BA_ "DiagRequest" BO_ 1904 1;
BA_ "GenMsgSendType" BO_ 2021 1;
BA_ "GenMsgDelayTime" BO_ 2021 20;
BA_ "TpTxIndex" BO_ 2021 101;
BA_ "GenMsgSendType" BO_ 2026 1;
BA_ "GenMsgCycleTimeFast" BO_ 2026 100;
BA_ "GenMsgDelayTime" BO_ 2026 5;
BA_ "TpTxIndex" BO_ 2026 102;
BA_ "DiagResponse" BO_ 2026 1;
BA_ "GenMsgSendType" BO_ 2018 1;
BA_ "GenMsgDelayTime" BO_ 2018 5;
BA_ "TpTxIndex" BO_ 2018 102;
BA_ "DiagRequest" BO_ 2018 1;
BA_ "GenMsgCycleTime" BO_ 776 500;
BA_ "GenMsgDelayTime" BO_ 776 20;
BA_ "GenMsgTimeOut" BO_ 776 5000;
BA_ "GenMsgSendType" BO_ 1928 1;
BA_ "GenMsgDelayTime" BO_ 1928 5;
BA_ "DiagResponse" BO_ 1928 1;
BA_ "DiagState" BO_ 1928 1;
BA_ "GenMsgSendType" BO_ 1920 1;
BA_ "GenMsgDelayTime" BO_ 1920 5;
BA_ "DiagRequest" BO_ 1920 1;
BA_ "DiagState" BO_ 1920 1;
BA_ "GenMsgCycleTime" BO_ 778 100;
BA_ "GenMsgCycleTime" BO_ 1424 500;
BA_ "GenMsgSendType" BO_ 2015 1;
BA_ "GenMsgDelayTime" BO_ 2015 20;
BA_ "DiagState" BO_ 2015 1;
BA_ "GenSigStartValue" SG_ 771 DISP_AMBT_TEMP_FATC 40;
BA_ "CmxSigDefaultRaw" SG_ 771 DISP_AMBT_TEMP_FATC 255;
BA_ "GenSigSendType" SG_ 768 INCAR_TEMP 7;
BA_ "GenSigStartValue" SG_ 1586 HEATER_TEMP 40;
BA_ "GenSigSendType" SG_ 2029 DIAG_MBFM_RES_DATA 7;
BA_ "GenSigSendType" SG_ 965 RESERVED_2 7;
BA_ "GenSigSendType" SG_ 942 RESERVED_2 7;
BA_ "GenSigSendType" SG_ 564 RESERVED_2 7;
BA_ "GenSigStartValue" SG_ 743 MOTOR_PWR 32768;
BA_ "GenSigStartValue" SG_ 743 POWER_REGEN_METER 100;
BA_ "GenSigSendType" SG_ 958 RESERVED_2 7;
BA_ "GenSigSendType" SG_ 964 RESERVED_2 7;
BA_ "GenSigSendType" SG_ 961 RESERVED_2 7;
BA_ "GenSigSendType" SG_ 266 IMMOVAL5 7;
BA_ "GenSigSendType" SG_ 966 RESERVED_2 7;
BA_ "GenSigSendType" SG_ 963 RESERVED_2 7;
BA_ "GenSigSendType" SG_ 588 ACC_DRIVE_MODE 7;
BA_ "GenSigStartValue" SG_ 826 INDC_ROLL 62;
BA_ "GenSigStartValue" SG_ 826 INDC_PITCH 62;
BA_ "GenSigSendType" SG_ 310 SHIFTING 7;
BA_ "GenSigEnvVarType" SG_ 310 SHIFTING 0;
BA_ "GenSigSendType" SG_ 310 GEAR_TARGET 7;
BA_ "GenSigEnvVarType" SG_ 310 GEAR_TARGET 0;
BA_ "GenSigSendType" SG_ 310 GEAR_ACTUAL 7;
BA_ "GenSigEnvVarType" SG_ 310 GEAR_ACTUAL 0;
BA_ "GenSigStartValue" SG_ 322 DRIVER_DEMAND_TRQ_EMS36 1024;
BA_ "GenSigStartValue" SG_ 322 ENG_TRQ_AFTR_RED1 1024;
BA_ "GenSigStartValue" SG_ 1089 USM_RESET 1;
BA_ "GenSigSendType" SG_ 545 STS_EPS_STEERING_MODE 7;
BA_ "GenSigSendType" SG_ 545 EPS_STEERING_MODE_ALERT 7;
BA_ "GenSigSendType" SG_ 545 EPS_STEERING_MODE 7;
BA_ "GenSigSendType" SG_ 592 SBW_FAULT 7;
BA_ "GenSigEnvVarType" SG_ 592 SBW_FAULT 0;
BA_ "GenSigSendType" SG_ 592 SBW_LEVER 7;
BA_ "GenSigEnvVarType" SG_ 592 SBW_LEVER 0;
BA_ "GenSigStartValue" SG_ 970 CLOCK_YEAR 16;
BA_ "GenSigEnvVarType" SG_ 555 CALCULATED_DTE 0;
BA_ "GenSigEnvVarType" SG_ 555 CALCULATED_AFE 1;
BA_ "GenSigEnvVarType" SG_ 555 VEHICLE_SPEED_IC 1;
BA_ "GenSigSendType" SG_ 548 AFE_ACCUMULATED_FUEL_CONSMP 7;
BA_ "GenSigSendType" SG_ 548 AFE_ACCUMULATED_DISTANCE 7;
BA_ "GenSigSendType" SG_ 2024 DIAG_EMS_RES_DATA 7;
BA_ "GenSigSendType" SG_ 632 TGS_MODE 7;
BA_ "GenSigEnvVarType" SG_ 632 TGS_MODE 0;
BA_ "SignalType" SG_ 632 TGS_MODE "ENM";
BA_ "GenSigSendType" SG_ 632 INDC_AT_MALFUNC 7;
BA_ "GenSigEnvVarType" SG_ 632 INDC_AT_MALFUNC 0;
BA_ "GenSigSendType" SG_ 632 TRANS_MIL_LAMP 7;
BA_ "GenSigEnvVarType" SG_ 632 TRANS_MIL_LAMP 0;
BA_ "GenSigSendType" SG_ 632 TGS_LEVER 7;
BA_ "GenSigEnvVarType" SG_ 632 TGS_LEVER 0;
BA_ "GenSigTimeoutTime_IS" SG_ 632 TGS_LEVER 100;
BA_ "SignalType" SG_ 632 TGS_LEVER "ENM";
BA_ "GenSigStartValue" SG_ 369 MASTER_CYL_PRESSURE 800;
BA_ "GenSigStartValue" SG_ 368 YAW_RATE 32768;
BA_ "GenSigSendType" SG_ 271 WHL_RR_SPD 7;
BA_ "GenSigSendType" SG_ 271 WHL_RL_SPD 7;
BA_ "GenSigSendType" SG_ 704 STS_SEAT_BLT_PSGR 7;
BA_ "GenSigSendType" SG_ 704 STS_SEAT_BLT_DRV 7;
BA_ "GenSigSendType" SG_ 540 TRANSFER_MODE_IC 7;
BA_ "GenSigEVName" SG_ 540 TRANSFER_MODE_IC "@Msgname@Signame";
BA_ "GenSigEnvVarType" SG_ 540 TRANSFER_MODE_IC 0;
BA_ "SignalType" SG_ 540 TRANSFER_MODE_IC "ENM";
BA_ "GenSigSendType" SG_ 540 AUTO_RAIN 7;
BA_ "GenSigSendType" SG_ 540 AUTO_LIGHT 7;
BA_ "GenSigSendType" SG_ 960 VIN_INDEX 7;
BA_ "GenSigTimeoutTime_IS" SG_ 960 VIN_INDEX 5000;
BA_ "GenSigSendType" SG_ 960 VIN_DATA_0 7;
BA_ "GenSigSendType" SG_ 293 ENG_SPD_RATE 7;
BA_ "GenSigStartValue" SG_ 293 ENG_SPD_RATE 32768;
BA_ "GenSigSendType" SG_ 292 STS_WATER_IN_FUEL 7;
BA_ "GenSigStartValue" SG_ 292 ENG_TEMP 40;
BA_ "GenSigEnvVarType" SG_ 269 ABS_ACTIVE 0;
BA_ "GenSigTimeoutTime_IS" SG_ 312 VACCUM_PUMP_LIFE 200;
BA_ "GenSigTimeoutTime_IS" SG_ 312 VACCUM_CONTROL 200;
BA_ "GenSigSendType" SG_ 312 WHL_RR_SPD 7;
BA_ "GenSigSendType" SG_ 312 WHL_RL_SPD 7;
BA_ "GenSigSendType" SG_ 832 TRANSFER_MODE_IC 7;
BA_ "GenSigEVName" SG_ 832 TRANSFER_MODE_IC "@Msgname@Signame";
BA_ "GenSigEnvVarType" SG_ 832 TRANSFER_MODE_IC 0;
BA_ "SignalType" SG_ 832 TRANSFER_MODE_IC "ENM";
BA_ "GenSigEnvVarType" SG_ 832 SEAT_BELT_REMAINDER_FL_REAR 0;
BA_ "GenSigSendType" SG_ 840 INDC_PARK_BRK 7;
BA_ "GenSigSendType" SG_ 840 INDC_REAR_FOG 7;
BA_ "GenSigSendType" SG_ 840 STS_TRAILER 7;
BA_ "GenSigSendType" SG_ 840 STS_LOW_BEAM 7;
BA_ "GenSigSendType" SG_ 840 STS_HIGH_BEAM 7;
BA_ "GenSigSendType" SG_ 840 INDC_TURN_FLSHR 7;
BA_ "GenSigSendType" SG_ 840 STS_SEAT_BLT_PSGR_MBFM 7;
BA_ "GenSigSendType" SG_ 840 STS_SEAT_BLT_DRV_MBFM 7;
BA_ "GenSigSendType" SG_ 840 STS_DOOR 7;
BA_ "GenSigSendType" SG_ 1848 DIAG_SRS_RES_DATA 7;
BA_ "GenSigSendType" SG_ 1840 DIAG_SRS_REQ_DATA 7;
BA_ "GenSigSendType" SG_ 1970 DIAG_PKE_REQ_DATA 7;
BA_ "GenSigSendType" SG_ 1978 DIAG_PKE_RES_DATA 7;
BA_ "GenSigSendType" SG_ 2021 DIAG_MBFM_REQ_DATA 7;
BA_ "GenSigStartValue" SG_ 776 DISP_AMBT_TEMP_EMS 40;
BA_ "GenSigSendType" SG_ 2015 DIAG_GLOBAL_REQ_DATA 7;
BA_ "GenSigEnvVarType" SG_ 2015 DIAG_GLOBAL_REQ_DATA 0;
VAL_ 579 VCU_EVCAN_WAKEUPREASON 5 "Reserved" 4 "LV Battery Charge" 3 "Wakeup for Fast Charging" 2 "RTC Based Wake Up Trigger" 1 "Wakeup for Normal Charging" 0 "Key On /Ignition " ;
VAL_ 336 BMS_TotalCycle_Time 65535 "SIGNAL INVALID" 0 "DEFAULT VALUE" ;
VAL_ 336 BMS_DischargeCycle_Time 65535 "SIGNAL INVALID" 0 "DEFAULT VALUE" ;
VAL_ 336 BMS_ChargeCycle_Time 65535 "Signal Invalid" 0 "Default Value" ;
VAL_ 336 BMS_CycleNumber 65535 "SIGNAL INVALID" 0 "DEFAULT VALUE" ;
VAL_ 285 BMS_BattPack_PwrLimitErr_Common 1 "Fault" 0 "Default/No Fault" ;
VAL_ 285 BMS_Bat_I_OvrExtCurr_Flt_Dischrg 1 "Fault" 0 "Default/No Fault" ;
VAL_ 285 BMS_Bat_I_OverCurr_Flt_Discharge 1 "Fault" 0 "Default/No Fault" ;
VAL_ 285 BMS_BattOverVolt_Cutoff_Charge 1 "Fault" 0 "Default/No Fault" ;
VAL_ 285 BMS_ClntInlet_High_Temp_Charge 1 "Fault" 0 "Default/No Fault" ;
VAL_ 285 BMS_ClntInlet_Low_Temp_Charge 1 "Fault" 0 "Default/No Fault" ;
VAL_ 285 BMS_ClntOutlet_Low_Temp_Charge 1 "Fault" 0 "Default/No Fault" ;
VAL_ 285 BMS_Clntoutlet_High_Temp_Charge 1 "Fault" 0 "Default/No Fault" ;
VAL_ 285 BMS_BattOver_Temp_Cutoff_common 1 "Fault" 0 "Default/No Fault" ;
VAL_ 285 BMS_BattUnder_Temp_Cutoff_common 1 "Fault" 0 "Default/No Fault" ;
VAL_ 285 BMS_ClntSen_Thres_Fault_Charge 1 "Fault" 0 "Default/No Fault" ;
VAL_ 285 BMS_ReverseCurrDetect_Charge 1 "Fault" 0 "Default/No Fault" ;
VAL_ 285 BMS_PLP_Stop_Charge 1 "Fault" 0 "Default/No Fault" ;
VAL_ 285 BMS_CellUnderVolt_Cutoff_Common 1 "Fault" 0 "Default/No Fault" ;
VAL_ 285 BMS_BattUnderVolt_Cutoff_Common 1 "Fault" 0 "Default/No Fault" ;
VAL_ 285 BMS_ModuleOverTemp_Cutoff_Common 1 "Fault" 0 "Default/No Fault" ;
VAL_ 285 BMS_MdleUnderTemp_Cutoff_Common 1 "Fault" 0 "Default/No Fault" ;
VAL_ 285 BMS_ShortCircuitCurr_Flt_Common 1 "Fault" 0 "Default/No Fault" ;
VAL_ 285 BMS_Sensor_Failure_Common 1 "Fault" 0 "Default/No Fault" ;
VAL_ 285 BMS_Ibatt_392_25sec_Common 1 "Fault" 0 "Default/No Fault" ;
VAL_ 285 BMS_PilotLine_Detect_Common 1 "Fault" 0 "Default/No Fault" ;
VAL_ 285 BMS_Revive_Common 1 "Fault" 0 "Default/No Fault" ;
VAL_ 285 BMS_HeaterSys_Flt_Common 1 "Fault" 0 "Default/No Fault" ;
VAL_ 285 BMS_Clnt_TempSens_Flt_Common 1 "Fault" 0 "Default/No Fault" ;
VAL_ 285 BMS_Heater_Flt_Common 1 "Fault" 0 "Default/No Fault" ;
VAL_ 285 BMS_IsoFLt_Red_Discharge 1 "Fault" 0 "Default/No Fault" ;
VAL_ 285 BMS_LowSOC_Cutoff_Discharge 1 "Fault" 0 "Default/No Fault" ;
VAL_ 285 BMS_Bat_I_ExtCurr_Flt_Dischrg 1 "Fault" 0 "Default/No Fault" ;
VAL_ 285 BMS_MTM_ActvLimit_Common 1 "Fault" 0 "Default/No Fault" ;
VAL_ 285 BMS_ClntSys_Flt_Common 1 "Fault" 0 "Default/No Fault" ;
VAL_ 285 BMS_Pump_DryRun_Err_Common 1 "Fault" 0 "Default/No Fault" ;
VAL_ 285 BMS_CrashDtct_P_F_Open_Common 1 "Fault" 0 "Default/No Fault" ;
VAL_ 285 BMS_HVIL_Err_Dischrg 1 "Fault" 0 "Default/No Fault" ;
VAL_ 285 BMS_No_Cntctr_Close 1 "Fault" 0 "Default/No Fault" ;
VAL_ 285 BMS_CntctrOpen_Rqst_VCU_Dischrg 1 "Fault" 0 "Default/No Fault" ;
VAL_ 285 BMS_CntctrOpen_Rqst_VCU_Chrg 1 "Fault" 0 "Default/No Fault" ;
VAL_ 285 BMS_InitCntctrOpen_Dischrg 1 "Fault" 0 "Default/No Fault" ;
VAL_ 285 BMS_InitCntctrOpen_Charge 1 "Fault" 0 "Default/No Fault" ;
VAL_ 285 BMS_FSBIM_bAcvDrtdMode 1 "Fault" 0 "Default/No Fault" ;
VAL_ 285 BMS_FSPLP_bAcvDrtdMode 1 "Fault" 0 "Default/No Fault" ;
VAL_ 285 BMS_ILC_AcvDrtdCdn 1 "Fault" 0 "Default/No Fault" ;
VAL_ 285 BMS_IDMStsIsInErr_Yellow 1 "Fault" 0 "Default/No Fault" ;
VAL_ 285 BMS_FSPLP_bAcvPackOverUDrtd 1 "Fault" 0 "Default/No Fault" ;
VAL_ 285 BMS_BIM_bAcvHighRateDchaDrdt2 1 "Fault" 0 "Default/No Fault" ;
VAL_ 285 BMS_FSPLP_bAcvPackUnderUDrtd 1 "Fault" 0 "Default/No Fault" ;
VAL_ 285 BMS_BIMbAcvReqDrtdMode 1 "Fault" 0 "Default/No Fault" ;
VAL_ 285 BMS_BTFD_bAcvReqDrtdMode 1 "Fault" 0 "Default/No Fault" ;
VAL_ 285 BMS_CUM_bAcvOwDrtd 1 "Fault" 0 "Default/No Fault" ;
VAL_ 285 BMS_CellOverVolt_Cutoff_Charge 1 "Fault" 0 "Default/No Fault" ;
VAL_ 285 BMS_Reason_HV_Disconnected 5 "CRASH info VIA CAN" 4 "Battery Thermal Runaway" 3 "CRASH_DETECT_P/F_OPEN" 2 "Battery_I_Extreme_Current_Fault" 1 "Battery_I_Ovr_Extreme_Crnt_Fault" 0 "Reserved" ;
VAL_ 285 BMS_Reason_HV_Disconnect_Request 28 "PCB TEMPERATURE_BEYOND_LIMIT" 27 "BMSReversecurrent detetction DTC" 26 "Current_sensor_1_&&2_fail" 25 "BMS short circuit current fault" 24 "BMS_Charge time out" 23 "BMS_Precharge Fail" 22 "Isolation_Fault_Red" 21 "HVIL_OUT_THRESH_Cheater" 20 "HVIL_Cheater_STG" 19 "HVIL_Cheater_STB" 18 "HVIL_OUT_THRESH_Bheater" 17 "HVIL_Bheater_STG" 16 "HVIL_Bheater_STB" 15 "HVIL_OUT_THRESH_BBOX" 14 "HVIL_BBOX_STG" 13 "HVIL_BBOX_STB" 12 "PILOT_PWM,_ERROR" 11 "PUMP_DRY_RUN_ERROR" 10 "BMS LOW SOC CUTOFF" 9 "Module under temperature cutoff" 8 "Module Overtemperature cutoff" 7 "Battery_I_Over_Current_Fault" 6 "Battery Under Temperature cutoff" 5 "Battery Over Temperature cutoff" 4 "Battery Under voltage Cutoff" 3 "Battery Over voltage Cutoff" 2 "Cell_Under_Voltage _Cutoff" 1 " Cell_Over_Voltage _Cutoff" 0 "Reserved" ;
VAL_ 285 BMS_Reason_Derating 31 "CCLM DERATE  " 30 "TPS FAULT" 29 "LIN timeout Failure" 28 "BMScell vlt snsr fail cutoff BMU" 27 "Battery Disconnect Fail" 26 "BATTER PACK POWER LIMIT ERROR" 25 "Isolation_Fault_yellow" 24 " Isolation_Time_Out" 23 "Coolant sensor threshold fault" 22 "PUMP_OVERLOAD_PROTECTION" 21 "PUMP_UNDER_AND_OVER_VOLTAGE" 20 "PUMP_OVER_TEMP_SHUTDOWN" 19 "PUMP_OVER_TEMPERATURE_DERATED" 18 "PUMP_OVER_CURRENT_DERATED" 17 "COOLANT_OUTLET_LOW_TEMP" 16 "COOLANT_OUTLET_HIGH_TEMP" 15 "COOLANT_INLET_LOW_TEMP" 14 "COOLANT_INLET_HIGH_TEMP" 13 "BMS_CELL_WAER_DETECTION_FAULT" 12 "BMU OPEN WIRE FAULT" 11 "Module under temperature derate" 10 "Module Over temperature derate" 9 "MOD_TEMP_DIFF" 8 "MULTI_MOD_2_TEMP_FAULT" 7 "1_MOD_2_TEMP_FAULT" 6 "Battery Under Temp Derated" 5 "Battery Over Temperature derated" 4 "Battery Under voltage Derated" 3 "Battery Over voltage Derated" 2 "Cell Under Voltage Derate" 1 "Cell Over Voltage Derate" 0 "Reserved" ;
VAL_ 920 STS_HIGHBEAM_BOOSTER 1 "HIGHBEAM BOOSTER ON" 0 "HIGHBEAM BOOSTER OFF" ;
VAL_ 920 HEADLAMP_AUTO_LEVEL 1 "HL Auto level Enable" 0 "HL Auto level Disbabl/DV" ;
VAL_ 921 STS_HIGHBEAM_BOOSTER_1 1 "HIGHBEAM BOOSTER ON" 0 "HIGHBEAM BOOSTER OFF" ;
VAL_ 771 PASSIVE_VENT_FATC_STS 1 "Passive Ventilation Active" 0 "Passive Vent not active / DV" ;
VAL_ 771 DISP_AMBT_TEMP_FATC 0 "Default Value" 255 "Invalid value" ;
VAL_ 1711 FOD_ALERT 1 "Foreign Object Detected" 0 "No Foreign objct detctd/ Default" ;
VAL_ 1711 TIME_TO_CHARGE 255 "Signal Invalid" 252 "NFC Card Protection Alert" 251 "Low Vehicle Battery Alert" 250 "Mobile Device Placement Error" 249 "Negotiation Failure" 248 "Mobile Device Battery Failure" 247 "Mobile Device Over Voltage" 246 "Mobile Device Over Temperature" 245 "Mobile Device Internal Fault" 244 "Mobile Device Unkown Error" 243 "Over heat Shutdown" 242 "Forgotten Device" 241 "No Device / Default" 1 "Phone Charging" 0 "Full Charge" 2 "WLC OFF" ;
VAL_ 768 STS_IONIZER 1 "ON" 0 "OFF" ;
VAL_ 768 AC_SWT_STS 1 "ON" 0 "OFF / Default" ;
VAL_ 768 AUTO_RECIRC 1 "Enable" 0 "Disable/Default" ;
VAL_ 768 AUTO_DEFROST 1 "Enable" 0 "Disable/Default" ;
VAL_ 768 STS_REAR_AC 1 "ON" 0 "OFF / Default" ;
VAL_ 768 MEM_DISP 4 "Signal Invalid" 3 "'3'" 2 "'2'" 1 "'1'" 0 "Default Value / MEM LED OFF" ;
VAL_ 768 FRONT_LEFT_SET_TEMP 255 "Signal Invalid" 0 "Default Value" ;
VAL_ 768 FRESH_RECIRC 3 "Signal Invalid" 2 "Reserved" 1 "Recirculation" 0 "Fresh / Default" ;
VAL_ 768 FATC_ECON 3 "Signal Invalid" 2 "Not Used" 1 "ECON ON" 0 "ECON OFF/ Default" ;
VAL_ 768 FATC_AUTO 3 "Signal Invalid" 2 "Reserved" 1 "AUTO ON" 0 "AUTO OFF/Default" ;
VAL_ 768 FRONT_RIGHT_SET_TEMP 255 "Signal Invalid" 0 "Default value" ;
VAL_ 768 DISP_OFF 3 "Signal Invalid" 2 "FATC system OFF(Blower OFF)" 1 "ON" 0 "OFF / Default" ;
VAL_ 768 DISP_MODE 15 "Signal Invalid" 14 "Reserved" 13 "Reserved" 12 "Reserved" 11 "Reserved" 10 "Reserved" 9 "Reserved" 8 "Reserved" 7 "Reserved" 6 "Reserved" 5 "Def" 4 "Floor / Def" 3 "Floor" 2 "Vent / Floor" 1 "Vent" 0 "OFF / Default" ;
VAL_ 768 DISP_DUAL 3 "Signal Invalid" 2 "Not Used" 1 "Dual ON" 0 "Dual OFF/Single Zone / Default" ;
VAL_ 768 DISP_AC 3 "Signal Invalid" 2 "Not Used" 1 "AC ON" 0 "AC OFF / Default" ;
VAL_ 768 INCAR_TEMP 255 "Signal Invalid" 0 "Default Value" ;
VAL_ 768 DISP_BLOWER 15 "Signal Invalid" 14 "Reserved" 13 "Reserved" 12 "Reserved" 11 "Reserved" 10 "Reserved" 9 "8-Step" 8 "7-Step" 7 "6-Step" 6 "5-Step" 5 "4-Step" 4 "3-Step" 3 "2-Step" 2 "1-Step" 1 "0-Step" 0 "OFF/Default" ;
VAL_ 1588 GP_CLOSE_RES_AC 1 "OK" 0 "Not OK / Default" ;
VAL_ 1588 SET_TIRE_FILL_ASST_IC 1 "Enable/Default" 0 "Disable" ;
VAL_ 1588 TPMS_AUTOLEARN 1 "Enable/Default" 0 "Disable" ;
VAL_ 1588 GP_CLOSE_RES_RAIN 1 "OK" 0 "Not OK / Default" ;
VAL_ 1588 SET_VACATION_MODE_IC 1 "Enable" 0 "Disable/Default Value" ;
VAL_ 1586 SEAT_HEAT_VENT_LEVEL_SCM 3 "Level 3" 2 "Level 2" 1 "Level 1" 0 " Default" ;
VAL_ 1586 STS_HEATER 1 "Heater On" 0 "Heater Off / DV" ;
VAL_ 1586 SEAT_POSITION_FEEDBACK 7 "Reserved" 6 "Decline Operation" 5 "Recline Operation" 4 "Down Operation" 3 "UP Operation" 2 "Backward Operation" 1 "Forward Operation" 0 " Default Value" ;
VAL_ 1586 SCM_MEMORY_STS 3 "Reserved" 2 "Succeed" 1 "Failed" 0 "Default" ;
VAL_ 1586 SCM_MEMORY_MODE 7 "Reserved" 6 "Reserved" 5 "Memory Clear" 4 "Manual operation running" 3 "Easy Entry/Exit Running" 2 "Memory read/ Recall" 1 "Memory Write" 0 "Default" ;
VAL_ 1586 HEATER_TEMP 0 "Default Value" 255 "Invalid value" ;
VAL_ 1586 POWER_SEAT_MEMORY_STORE 3 "Position 3" 2 "Position 2" 1 "Position 1" 0 "Default Value" ;
VAL_ 1586 POWER_SEAT_MEMORY_RECALL 3 "Position 3" 2 "Position 2" 1 "Position 1" 0 "Default Value" ;
VAL_ 828 RLS_WINDOW_CLOSE_REQ 1 "Window Close Request" 0 "No Request / Default" ;
VAL_ 828 RLS_SOLAR_RIGHT 255 "Signal Invalid" 254 "Default" ;
VAL_ 828 RLS_SOLAR_LEFT 255 "Signal Invalid" 254 "Default" ;
VAL_ 828 RLS_IR_BRIGHTNESS 255 "Signal Invalid" 254 "Default" ;
VAL_ 828 RLS_FW_BRIGHTNESS 1023 "Signal Invalid" 1022 "Default" ;
VAL_ 828 RLS_AMB_BRIGHTNESS 1023 "Signal Invalid" 1022 "Default" ;
VAL_ 806 FPAS_ACTIVE_STS 1 "TRUE" 0 "FLASE / Default" ;
VAL_ 806 FPAS_SWT_STS 1 "ON" 0 "OFF/DEFAULT" ;
VAL_ 806 RPAS_ERROR 0 "Default value" ;
VAL_ 806 RPAS_DISP_DIST 255 "Signal Invalid" 254 "Default value or No Object" 253 "Reserved" 252 "Reserved" 251 "Reserved" ;
VAL_ 806 RPAS_ACTIVE_STS 1 "TRUE" 0 "FLASE / Default" ;
VAL_ 806 BAR_ZONE_RRC 15 "Bar Zone 15 ON" 14 "Bar Zone 14 ON" 13 "Bar Zone 13 ON" 12 "Bar Zone 12 ON" 11 "Bar Zone 11 ON" 10 "Bar Zone 10 ON" 9 "Bar Zone 9 ON" 8 "Bar Zone 8 ON" 7 "Bar Zone 7 ON" 6 "Bar Zone 6 ON" 5 "Bar Zone 5 ON" 4 "Bar Zone 4 ON" 3 "Bar Zone 3 ON" 2 "Bar Zone 2 ON" 1 "Bar Zone 1 ON" 0 "No warning/Default" ;
VAL_ 806 BAR_ZONE_RR 15 "Bar Zone 15 ON" 14 "Bar Zone 14 ON" 13 "Bar Zone 13 ON" 12 "Bar Zone 12 ON" 11 "Bar Zone 11 ON" 10 "Bar Zone 10 ON" 9 "Bar Zone 9 ON" 8 "Bar Zone 8 ON" 7 "Bar Zone 7 ON" 6 "Bar Zone 6 ON" 5 "Bar Zone 5 ON" 4 "Bar Zone 4 ON" 3 "Bar Zone 3 ON" 2 "Bar Zone 2 ON" 1 "Bar Zone 1 ON" 0 "No warning/Default" ;
VAL_ 806 BAR_ZONE_RLC 15 "Bar Zone 15 ON" 14 "Bar Zone 14 ON" 13 "Bar Zone 13 ON" 12 "Bar Zone 12 ON" 11 "Bar Zone 11 ON" 10 "Bar Zone 10 ON" 9 "Bar Zone 9 ON" 8 "Bar Zone 8 ON" 7 "Bar Zone 7 ON" 6 "Bar Zone 6 ON" 5 "Bar Zone 5 ON" 4 "Bar Zone 4 ON" 3 "Bar Zone 3 ON" 2 "Bar Zone 2 ON" 1 "Bar Zone 1 ON" 0 "No warning/Default" ;
VAL_ 806 BAR_ZONE_RL 15 "Bar Zone 15 ON" 14 "Bar Zone 14 ON" 13 "Bar Zone 13 ON" 12 "Bar Zone 12 ON" 11 "Bar Zone 11 ON" 10 "Bar Zone 10 ON" 9 "Bar Zone 9 ON" 8 "Bar Zone 8 ON" 7 "Bar Zone 7 ON" 6 "Bar Zone 6 ON" 5 "Bar Zone 5 ON" 4 "Bar Zone 4 ON" 3 "Bar Zone 3 ON" 2 "Bar Zone 2 ON" 1 "Bar Zone 1 ON" 0 "No warning/Default" ;
VAL_ 806 FPAS_DISP_DIST 255 "Signal Invalid" 254 "Default value or No Object" 253 "Reserved" 252 "Reserved" 251 "Reserved" ;
VAL_ 806 BAR_ZONE_FRC 15 "Bar Zone 15 ON" 14 "Bar Zone 14 ON" 13 "Bar Zone 13 ON" 12 "Bar Zone 12 ON" 11 "Bar Zone 11 ON" 10 "Bar Zone 10 ON" 9 "Bar Zone 9 ON" 8 "Bar Zone 8 ON" 7 "Bar Zone 7 ON" 6 "Bar Zone 6 ON" 5 "Bar Zone 5 ON" 4 "Bar Zone 4 ON" 3 "Bar Zone 3 ON" 2 "Bar Zone 2 ON" 1 "Bar Zone 1 ON" 0 "No warning/Default" ;
VAL_ 806 BAR_ZONE_FLC 15 "Bar Zone 15 ON" 14 "Bar Zone 14 ON" 13 "Bar Zone 13 ON" 12 "Bar Zone 12 ON" 11 "Bar Zone 11 ON" 10 "Bar Zone 10 ON" 9 "Bar Zone 9 ON" 8 "Bar Zone 8 ON" 7 "Bar Zone 7 ON" 6 "Bar Zone 6 ON" 5 "Bar Zone 5 ON" 4 "Bar Zone 4 ON" 3 "Bar Zone 3 ON" 2 "Bar Zone 2 ON" 1 "Bar Zone 1 ON" 0 "No warning/Default" ;
VAL_ 806 FPAS_ERROR 0 "Default value" ;
VAL_ 806 BAR_ZONE_FR 15 "Bar Zone 15 ON" 14 "Bar Zone 14 ON" 13 "Bar Zone 13 ON" 12 "Bar Zone 12 ON" 11 "Bar Zone 11 ON" 10 "Bar Zone 10 ON" 9 "Bar Zone 9 ON" 8 "Bar Zone 8 ON" 7 "Bar Zone 7 ON" 6 "Bar Zone 6 ON" 5 "Bar Zone 5 ON" 4 "Bar Zone 4 ON" 3 "Bar Zone 3 ON" 2 "Bar Zone 2 ON" 1 "Bar Zone 1 ON" 0 "No warning/Default" ;
VAL_ 806 BAR_ZONE_FL 15 "Bar Zone 15 ON" 14 "Bar Zone 14 ON" 13 "Bar Zone 13 ON" 12 "Bar Zone 12 ON" 11 "Bar Zone 11 ON" 10 "Bar Zone 10 ON" 9 "Bar Zone 9 ON" 8 "Bar Zone 8 ON" 7 "Bar Zone 7 ON" 6 "Bar Zone 6 ON" 5 "Bar Zone 5 ON" 4 "Bar Zone 4 ON" 3 "Bar Zone 3 ON" 2 "Bar Zone 2 ON" 1 "Bar Zone 1 ON" 0 "No warning/Default" ;
VAL_ 536 RR_TYRE_TEMP 255 "Signal invalid" 0 "Default Value" ;
VAL_ 536 RR_TYRE_PRESSURE 255 "Signal invalid" 0 "Default Value" ;
VAL_ 536 RL_TYRE_TEMP 255 "Signal invalid" 0 "Default Value" ;
VAL_ 536 RL_TYRE_PRESSURE 255 "Signal invalid" 0 "Default Value" ;
VAL_ 536 FR_TYRE_TEMP 255 "Signal invalid" 0 "Default Value" ;
VAL_ 536 FR_TYRE_PRESSURE 255 "Signal invalid" 0 "Default Value" ;
VAL_ 536 FL_TYRE_TEMP 255 "Signal invalid" 0 "Default Value" ;
VAL_ 536 FL_TYRE_PRESSURE 255 "Signal invalid" 0 "Default Value" ;
VAL_ 1056 CABIN_HVAC_STS_CCM 3 "Reserved" 2 "Cabin Heating ON" 1 "Cabin Cooling ON" 0 "OFF/Default" ;
VAL_ 1056 HEATER_INPUT_DC_VOLT 65535 "Signal Invalid" 0 "Default Value" ;
VAL_ 1056 CABIN_HEATER_POWER_CONSUMPTION 255 "Signal Invalid" 0 "Default Value" ;
VAL_ 1056 AC_OFF_CODE 6 "DISP_AC OFF/INVALID" 17 "Cabin Preheating is ON" 16 "Cabin Precooling became OFF" 15 "
Cabin Heating is ON" 14 "EVAP sig faulty/temp outofrange" 13 "Battery Over voltage" 11 "CRITICAL_HV_LOAD_CUTOFF=1" 10 "Battery Under voltage" 9 "NONCRITICAL_HV_LOAD_CUTOFF=1" 4 "Suction Pressure faulty" 3 "Discharge Pressure - Under prsr
" 2 "Blwr OFF/faulty/lvl outofrange" 1 "Discharge Pressure - Over prsr" 0 "AC preconditions OK." ;
VAL_ 1056 REMOTE_HVAC_STS_CCM 3 "Reserved" 2 "Remote Heating ON" 1 "Remote Cooling ON" 0 "OFF/Default" ;
VAL_ 1001 BMS_ChargeVoltageLimit 16383 "Signal Invalid" 3650 "Default value" ;
VAL_ 1001 BMS_ChargeCurrentLimit 16383 "Signal Invalid" 0 "Default value" ;
VAL_ 1001 BMS_DischargeCurrentlimit 16383 "Signal Invalid" 0 "Default value" ;
VAL_ 1168 REMOTE_HV_CONNECT_FB 3 "Reserved" 2 "HV Connected" 1 "HV Disconnected" 0 "Default" ;
VAL_ 1168 LIMIT_POWER_CCM 6 "Signal Invalid" 5 "Limti 6/Default" 4 "Limit 5" 3 "Limit 4" 2 "Limit 3" 1 "Limit 2" 0 "Limit 1" ;
VAL_ 1168 BATTERY_INLET_COOLANT_TEMP_REQ 2047 "Signal Invalid" 280 "Default Value" ;
VAL_ 1168 BATTERY_INLET_COOLANT_TEMP 2047 "Signal Invalid" 280 "Default value" ;
VAL_ 1168 NONCRITICAL_LV_LOAD_CUTOFF 1 "Cut off/Disable Load" 0 "Default/No Cutoff req/Enable" ;
VAL_ 1168 CRITICAL_LV_LOAD_CUTOFF 1 "Cut off/Disable Load" 0 "Default/No Cutoff req/Enable" ;
VAL_ 1168 NONCRITICAL_HV_LOAD_CUTOFF 1 "Cut off/Disable Load" 0 "Default/No Cutoff req/Enable" ;
VAL_ 1168 EPT_RADIATORFAN_SPEED_REQ 1 "NO SPEED REQUEST/DEFAULT" 2 "LOW SPEED ON" 3 "HIGH SPEED ON" ;
VAL_ 1168 STS_EPT_RADIATORFAN 3 "Signal Invalid" 2 "Reserved" 0 "RADIATOR FAN OFF/DEFAULT" 1 "RADIATOR FAN ON" ;
VAL_ 1168 BATT_COOLING_REQ 1 "Cooling ON request" 0 "No request/Default Value" ;
VAL_ 1168 BATT_COMPRES_SPD_REQ 65535 "Invalid Value" 0 "Default Value" ;
VAL_ 1168 CRITICAL_HV_LOAD_CUTOFF 1 "Cut off/Disable Load" 0 "Default/No Cutoff req/Enable" ;
VAL_ 743 REQUEST_RESPONSE_REVIVE 15 "Reserved" 14 "Reserved" 13 "Reserved" 12 "Reserved" 11 "Unsuccess - No of Attempts" 10 "Reserved" 9 "Reserved" 8 "Reserved" 7 "Unsuccess - Not in Neutral" 6 "Unsuccess - Drive Stop" 5 "Reserved" 4 "Unsuccess - Already Activated" 3 "Unsuccess - SOC" 2 "Unsucess - Immo Auth Fail" 1 "Busy" 0 "REVIVE SUCCESSFUL/DEFAULT VALUE" ;
VAL_ 743 MOTOR_PWR 32768 "Default Value" 65535 "Signal Invalid" ;
VAL_ 743 STS_REGEN 1 "Regeneration is active" 0 "No regeneration /Default" ;
VAL_ 743 RECUP_CTRL_STATE 3 "Reserved" 2 "Inhibit failed/Recup cant stop" 1 "Inhibit success/Recup Disabld" 0 "default value" ;
VAL_ 743 ACT_REGEN_TORQUE_APPLIED 2047 "Signal Invalid" 2046 "Default value" ;
VAL_ 743 ENERGY_EFFICIENCY 255 "Signal Invalid" 0 "Default Value" ;
VAL_ 743 BRAKE_PEDAL_VALUE 255 "Signal Invalid" 0 "Default" ;
VAL_ 743 POWER_REGEN_METER 100 "Default Value" 255 "Signal Invalid" ;
VAL_ 1416 WLC_ENABLE_SETTING_IS 1 "Disable" 0 "Default / Enable" ;
VAL_ 1416 IRVM_AUTO_DIMMING_IS 1 "Disable" 0 "Enable / Default" ;
VAL_ 1416 SUNROOF_WINDOW_OPEN_IS 1 "Enable" 0 "Disable / Default" ;
VAL_ 1416 POWER_SEAT_RECALL_IS 3 "Restore Position 3" 2 "Restore Position 2" 1 "Restore Position 1" 0 "Default Value" ;
VAL_ 1416 SET_AUTO_BRAKE_LAMP_IS 1 "enable" 0 "default value/disable" ;
VAL_ 1416 DYNAMIC_TRAJ_LINES_RPAS 1 "OFF" 0 "ON/Default Value" ;
VAL_ 1416 DYNAMIC_TRAJ_LINE_FPAS_APA 1 "OFF" 0 "ON/Default Value" ;
VAL_ 1416 AUTO_TOPVIEW_ON_PAS_FRONT 1 "Disable" 0 "Default Value/Enable" ;
VAL_ 1416 RVC_TTS 1 "Mute" 0 "Unmute/Default Value" ;
VAL_ 1416 SET_PARKBRAKE_AUTO_ACT_IS 1 "ON" 0 "Default Value/Off" ;
VAL_ 1416 AVM_CONTROL_IS 1 "ON" 0 "OFF" ;
VAL_ 1416 FOGLAMP_CONTROL_IS 3 "Reserved" 2 "OFF" 1 "ON" 0 "Default Value/No Request" ;
VAL_ 1416 AUTO_TOPVIEW_ON_PAS_REAR 1 "Disable" 0 "Default Value/Enable" ;
VAL_ 1416 SET_SERVICE_MODE_IS 1 "Disable" 0 "Default Value/Enable" ;
VAL_ 1416 STS_PROFILE_LOCK_IS 1 "enable" 0 "Default/disable" ;
VAL_ 1416 SET_SMART_ENERGY_IS 1 "Enable" 0 "Disable/DV" ;
VAL_ 1416 HEADLAMP_CONTROL_IS 3 "Reserved" 2 "OFF" 1 "ON" 0 "Default Value/No Request" ;
VAL_ 1416 AMBIENT_LIGHT_CONTROL_IS 3 "Reserved" 2 "ON" 1 "Off" 0 "Default Value" ;
VAL_ 1416 SUNROOF_CONTROL_IS 3 "Reserved" 2 "Sunroof Close" 1 "Sunroof Open" 0 "Default Value" ;
VAL_ 1416 PWR_WINDOW_CONTROL_IS 3 "Reserved" 2 "Power Window Open" 1 "Power Window Close" 0 "Default Value" ;
VAL_ 1416 DOOR_LOCK_CONTROL_IS 3 "Reserved" 2 "Reserved" 1 "Lock" 0 "Default Value/No Request" ;
VAL_ 1416 SET_REMOTE_ENG_STARTSTOP 1 "Disable" 0 "Defaul Value/Enable" ;
VAL_ 1416 SET_WALK_AWAY_LCK_IS 1 "Enable" 0 "Disable/Default Value" ;
VAL_ 1416 SET_APPROACH_UNLCK_IS 1 "Disable" 0 "Enable/Default Value" ;
VAL_ 1408 STS_EPB 1 "Available" 0 "Not Available / Default" ;
VAL_ 1408 AVH_FUNCTION_STS 1 "Available" 0 "Not Available / Default" ;
VAL_ 1408 AVH_ACTIVE_STS 3 "Invalid" 2 "Released" 1 "Applied" 0 "Stand-By / Default" ;
VAL_ 1408 EPB_ALERT 7 "Reserved" 6 "Reserved" 5 "drvdoor close & seat belt fasted" 4 "EPB Automatically Released" 3 "EPB Automatically locked" 2 "Shift to N or P" 1 "Press Brake" 0 "No Alert / Default" ;
VAL_ 1408 PARK_BRK_ACTIVE_STS 3 "Invalid Status" 2 "In-Progress" 1 "Released " 0 "Applied / Default" ;
VAL_ 1408 RR_PARK_BRK_ACTIVE_STS 3 "Invalid Status" 2 "In-Progress" 1 "Released " 0 "Applied / Default" ;
VAL_ 1408 RL_PARK_BRK_ACTIVE_STS 3 "Invalid Status" 2 "In-Progress" 1 "Released " 0 "Applied / Default" ;
VAL_ 977 POT_HOLE_SPD_BRK_ALERT 3 "Reserved" 2 "Speed Brake" 1 "Pothole" 0 "No Alert / Default" ;
VAL_ 977 CABIN_HVAC_REQ 3 "Reserved" 2 "CABIN HVAC REQUEST" 1 "Reserved" 0 "NO REQUEST/ DEFAULT" ;
VAL_ 977 OVER_SPD_MCM 1 "over speed Alert" 0 "No Alert / Default" ;
VAL_ 977 REQ_REAR_DEFOG_MCM 3 "Signal invalid" 2 " Default value" 1 "ON" 0 "OFF" ;
VAL_ 977 SET_TEMP_MCM 254 "Default value" 255 "Signal invalid" ;
VAL_ 977 AIR_PURIFIER_AUTO_MCM 1 "On Request" 0 "Default Value/OFF" ;
VAL_ 977 MCMTRG_R 1 "Invalid/Default Value" 0 "Valid" ;
VAL_ 977 REMOTE_VEH_IMMOB_MCM 3 "Reserve" 2 "Remote Veh Immobilization Rel" 1 "Remote Veh Immobilization Req" 0 "No Action" ;
VAL_ 977 DISP_MODE_MCM 3 "Signal invalid" 2 "Default Value" 1 "Front Defrost ON request" 0 "Front Defrost OFF request" ;
VAL_ 532 VEH_THEFT_STS 1 "Theft" 0 "Not Theft /Default" ;
VAL_ 532 STS_DRL 1 "DRL ON" 0 "DRL OFF / Default" ;
VAL_ 532 TPMS_SYSTEM_FAULT 0 "Default value" ;
VAL_ 532 TPMS_SIGNAL_MISSING 0 "Default value" ;
VAL_ 532 TPMS_PROG_MODE 15 "signal invalid" 8 "Learning not completed" 7 "All tyre learning completed" 6 "Spare tyre Learned" 5 "Learning Spare tyre" 4 "Learning RL tyre" 3 "Learning RR tyre" 2 "Learning FR tyre" 1 "Learning FL Tyre" 0 "Normal mode / default" ;
VAL_ 532 TPMS_LEAKAGE_ALERT 0 "Default value" ;
VAL_ 532 TPMS_ID_NOT_LEARNT 31 "All tyre ssor nt learn" 30 "(FR+RR+RL+spare) tyre ssor nt le" 29 "(FL+RR+RL+spare) tyre ssor nt le" 28 "(RR+RL+spare) tyre ssor nt learn" 27 "(FL+FR+RL+spare) tyre ssor nt le" 26 "(FR+RL+spare) tyre ssor nt learn" 25 "(FL+RL+spare) tyre ssor nt learn" 24 "(RL+spare) tyre sensor not learn" 23 "(FL+FR+RR+Spare) tyre ssor nt le" 22 "(FR+RR+Spare) tyre sensor not le" 21 "(FL+RR+Spare) tyre snsor not lea" 20 "(RR+Spare) tyre sensor not lea" 19 "(FL+FR+Spare) tyre snsor not lea" 18 "(FR+Spare) tyre sensor not learn" 17 "(FL+Spare) tyre sensor not learn" 16 "Spare tyre sensor not learned" 15 "(FL+FR+RR +RL)tyre snsor not lea" 14 "(FR+RR +RL)tyre sensor not lea" 13 "(FL+RR +RL)tyre sensor not lea" 12 "(RR +RL)tyre sensor not learned" 11 "(FL+FR +RL)tyre sensor not lea" 10 "(FR +RL)tyre sensor not learned" 9 "(FL +RL)tyre sensor not learned" 8 "RL tyre sensor not learned" 7 "(FL+FR +RR)tyre sensor not le" 6 "(FR +RR)tyre sensor not learned" 5 "(FL +RR)tyre sensor not learned" 4 "RR tyre sensor not learned" 3 "(FL +FR)tyre sensor not learned" 2 "FR tyre sensor not learned" 1 "FL tyre sensor not learned" 0 "All sensor learned / Default" ;
VAL_ 532 STS_TPMS_LED 7 "Reserved" 6 "Reserved" 5 "Reserved" 4 "Reserved" 3 "Continously ON" 2 "Blinking pattern 2" 1 "Blinking pattern 1" 0 "OFF / Default value" ;
VAL_ 532 SPARE_TYRE_SWAP 7 "Signal Invalid" 4 "RL tyre swapped" 3 "RR tyre swapped" 2 "FR tyre swapped" 1 "FL tyre swapped" 0 "No spare tyre swap / default " ;
VAL_ 532 REQ_TFA_PATTERN 5 "Pattern 5" 4 "Pattern 4" 3 "Pattern 3" 2 "Pattern 2" 1 "Pattern 1" 0 "Default" ;
VAL_ 532 REQ_TFA_DISPLAY 1 "TFA display request" 0 "No Request / Default" ;
VAL_ 532 LOW_TYRE_PRESSURE 31 "All tyre low pressure" 30 "(FR+RR+RL+spare) tyre low press" 29 "(FL+RR+RL+spare) tyre low press" 28 "(RR+RL+spare) tyre low pressure" 27 "(FL+FR+RL+spare) tyre low press" 26 "(FR+RL+spare) tyre low pressure" 25 "(FL+RL+spare) tyre low pressure" 24 "(RL+spare) tyre low pressure" 23 "(FL+FR+RR+Spare) tyre low press" 22 "(FR+RR+Spare) tyre low press" 21 "(FL+RR+Spare) tyre low pressure" 20 "(RR+Spare) tyre low pressure" 19 "(FL+FR+Spare) tyre low pressure" 18 "(FR+Spare) tyre low pressure" 17 "(FL+Spare) tyre low pressure" 16 "Spare tyre low pressure" 15 "(FL+FR+RR +RL)tyre low pressure" 14 "(FR+RR +RL)tyre low pressure" 13 "(FL+RR +RL)tyre low pressure" 12 "(RR +RL)tyre low pressure" 11 "(FL+FR +RL)tyre low pressure" 10 "(FR +RL)tyre low pressure" 9 "(FL +RL)tyre low pressure" 8 "RL tyre low pressure" 7 "(FL+FR +RR)tyre low pressure" 6 "(FR +RR)tyre low pressure" 5 "(FL +RR)tyre low pressure" 4 "RR tyre low pressure" 3 "(FL +FR)tyre low pressure" 2 "FR tyre low pressure" 1 "FL tyre low pressure" 0 "All tyre normal / Default value" ;
VAL_ 532 HIGH_TYRE_TEMPERATURE 31 "All tyre high  temp" 30 "(FR+RR+RL+spare) tyre high  temp" 29 "(FL+RR+RL+spare) tyre high  temp" 28 "(RR+RL+spare) tyre high  temp" 27 "(FL+FR+RL+spare) tyre high  temp" 26 "(FR+RL+spare) tyre high  temp" 25 "(FL+RL+spare) tyre high  temp" 24 "(RL+spare) tyre high  temp" 23 "(FL+FR+RR+Spare) tyre high  temp" 22 "(FR+RR+Spare) tyre high  temp" 21 "(FL+RR+Spare) tyre high  temp" 20 "(RR+Spare) tyre high  temp" 19 "(FL+FR+Spare) tyre high  temp" 18 "(FR+Spare) tyre high  temp" 17 "(FL+Spare) tyre high  temp" 16 "Spare tyre high  temp" 15 "(FL+FR+RR +RL)tyre high  temp" 14 "(FR+RR +RL)tyre high  temp" 13 "(FL+RR +RL)tyre high  temp" 12 "(RR +RL)tyre high  temp" 11 "(FL+FR +RL)tyre high  temp" 10 "(FR +RL)tyre high  temp" 9 "(FL +RL)tyre high  temp" 8 "RL tyre high  temp" 7 "(FL+FR +RR)tyre high  temp" 6 "(FR +RR)tyre high  temp" 5 "(FL +RR)tyre high  temp" 4 "RR tyre high  temp" 3 "(FL +FR)tyre high  temp" 2 "FR tyre high temp" 1 "FL tyre high temp" 0 "All tyre normal / Default value" ;
VAL_ 532 HIGH_TYRE_PRESSURE 31 "All tyre high pressure" 30 "(FR+RR+RL+spare) tyre high press" 29 "(FL+RR+RL+spare) tyre high press" 28 "(RR+RL+spare) tyre high pressure" 27 "(FL+FR+RL+spare) tyre high press" 26 "(FR+RL+spare) tyre high pressure" 25 "(FL+RL+spare) tyre high pressure" 24 "(RL+spare) tyre high pressure" 23 "(FL+FR+RR+Spare) tyre high press" 22 "(FR+RR+Spare) tyre high press" 21 "(FL+RR+Spare) tyre high pressure" 20 "(RR+Spare) tyre high pressure" 19 "(FL+FR+Spare) tyre high pressure" 18 "(FR+Spare) tyre high pressure" 17 "(FL+Spare) tyre high pressure" 16 "Spare tyre high pressure" 15 "(FL+FR+RR +RL)tyre high pressure" 14 "(FR+RR +RL)tyre high pressure" 13 "(FL+RR +RL)tyre high pressure" 12 "(RR +RL)tyre high pressure" 11 "(FL+FR +RL)tyre high pressure" 10 "(FR +RL)tyre high pressure" 9 "(FL +RL)tyre high pressure" 8 "RL tyre high pressure" 7 "(FL+FR +RR)tyre high pressure" 6 "(FR +RR)tyre high pressure" 5 "(FL +RR)tyre high pressure" 4 "RR tyre high pressure" 3 "(FL +FR)tyre high pressure" 2 "FR tyre high pressure" 1 "FL tyre high pressure" 0 "All tyre normal / Default value" ;
VAL_ 532 STS_DOOR_LATCH 3 "Signal Invalid" 2 "Reserved" 1 "Locked" 0 "Unlocked" ;
VAL_ 843 ESCL_STEER_WHL_JAM_WRN 1 "steering column not jammed" 0 "steering column jammed" ;
VAL_ 843 ESCL_WRN_SFTY 1 "Failure Detected" 0 "No Failure" ;
VAL_ 843 ESCL_WRN_FUNC 1 "Failure Detected" 0 "No Failure" ;
VAL_ 843 ESCL_NOT_LEARNED_WRN 1 "ESCL Not Learned" 0 "ESCL Learned" ;
VAL_ 843 ESCL_NOT_LOCK_WRN 1 " Active" 0 "not Active" ;
VAL_ 151 MBFM_WAKEUP_REASON 20 "Wakeup due to RLS" 19 "Wakeup due to TPMS air leakage " 18 "Park Mode AT Changes" 17 "FMH Status Change" 16 "WakeUp due to MCM" 15 "Hood Status Change" 14 "Hazazrd status Change" 13 "Illumination Ring Status Change" 12 "Passive Ventilation Request" 11 "Vacation Mode Change" 10 "Park Lamp Input status changed" 9 "ACC Status Change" 8 "Wakeup due to RKE" 7 "Reserved" 6 "CDL Door Status Changed" 5 "Arm Door Status Changed" 4 "Tailgate Door Status Changed" 3 "RL Door Status Changed" 2 "RR Door Status Changed" 1 "Co-DRV Door Status Changed" 0 "DRV Door Status Changed" ;
VAL_ 869 SIG2_MATCH_STS 1 "SIG2 match failed" 0 "SIG2 match passed" ;
VAL_ 869 PREVIOUS_CYL_AUTH_STS 1 "Authentication Fail" 0 "Authentication Pass" ;
VAL_ 869 RESPONSE_STS 1 "Response not Recieved" 0 "Response Recieved" ;
VAL_ 869 MCM_PACK 1 "Recieved" 0 "Other" ;
VAL_ 869 MCM_NACK 1 "Received" 0 "Other" ;
VAL_ 869 PKE_CHALLENGE_STS 0 "PKE Challenge Sent" 1 "PKE Challenge Not Sent" ;
VAL_ 869 PKE_NACK 1 "Transmitted" 0 "Other" ;
VAL_ 869 PKE_PACK 1 "Transmitted" 0 "Other" ;
VAL_ 869 MCMTRG_RECEIVE_STS 1 "MCMTRG not received" 0 "MCMTRG recieved" ;
VAL_ 869 REMOTE_ENG_START_STATE 3 "Reserved" 2 "Remote Engine Stop" 1 "Remote Engine Start request" 0 "Default" ;
VAL_ 869 REMOTE_VEH_IMMO_STS 1 "Remote Vehicle Immobilization" 0 "Remote Vehicle Release" ;
VAL_ 869 SIG1_MATCH 1 "Match failed" 0 "Match passed" ;
VAL_ 851 LAST_KEYFOB_NUM 7 "Reserved" 6 "Keyline-6" 5 "Keyline-5" 4 "Keyline-4" 3 "Keyline-3" 2 "Keyline-2" 1 "Keyline-1" 0 "Default" ;
VAL_ 851 KEYFOB_INSIDE_STATUS 1 "Keyfob Inside" 0 "Keyfob Not Inside" ;
VAL_ 1088 REMOTE_START_FAILURE_CODE 15 "Reserved" 14 "Electric Park brake not applied" 13 "PKE MCM Auth Failed" 12 "Gear position not in Park HW AT" 11 "Gear position not in Park CAN AT" 10 "Gear position not Neutral - MT" 9 "Vehicle not in Stand still" 8 "PKE EMS Auth Failed" 7 "Door Latch Unlock" 6 "Door Open" 5 "Valid Key fob Detected inside" 4 "MaxCounter elpsd Normal IGNcyc" 3 "Low Fuel Level" 2 "RES Function is Disable in PKE" 1 "Battery Voltage Low " 0 "Default Value" ;
VAL_ 1088 REMOTE_START_SOURCE 2 "MCM" 1 "KEY FOB" 0 "DV/No Remote start request" ;
VAL_ 1088 REMOTE_ENGINE_START_WARNING 1 "ON" 0 "OFF" ;
VAL_ 1088 STS_CAPASENSOR 3 "RESERVED" 2 "CAPA SENSOR BLOCKAGE ICE/ MUD" 1 "CAPA SENSOR FAIL" 0 "CAPA SENSOR OK/ DV" ;
VAL_ 1088 CAR_START_WARNING 1 "ON" 0 "OFF" ;
VAL_ 1088 KEY_FOB_INSD_WRN 1 "on" 0 "off" ;
VAL_ 1088 PKE_SHIFT_TO_PARK 1 "ON" 0 "OFF" ;
VAL_ 1088 PKE_PN_OFF_WARNING 1 "ON" 0 "OFF" ;
VAL_ 1088 EMRGNCY_CRANK_WRN 1 "ON" 0 "OFF" ;
VAL_ 1088 TERMINAL_NOT_OFF_WRN_CMD 1 "ON" 0 "OFF" ;
VAL_ 1088 DOOR_LOCK_WRN 1 "ON" 0 "OFF" ;
VAL_ 1088 FOB_AUTH_FAIL_WRN 1 "command" 0 "no command" ;
VAL_ 1088 SSB_FAIL_WRN 1 "ON" 0 "OFF" ;
VAL_ 1088 KEY_NOT_VEH_WRN 1 "Activation" 0 "No_Activation" ;
VAL_ 1088 FOB_BATT_DISCHG_WRN 1 "ON" 0 "OFF" ;
VAL_ 834 STS_RES_MCM 1 "Engine running RES MCM" 0 "DV/Engine not runing RES MCM" ;
VAL_ 834 RES_FAILURE_MCM 1 "Remote Start/Stop Failed" 0 "Default Value/No Failure" ;
VAL_ 834 REMOTE_START_TIME_EXTENSION 15 "Reserved" 14 "Reserved" 13 "Reserved" 12 "Reserved" 11 "Reserved" 10 "10th Extension" 9 "9th Extension" 8 "8th Extension" 7 "7th Extension" 6 "6th Extension" 5 "5th Extension" 4 "4th Extension" 3 "3rd Extension" 2 "2nd Extension" 1 "1St Extension" 0 "No Extension / Default" ;
VAL_ 834 REMOTE_ENGINE_STATE 3 "Remote Engine Stop" 2 "Speed Limit Applied" 1 "Speed Limit not Applied" 0 "Default" ;
VAL_ 834 STS_SECURITY_KEY 3 "Reserved" 2 "In progress" 1 "Failed" 0 "Passed" ;
VAL_ 834 P_IMMTRG_STATE 3 "Reserved" 2 "Reserved" 1 "Stop Primary Authen process" 0 "Start Primary Authen process" ;
VAL_ 150 PKE_WAKEUP_REASON 4 "Power ON" 3 "CAN Wake-up" 2 "RF Frame" 1 "DHS Press" 0 "SSB Press" ;
VAL_ 587 ACC_SET_DIST 7 "Reserved" 6 "Reserved" 5 "Reserved" 4 "Level-4" 3 "Level-3" 2 "Level-2" 1 "Level-1" 0 "Default" ;
VAL_ 587 ACC_VEH_SET_SPD 255 "Signal Invalid" 0 "Default" ;
VAL_ 587 ACC_MODE 3 "Shutoff" 2 "Override" 1 "Enguaged" 0 " OFF/StandBy / Default" ;
VAL_ 928 FPAS_SPAS_ACTIVE_STS 1 "TRUE" 0 "FLASE / Default" ;
VAL_ 928 FR_SEGMENT 15 "Sensor error" 14 "Reserved" 13 "Reserved" 12 "Reserved" 11 "Reserved" 10 "Reserved" 9 "Reserved" 8 "Reserved" 7 "Reserved" 6 "Display 6 Segment" 5 "Display 5 Segment" 4 "Display 4 Segment" 3 "Display 3 Segment" 2 "Display 2 Segment" 1 "Display 1 Segment" 0 "Default / No Display Segment" ;
VAL_ 928 RL_SEG_WARN 1 "Warning" 0 "No Warning/Default" ;
VAL_ 928 RPAS_ACTIVE_STS1 1 "TRUE" 0 "FLASE / Default" ;
VAL_ 928 RL_SEGMENT 15 "Sensor error" 14 "Reserved" 13 "Reserved" 12 "Reserved" 11 "Reserved" 10 "Reserved" 9 "Reserved" 8 "Reserved" 7 "Reserved" 6 "Display 6 Segment" 5 "Display 5 Segment" 4 "Display 4 Segment" 3 "Display 3 Segment" 2 "Display 2 Segment" 1 "Display 1 Segment" 0 "Default / No Display Segment" ;
VAL_ 928 FR_SEG_WARN 1 "Warning" 0 "No Warning/Default" ;
VAL_ 928 FMR_SEG_WARN 1 "Warning" 0 "No Warning/Default" ;
VAL_ 928 FML_SEG_WARN 1 "Warning" 0 "No Warning/Default" ;
VAL_ 928 FL_SEG_WARN 1 "Warning" 0 "No Warning/Default" ;
VAL_ 928 FMR_SEGMENT 15 "Sensor error" 14 "Reserved" 13 "Reserved" 12 "Reserved" 11 "Reserved" 10 "Reserved" 9 "Reserved" 8 "Display 8 Segment" 7 "Display 7 Segment" 6 "Display 6 Segment" 5 "Display 5 Segment" 4 "Display 4 Segment" 3 "Display 3 Segment" 2 "Display 2 Segment" 1 "Display 1 Segment" 0 "Default / No Display Segment" ;
VAL_ 928 FML_SEGMENT 15 "Sensor error" 14 "Reserved" 13 "Reserved" 12 "Reserved" 11 "Reserved" 10 "Reserved" 9 "Reserved" 8 "Display 8 Segment" 7 "Display 7 Segment" 6 "Display 6 Segment" 5 "Display 5 Segment" 4 "Display 4 Segment" 3 "Display 3 Segment" 2 "Display 2 Segment" 1 "Display 1 Segment" 0 "Default / No Display Segment" ;
VAL_ 928 FL_SEGMENT 15 "Sensor error" 14 "Reserved" 13 "Reserved" 12 "Reserved" 11 "Reserved" 10 "Reserved" 9 "Reserved" 8 "Reserved" 7 "Reserved" 6 "Display 6 Segment" 5 "Display 5 Segment" 4 "Display 4 Segment" 3 "Display 3 Segment" 2 "Display 2 Segment" 1 "Display 1 Segment" 0 "Default / No Display Segment" ;
VAL_ 928 RR_SEG_WARN 1 "Warning" 0 "No Warning/Default" ;
VAL_ 928 RMR_SEG_WARN 1 "Warning" 0 "No Warning/Default" ;
VAL_ 928 RML_SEG_WARN 1 "Warning" 0 "No Warning/Default" ;
VAL_ 928 REAR_MIN_DIST 251 "Reserved (0xFB to 0xFE)" 255 "Default value" 0 "Valid dist (0x0  to 0xFA)" ;
VAL_ 928 RR_SEGMENT 15 "Sensor error" 14 "Reserved" 13 "Reserved" 12 "Reserved" 11 "Reserved" 10 "Reserved" 9 "Reserved" 8 "Reserved" 7 "Reserved" 6 "Display 6 Segment" 5 "Display 5 Segment" 4 "Display 4 Segment" 3 "Display 3 Segment" 2 "Display 2 Segment" 1 "Display 1 Segment" 0 "Default / No Display Segment" ;
VAL_ 928 RMR_SEGMENT 15 "Sensor error" 14 "Reserved" 13 "Reserved" 12 "Reserved" 11 "Reserved" 10 "Display 10 Segment" 9 "Display 9 Segment" 8 "Display 8 Segment" 7 "Display 7 Segment" 6 "Display 6 Segment" 5 "Display 5 Segment" 4 "Display 4 Segment" 3 "Display 3 Segment" 2 "Display 2 Segment" 1 "Display 1 Segment" 0 "Default / No Display Segment" ;
VAL_ 928 RML_SEGMENT 15 "Sensor error" 14 "Reserved" 13 "Reserved" 12 "Reserved" 11 "Reserved" 10 "Display 10 Segment" 9 "Display 9 Segment" 8 "Display 8 Segment" 7 "Display 7 Segment" 6 "Display 6 Segment" 5 "Display 5 Segment" 4 "Display 4 Segment" 3 "Display 3 Segment" 2 "Display 2 Segment" 1 "Display 1 Segment" 0 "Default / No Display Segment" ;
VAL_ 928 FRONT_MIN_DIST 251 "Reserved (0xFB to 0x FE)" 255 "Default Value" 0 "Valid Dist (0x0 to 0xFA)" ;
VAL_ 588 ACC_OBJ_CLASSIFICATION_FRM 15 "Reserved" 14 "Reserved" 13 "Reserved" 12 "Reserved" 11 "Reserved" 10 "Reserved" 9 "Reserved" 8 "Unknown" 7 "Undecided" 6 "General Object (Falling obj)" 5 "Pedestrian" 4 "Bicycle" 3 "Motor Bike" 2 "Car" 1 "Truck" 0 "No Object / Default" ;
VAL_ 588 AEB_OBJ_CLASSIFICATION_FRM 15 "Reserved" 14 "Reserved" 13 "Reserved" 12 "Reserved" 11 "Reserved" 10 "Reserved" 9 "Reserved" 8 "Unknown" 7 "Undecided" 6 "General Object (Falling obj)" 5 "Pedestrian" 4 "Bicycle" 3 "Motor Bike" 2 "Car" 1 "Truck" 0 "No Object / Default" ;
VAL_ 588 ACC_SYS_INFO 15 "Reserved" 14 "Reserved" 13 "Manual park brake Enguage" 12 "Set SPD Higher then MAX" 11 "ESC turned OFF" 10 "OFF Road Mode-ACC not available" 9 "Driver Door Open" 8 "Seat Belt not Buckkled" 7 "TakeOver Request" 6 "Not a Condition to enter ACC" 5 "ACC Disengaged" 4 "Available to Resume Accel ctr" 3 "Object Disappeared" 2 "Enable AEB function to engag ACC" 1 "INCREASE SPEED ABOVE 10kmph" 0 "Default" ;
VAL_ 588 ACC_DRIVE_MODE 3 "Fast" 2 "Normal" 1 "Slow" 0 "Default" ;
VAL_ 588 ACC_TGT_VALIDITY 1 "Valid" 0 "Not Valid / Default" ;
VAL_ 588 STS_FRM 3 "Failure" 2 "Blockage" 1 "Normal" 0 "Not Applied / Default" ;
VAL_ 588 ACC_SYS_FAILURE 3 "Permanent Failure" 2 "Temperary Not Available" 1 "Degraded Performance " 0 "No Failure / Default" ;
VAL_ 588 ACC_SYS_STATE 7 "Reserved" 6 "Reserved" 5 "Shut OFF" 4 "CC Active State" 3 "CC StandBy State" 2 "ACC Active State" 1 "ACC StandBy State" 0 "OFF State / Default" ;
VAL_ 588 AEB_WARN_SET_STA_FRM 7 "Signal Invalid" 6 "Reserved" 5 "Reserved" 4 "Reserved" 3 "Early" 2 "Normal" 1 "Late" 0 "Not Applied / Default" ;
VAL_ 588 AEB_ON_OFF_STA_FRM 3 "Signal Invalid" 2 "ON(AEB) / Default" 1 "ON(FCW)" 0 "OFF" ;
VAL_ 588 AEB_WRN_FRM 3 "3rd Warning" 2 "2nd Warning" 1 "1st Warning" 0 "No Warning / Default" ;
VAL_ 588 AEB_FAIL_INFO_FRM 3 "Service Required" 2 "Temp. Not Available By Radar" 1 "Temp. Not Available By Camera" 0 "Normal State / Default" ;
VAL_ 588 AEB_ZONE_STS_FRM 7 "Reserved" 6 "Reserved" 5 "Reserved" 4 "Stop Request" 3 "Full Brake Active" 2 "Partial Brake Active" 1 "Prefill Active" 0 "Not Active / Default" ;
VAL_ 826 INDC_ROLL 127 "Signal Invalid" 0 "Default" ;
VAL_ 826 ESC_ADV_MOD_REQ 7 "Signal Invalid" 6 "Reserved" 5 "Reserved" 4 "Reserved" 3 "Normal/ Default value" 2 "Sport Mode" 1 "City/Comfort" 0 "Reserved" ;
VAL_ 826 DROWSINESS_INDEX 15 "Reserved" 14 "Reserved" 13 "Reserved" 12 "Reserved" 11 "Reserved" 10 "Reserved" 9 "Extreamly Slpy, can't stay Awake" 8 "Very Slpy, hi effort stay Awake" 7 "Sleepy with effort to stay Awake" 6 "Sleepy w/o effort to stay Awake" 5 "Slightly Sleepy" 4 "Neither Awake Nor Sleepy" 3 "Quite Awake" 2 "Awake" 1 "Very Awake" 0 "Default" ;
VAL_ 826 ADV_MODE_ALERT 3 "Reduce Vehicle Speed" 2 "Terrain Mode Inhibited" 1 "Shift to 4WH" 0 "No Alert/Default" ;
VAL_ 826 STS_TVB 1 "Available" 0 "Not Available" ;
VAL_ 826 INDC_PITCH 127 "Signal Invalid" 0 "Default" ;
VAL_ 826 STS_DDD 3 "Malfunction" 2 "Reserved" 1 "Active" 0 "Not Active/DV" ;
VAL_ 826 STS_ESC_DRV_ADV_MODE 3 "Ready to enter" 2 "In Progress" 1 "Mode active/Default" 0 "Not active" ;
VAL_ 829 STS_ELOCKER_MALFUNCTION_LED 1 "ON" 0 "OFF/ Default value" ;
VAL_ 829 STS_ELOCKER_ACTIVATION_LED 3 "RESERVED" 2 "BLINK" 1 "ON" 0 "OFF/ Default value" ;
VAL_ 310 SHIFTING 1 "Active" 0 "Inactive / Default value" ;
VAL_ 310 GEAR_TARGET 15 "Signal invalid" 14 "Reserved" 13 "Reserved" 12 "Reserved" 11 "Reserved" 10 "Reverse Gear" 9 "Reserved" 8 "Reserved" 7 "Reserved" 6 "6th" 5 "5th" 4 "4th" 3 "3rd" 2 "2nd" 1 "1st" 0 "Neutral / Default value" ;
VAL_ 310 GEAR_ACTUAL 15 "Signal invalid" 14 "Reserved" 13 "Reserved" 12 "Reserved" 11 "Reserved" 10 "Reverse Gear" 9 "Reserved" 8 "Reserved" 7 "Reserved" 6 "6th" 5 "5th" 4 "4th" 3 "3rd" 2 "2nd" 1 "1st" 0 "Neutral / Default value" ;
VAL_ 643 IGN_STS 1 "IGN ON" 0 "IGN OFF/Default" ;
VAL_ 643 BATT_VOLTAGE 0 "Default" ;
VAL_ 322 DRIVER_DEMAND_TRQ_EMS36 2047 "Signal Invalid" 0 "Default" ;
VAL_ 322 ENG_TRQ_AFTR_RED1 2047 "Signal Invalid" 0 "Default Value" ;
VAL_ 322 ACC_PED1 255 "Signal Invalid" 0 "Default" ;
VAL_ 322 ENG_SPD1 65535 "Signal Invalid" 0 "Default" ;
VAL_ 322 CURRENT_GEAR_MT 15 "Signal Invalid" 14 "Reserved" 13 "Reserved" 12 "Reserved" 11 "Reserved" 10 "reserved" 9 "Reserved" 8 "Reserved" 7 "Reverse" 6 "Sixth" 5 "Fifth" 4 "Fourth" 3 "Third" 2 "Second" 1 "First" 0 "Neutral/Default" ;
VAL_ 642 ODO_DISTANCE_ESC12 65535 "Signal Invalid" 0 "Default value" ;
VAL_ 642 VEHICLE_SPEED_ESC12 65535 "Signal Invalid" 65534 "Default Value" ;
VAL_ 543 FR_SEAT_HEAT_VENT_LEVEL_MBFM 3 "Level 3" 2 "Level 2" 1 "Level 1" 0 " Default" ;
VAL_ 543 FL_SEAT_HEAT_VENT_LEVEL_MBFM 3 "Level 3" 2 "Level 2" 1 "Level 1" 0 " Default" ;
VAL_ 543 STS_EHORN_FAIL 1 "Horn failed" 0 "Default/OK" ;
VAL_ 543 STS_VACATION_MODE 1 "Active" 0 "Default/Inactive" ;
VAL_ 543 STS_SRF_POS 3 "Unable to Detect" 2 "Fully Open" 1 "Partial Open" 0 "Fully Closed / Default" ;
VAL_ 543 CABIN_HVAC_REQ_MBFM 1 "TRUE" 0 "FLASE / Default" ;
VAL_ 543 STS_PWM_POS 3 "Unable to Detect" 2 "Fully Open" 1 "Partial Open" 0 "Fully Closed / Default" ;
VAL_ 543 GP_CLOSE_REQ_RAIN 1 "Request to close glass panel" 0 "No Request / Default" ;
VAL_ 543 GP_CLOSE_REQ_AC 1 "Request to close glass panel" 0 "No Request / Default" ;
VAL_ 543 HEAD_LAMP_SW_STS 7 "Reserved" 6 "Reserved" 5 "Reserved" 4 "FLASH" 3 "HIGH" 2 "LOW" 1 "PARK" 0 "OFF / Default" ;
VAL_ 1089 LKA_SENSITIVITY_FBK 3 "Reserved" 2 "High" 1 "Low" 0 "Normal / Default" ;
VAL_ 1089 USM_RESET 1 "Reset" 0 "Default" ;
VAL_ 1089 SVS_SCREEN_ACTIVE_IC 1 "IC Screen Active" 0 "Not Active" ;
VAL_ 1089 STS_REAR_BREAKPAD_WEAR 1 "Not OK" 0 "Ok/Default Value" ;
VAL_ 1089 STS_FRONT_BREAKPAD_WEAR 1 "Not OK" 0 "Ok/Default Value" ;
VAL_ 1089 STS_HBA_SWT 1 "ON" 0 "Default /OFF" ;
VAL_ 1089 STS_TSR_SWT 1 "ON / Default" 0 "OFF" ;
VAL_ 1089 STS_TJA_SWT 1 "ON" 0 "Default /OFF" ;
VAL_ 1089 ACC_DRIVE_MODE_IC 7 "Signal Invalid" 6 "Reserved" 5 "Reserved" 4 "Reserved" 3 "fast" 2 "Normal" 1 "slow" 0 "Default " ;
VAL_ 1089 STS_AEB_SWT 3 "Reserved" 2 "ON (AEB) / Default" 1 "ON (FCW)" 0 "OFF" ;
VAL_ 1089 AEB_FCW_WARNING_TIMINGS 3 "Reserved" 2 "Early" 1 "Normal /Default" 0 "Late" ;
VAL_ 1089 LDW_LKA_MODE_SWT 3 "Reserved" 2 "LDW+LKA / Default" 1 "LDW" 0 " LDW+LKA OFF" ;
VAL_ 1089 VEH_SPD_UNIT 1 "Miles" 0 "Kmph / Default" ;
VAL_ 1089 VEHICLE_SPEED_IC_DISPLAYED 255 "Signal Invalid" 0 "Default Value" ;
VAL_ 545 STS_EPS_STEERING_MODE 3 "RESERVED" 2 "IN PROGRESS" 1 "ACTIVE" 0 "DEFAULT" ;
VAL_ 545 EPS_STEERING_MODE_ALERT 1 "EPS Steering mode inhibited" 0 "No alert/ DEFAULT" ;
VAL_ 545 EPS_STEERING_MODE 3 "RESERVED" 2 "SPORT" 1 "NORMAL" 0 "COMFORT" ;
VAL_ 545 EPS_DRV_ADV_MODE 7 "Signal Invalid" 6 "Sand / Mode 7" 5 "Mud & Rut / Mode 6" 4 "Grass/Snow / Mode 5" 3 "Normal / Mode 4" 2 "Sport / Mode 3" 1 "City Mode / Mode 2" 0 "Dynamic Mode / Mode 1" ;
VAL_ 545 INDC_EPS 1 "ON" 0 "OFF / Default" ;
VAL_ 545 EPS_FLEX_DISP 1 "Display" 0 "NoDisplay" ;
VAL_ 1407 TSR_OVER_TAKE_SIGN 3 "Reserved" 2 "Reserved" 1 "over take not allow" 0 "no Display / Default" ;
VAL_ 1407 FCM_TSR_OPT_USM 3 "TSR Invalid" 2 "TSR ON" 1 "TSR OFF" 0 "TSR not Applied / Default" ;
VAL_ 1407 TSR_DSP_SPD 255 "Invalid" 254 "End Of speed Limit" 253 "No Recognition" 0 "Default" ;
VAL_ 1407 TSR_SYS_STATE 3 "Condition Traffic Sign" 2 "Temporary Unavailable" 1 "Fail" 0 "Valid /Default" ;
VAL_ 589 AEB_OBJ_CLASSIFICATION_FCM 15 "Reserved" 14 "Reserved" 13 "Reserved" 12 "Reserved" 11 "Reserved" 10 "Reserved" 9 "Reserved" 8 "Unknown" 7 "Undecided" 6 "General Object (Falling obj)" 5 "Pedestrian" 4 "Bicycle" 3 "Motor Bike" 2 "Car" 1 "Truck" 0 "No Object / Default" ;
VAL_ 589 AEB_WARN_SET_STA_FCM 7 "Signal Invalid" 6 "Reserved" 5 "Reserved" 4 "Reserved" 3 "Early" 2 "Normal" 1 "Late" 0 "Not Applied / Default" ;
VAL_ 589 AEB_FAIL_INFO_FCM 3 "Service Required" 2 "Temp. Not Available By Radar" 1 "Temp. Not Available By Camera" 0 "Normal State / Default" ;
VAL_ 589 AEB_WRN_FCM 1 "1st Warning" 0 "No Warning / Default" 3 "3rd Warning" 2 "2nd Warning" ;
VAL_ 589 STS_FCM 3 "Failure" 2 "Blockage" 1 "Normal" 0 "Not applied / Default" ;
VAL_ 589 AEB_ON_OFF_STA_FCM 3 "Signal Invalid" 2 "ON(AEB) / Default" 1 "ON(FCW)" 0 "OFF" ;
VAL_ 589 AEB_ZONE_STS_FCM 7 "Reserved" 6 "Reserved" 5 "Reserved" 4 "Stop Request" 3 "Full Brake Active" 2 "Partial Brake Active" 1 "Prefill Active" 0 "Not Active / Default" ;
VAL_ 592 SBW_WARN 7 "Shift Lock Switch failure" 6 "Park Swtich Failure" 5 "Shift lock not pressed" 4 "Brake Not pressed" 3 "condition is not P" 2 "cannot change gear" 1 "TGS Service warning" 0 "No warning/Default Value" 15 "Signal Invalid" ;
VAL_ 592 SBW_FAULT 3 "Reserved" 2 "Reserved" 1 "Fault Present in TGS" 0 "No Fault Present in TGS / DV" ;
VAL_ 592 SBW_LEVER 7 "Neutral" 6 "Drive" 5 "Reserved" 4 "Reserved" 3 "Reserved" 2 "Reserved" 1 "Reserved" 0 "Reserved" ;
VAL_ 971 STS_AUTO_HEAT 1 "Enable" 0 "Disable / Default Value" ;
VAL_ 971 STS_SEAT_POSITION_DISPLAY 1 "Enable" 0 "Disable / Default Value" ;
VAL_ 971 STS_AUTO_VENT 1 "Enable" 0 "Disable / Default Value" ;
VAL_ 971 APA_HMI_FBK 63 "Signal Invalid" 12 "0XC to 0x3E:Reserved" 11 "Cancel" 10 "OK" 9 "RHS Perpendi drive out Pressed" 8 "LHS Perpendi drive out Pressed" 7 "RHS Parallel drive out Pressed" 6 "LHS Parallel drive out Pressed" 5 "Right Side Search Icon Pressed" 4 "Left Side Search Icon Pressed" 3 "CMBS Soft Switch Pressed" 2 "APA Soft Switch Pressed" 1 "PAS Soft Switch Pressed" 0 "Default Value" ;
VAL_ 971 PASSIVE_VENT_CONTROL_IS 1 "Enable" 0 "Default / Disabled" ;
VAL_ 971 PASSIVE_VENT_TIMER 7 "7 hour" 6 "6 hour" 5 "5 hour" 4 "4 hour" 3 "3 hour" 2 "2 hour" 1 "1 hour" 0 " Default / OFF" ;
VAL_ 971 PASSIVE_VENT_CYCLE 3 "3  cycle" 2 "2  cycle" 1 "1 cycle" 0 "Default" ;
VAL_ 971 STS_AUTO_DIP 1 "Enable" 0 "Disable/DV" ;
VAL_ 971 STS_EASY_ENTRY 1 "Enable" 0 "Disable/DV" ;
VAL_ 971 STS_EASY_EXIT 1 "Enable" 0 "Disable/DV" ;
VAL_ 971 STS_SEAT_PROFILE_IS 3 "Guest" 2 "Profile 2" 1 "Profile 1" 0 "No profile/default value" ;
VAL_ 971 STS_BS_ORVM_ADJUST 1 "Enable" 0 "Disable/DV" ;
VAL_ 971 STS_REV_GEAR_SIREN 1 "Enable" 0 "Disable/DV" ;
VAL_ 971 STS_AUTO_TURN_LAMP 1 "Enable" 0 "Disable/DV" ;
VAL_ 971 STS_HEAT_VENT_IS 7 "Reserved" 6 "Reserved" 5 "Reserved" 4 "Auto Vent ON" 3 "Auto Heat ON" 2 "Vent ON" 1 "Heat ON" 0 "Default" ;
VAL_ 971 STS_SELECT_UNLOCK 1 "Enable" 0 "Disable/DV" ;
VAL_ 971 FR_SEAT_HEAT_VENT_LEVEL_IS 3 "Level 3" 2 "Level 2" 1 "Level 1" 0 " Default" ;
VAL_ 971 FL_SEAT_HEAT_VENT_LEVEL_IS 3 "Level 3" 2 "Level 2" 1 "Level 1" 0 " Default" ;
VAL_ 971 SET_TIRE_FILL_ASST_IS 1 "Enable/Default" 0 "Disable" ;
VAL_ 971 TPMS_AUTOLEARN_IS 1 "Enable/Default" 0 "Disable" ;
VAL_ 971 INST_ECO_INDEX 127 "Signal Invalid" 100 "Default Value" ;
VAL_ 971 ECO_INDEX 127 "Signal Invalid" 100 "Default Value" ;
VAL_ 971 RES_DRIVESCORE_INFO 1 "Fresh Data" 0 "Default" ;
VAL_ 299 BMS_IsolationResis 65535 "Signal Invalid" 0 "Default" ;
VAL_ 299 BMS_NC_Count 65535 "Signal Invalid" 0 "Default Value" ;
VAL_ 299 BMS_FC_Count 65535 "Signal Invalid" 0 "Default Value" ;
VAL_ 1004 BMS_CellVoltage44 1023 "Signal Invalid" 0 "Default Value" ;
VAL_ 1004 BMS_CellVoltage43 1023 "Signal Invalid" 0 "Default Value" ;
VAL_ 1004 BMS_CellVoltage42 1023 "Signal Invalid" 0 "Default Value" ;
VAL_ 1004 BMS_CellVoltage41 1023 "Signal Invalid" 0 "Default Value" ;
VAL_ 1004 BMS_CellVoltage40 1023 "Signal Invalid" 0 "Default Value" ;
VAL_ 1004 BMS_CellVoltage4 1023 "Signal Invalid" 0 "Default Value" ;
VAL_ 1004 BMS_CellVoltage39 1023 "Signal Invalid" 0 "Default Value" ;
VAL_ 1004 BMS_CellVoltage38 1023 "Signal Invalid" 0 "Default Value" ;
VAL_ 1004 BMS_CellVoltage37 1023 "Signal Invalid" 0 "Default Value" ;
VAL_ 1004 BMS_CellVoltage36 1023 "Signal Invalid" 0 "Default Value" ;
VAL_ 1004 BMS_CellVoltage35 1023 "Signal Invalid" 0 "Default Value" ;
VAL_ 1004 BMS_CellVoltage34 1023 "Signal Invalid" 0 "Default Value" ;
VAL_ 1004 BMS_CellVoltage33 1023 "Signal Invalid" 0 "Default Value" ;
VAL_ 1004 BMS_CellVoltage32 1023 "Signal Invalid" 0 "Default Value" ;
VAL_ 1004 BMS_CellVoltage31 1023 "Signal Invalid" 0 "Default Value" ;
VAL_ 1004 BMS_CellVoltage30 1023 "Signal Invalid" 0 "Default Value" ;
VAL_ 1004 BMS_CellVoltage3 1023 "Signal Invalid" 0 "Default Value" ;
VAL_ 1004 BMS_CellVoltage29 1023 "Signal Invalid" 0 "Default Value" ;
VAL_ 1004 BMS_CellVoltage28 1023 "Signal Invalid" 0 "Default Value" ;
VAL_ 1004 BMS_CellVoltage27 1023 "Signal Invalid" 0 "Default Value" ;
VAL_ 1004 BMS_CellVoltage26 1023 "Signal Invalid" 0 "Default Value" ;
VAL_ 1004 BMS_CellVoltage25 1023 "Signal Invalid" 0 "Default Value" ;
VAL_ 1004 BMS_CellVoltage24 1023 "Signal Invalid" 0 "Default Value" ;
VAL_ 1004 BMS_CellVoltage23 1023 "Signal Invalid" 0 "Default Value" ;
VAL_ 1004 BMS_CellVoltage22 1023 "Signal Invalid" 0 "Default Value" ;
VAL_ 1004 BMS_CellVoltage21 1023 "Signal Invalid" 0 "Default Value" ;
VAL_ 1004 BMS_CellVoltage20 1023 "Signal Invalid" 0 "Default Value" ;
VAL_ 1004 BMS_CellVoltage96 1023 "Signal Invalid" 0 "Default Value" ;
VAL_ 1004 BMS_CellVoltage95 1023 "Signal Invalid" 0 "Default Value" ;
VAL_ 1004 BMS_CellVoltage94 1023 "Signal Invalid" 0 "Default Value" ;
VAL_ 1004 BMS_CellVoltage93 1023 "Signal Invalid" 0 "Default Value" ;
VAL_ 1004 BMS_CellVoltage92 1023 "Signal Invalid" 0 "Default Value" ;
VAL_ 1004 BMS_CellVoltage91 1023 "Signal Invalid" 0 "Default Value" ;
VAL_ 1004 BMS_CellVoltage90 1023 "Signal Invalid" 0 "Default Value" ;
VAL_ 1004 BMS_CellVoltage9 1023 "Signal Invalid" 0 "Default Value" ;
VAL_ 1004 BMS_CellVoltage89 1023 "Signal Invalid" 0 "Default Value" ;
VAL_ 1004 BMS_CellVoltage88 1023 "Signal Invalid" 0 "Default Value" ;
VAL_ 1004 BMS_CellVoltage87 1023 "Signal Invalid" 0 "Default Value" ;
VAL_ 1004 BMS_CellVoltage86 1023 "Signal Invalid" 0 "Default Value" ;
VAL_ 1004 BMS_CellVoltage85 1023 "Signal Invalid" 0 "Default Value" ;
VAL_ 1004 BMS_CellVoltage84 1023 "Signal Invalid" 0 "Default Value" ;
VAL_ 1004 BMS_CellVoltage83 1023 "Signal Invalid" 0 "Default Value" ;
VAL_ 1004 BMS_CellVoltage82 1023 "Signal Invalid" 0 "Default Value" ;
VAL_ 1004 BMS_CellVoltage81 1023 "Signal Invalid" 0 "Default Value" ;
VAL_ 1004 BMS_CellVoltage80 1023 "Signal Invalid" 0 "Default Value" ;
VAL_ 1004 BMS_CellVoltage8 1023 "Signal Invalid" 0 "Default Value" ;
VAL_ 1004 BMS_CellVoltage79 1023 "Signal Invalid" 0 "Default Value" ;
VAL_ 1004 BMS_CellVoltage78 1023 "Signal Invalid" 0 "Default Value" ;
VAL_ 1004 BMS_CellVoltage77 1023 "Signal Invalid" 0 "Default Value" ;
VAL_ 1004 BMS_CellVoltage76 1023 "Signal Invalid" 0 "Default Value" ;
VAL_ 1004 BMS_CellVoltage75 1023 "Signal Invalid" 0 "Default Value" ;
VAL_ 1004 BMS_CellVoltage74 1023 "Signal Invalid" 0 "Default Value" ;
VAL_ 1004 BMS_CellVoltage73 1023 "Signal Invalid" 0 "Default Value" ;
VAL_ 1004 BMS_CellVoltage72 1023 "Signal Invalid" 0 "Default Value" ;
VAL_ 1004 BMS_CellVoltage71 1023 "Signal Invalid" 0 "Default Value" ;
VAL_ 1004 BMS_CellVoltage70 1023 "Signal Invalid" 0 "Default Value" ;
VAL_ 1004 BMS_CellVoltage7 1023 "Signal Invalid" 0 "Default Value" ;
VAL_ 1004 BMS_CellVoltage69 1023 "Signal Invalid" 0 "Default Value" ;
VAL_ 1004 BMS_CellVoltage68 1023 "Signal Invalid" 0 "Default Value" ;
VAL_ 1004 BMS_CellVoltage67 1023 "Signal Invalid" 0 "Default Value" ;
VAL_ 1004 BMS_CellVoltage66 1023 "Signal Invalid" 0 "Default Value" ;
VAL_ 1004 BMS_CellVoltage65 1023 "Signal Invalid" 0 "Default Value" ;
VAL_ 1004 BMS_CellVoltage64 1023 "Signal Invalid" 0 "Default Value" ;
VAL_ 1004 BMS_CellVoltage63 1023 "Signal Invalid" 0 "Default Value" ;
VAL_ 1004 BMS_CellVoltage62 1023 "Signal Invalid" 0 "Default Value" ;
VAL_ 1004 BMS_CellVoltage61 1023 "Signal Invalid" 0 "Default Value" ;
VAL_ 1004 BMS_CellVoltage60 1023 "Signal Invalid" 0 "Default Value" ;
VAL_ 1004 BMS_CellVoltage6 1023 "Signal Invalid" 0 "Default Value" ;
VAL_ 1004 BMS_CellVoltage59 1023 "Signal Invalid" 0 "Default Value" ;
VAL_ 1004 BMS_CellVoltage58 1023 "Signal Invalid" 0 "Default Value" ;
VAL_ 1004 BMS_CellVoltage57 1023 "Signal Invalid" 0 "Default Value" ;
VAL_ 1004 BMS_CellVoltage56 1023 "Signal Invalid" 0 "Default Value" ;
VAL_ 1004 BMS_CellVoltage55 1023 "Signal Invalid" 0 "Default Value" ;
VAL_ 1004 BMS_CellVoltage54 1023 "Signal Invalid" 0 "Default Value" ;
VAL_ 1004 BMS_CellVoltage53 1023 "Signal Invalid" 0 "Default Value" ;
VAL_ 1004 BMS_CellVoltage52 1023 "Signal Invalid" 0 "Default Value" ;
VAL_ 1004 BMS_CellVoltage51 1023 "Signal Invalid" 0 "Default Value" ;
VAL_ 1004 BMS_CellVoltage50 1023 "Signal Invalid" 0 "Default Value" ;
VAL_ 1004 BMS_CellVoltage5 1023 "Signal Invalid" 0 "Default Value" ;
VAL_ 1004 BMS_CellVoltage49 1023 "Signal Invalid" 0 "Default Value" ;
VAL_ 1004 BMS_CellVoltage48 1023 "Signal Invalid" 0 "Default Value" ;
VAL_ 1004 BMS_CellVoltage47 1023 "Signal Invalid" 0 "Default Value" ;
VAL_ 1004 BMS_CellVoltage46 1023 "Signal Invalid" 0 "Default Value" ;
VAL_ 1004 BMS_CellVoltage45 1023 "Signal Invalid" 0 "Default Value" ;
VAL_ 1004 BMS_CellVoltage2 1023 "Signal Invalid" 0 "Default Value" ;
VAL_ 1004 BMS_CellVoltage19 0 "Default Value" 1023 "Signal Invalid" ;
VAL_ 1004 BMS_CellVoltage18 1023 "Signal Invalid" 0 "Default Value" ;
VAL_ 1004 BMS_CellVoltage17 1023 "Signal Invalid" 0 "Default Value" ;
VAL_ 1004 BMS_CellVoltage16 1023 "Signal Invalid" 0 "Default Value" ;
VAL_ 1004 BMS_CellVoltage15 1023 "Signal Invalid" 0 "Default Value" ;
VAL_ 1004 BMS_CellVoltage14 1023 "Signal Invalid" 0 "Default Value" ;
VAL_ 1004 BMS_CellVoltage13 1023 "Signal Invalid" 0 "Default Value" ;
VAL_ 1004 BMS_CellVoltage12 1023 "Signal Invalid" 0 "Default Value" ;
VAL_ 1004 BMS_CellVoltage11 1023 "Signal Invalid" 0 "Default Value" ;
VAL_ 1004 BMS_CellVoltage10 1023 "Signal Invalid" 0 "Default Value" ;
VAL_ 1004 BMS_CellVoltage1 1023 "Signal Invalid" 0 "Default Value" ;
VAL_ 1004 BMS_CellVoltage_Index 15 "index-F" 14 "index-E" 13 "index-D" 12 "index-C" 11 "index-B" 10 "index-A" 9 "index-9" 8 "index-8" 7 "index-7" 6 "index-6" 5 "index-5" 4 "index-4" 3 "index-3" 2 "index-2" 1 "index-1" 0 "index-0" ;
VAL_ 770 DISCHARGE_LINE_PRESSURE 511 "Signal Invalid" 0 "Default Value" ;
VAL_ 770 STS_PTC_HEATER 3 "Heater Failure" 2 "Fault in Heater" 1 "ON" 0 "OFF / Default Value" ;
VAL_ 770 REQ_ACC_ON 1 "AC Compressor ON" 0 "AC Compressor OFF / Default" ;
VAL_ 770 COMPRESSURE_SPD 65535 "Signal Invalid" 0 "Blower OFF / Default Value" ;
VAL_ 541 SPARE_TYRE_TEMP_TPMS 255 "Signal invalid" 0 "Default Value" ;
VAL_ 541 SPARE_TYRE_PRESSURE_TPMS 255 "Signal Invalid" 0 "Default value" ;
VAL_ 542 RR_TYRE_TEMP_TPMS 255 "Signal invalid" 0 "Default Value" ;
VAL_ 542 RR_TYRE_PRESSURE_TPMS 255 "Signal invalid" 0 "Default Value" ;
VAL_ 542 RL_TYRE_TEMP_TPMS 255 "Signal invalid" 0 "Default Value" ;
VAL_ 542 RL_TYRE_PRESSURE_TPMS 255 "Signal invalid" 0 "Default Value" ;
VAL_ 542 FR_TYRE_TEMP_TPMS 255 "Signal invalid" 0 "Default Value" ;
VAL_ 542 FR_TYRE_PRESSURE_TPMS 255 "Signal invalid" 0 "Default Value" ;
VAL_ 542 FL_TYRE_TEMP_TPMS 255 "Signal invalid" 0 "Default Value" ;
VAL_ 542 FL_TYRE_PRESSURE_TPMS 255 "Signal invalid" 0 "Default Value" ;
VAL_ 537 TPMS_SYSTEM_FAULT_TPMS 0 "Default value" ;
VAL_ 537 TPMS_SIGNAL_MISSING_TPMS 0 "Default value" ;
VAL_ 537 TPMS_PROGRAM_MODE 9 "signal invalid" 8 "Learning not completed" 7 "All tyre learned" 6 "Learn spare tyre" 5 "Learn RL tyre" 4 "Learn RR tyre" 3 "Learn FR tyre" 2 "Learn FL tyre" 1 "Enter programming mode" 0 "Normal mode / default" ;
VAL_ 537 TPMS_MALFUNCTION 7 "Signal Invalid" 6 "TPMS sensor fault & ID not lea" 5 "TPMS sensor fault & Rx fault" 4 "TPMS sensor fault" 3 "TPMS ID not learned & Rx fault" 2 "TPMS ID not learned" 1 "TPMS Rx fault" 0 "Normal / default" ;
VAL_ 537 TPMS_LEAKAGE_ALERT_TPMS 0 "Default value" ;
VAL_ 537 TPMS_ID_NOT_LEARNT_TPMS 31 "All tyre ssor nt learn" 30 "(FR+RR+RL+spare) tyre ssor nt le" 29 "(FL+RR+RL+spare) tyre ssor nt le" 28 "(RR+RL+spare) tyre ssor nt learn" 27 "(FL+FR+RL+spare) tyre ssor nt le" 26 "(FR+RL+spare) tyre ssor nt learn" 25 "(FL+RL+spare) tyre ssor nt learn" 24 "(RL+spare) tyre sensor not learn" 23 "(FL+FR+RR+Spare) tyre ssor nt le" 22 "(FR+RR+Spare) tyre sensor not le" 21 "(FL+RR+Spare) tyre snsor not lea" 20 "(RR+Spare) tyre sensor not lea" 19 "(FL+FR+Spare) tyre snsor not lea" 18 "(FR+Spare) tyre sensor not learn" 17 "(FL+Spare) tyre sensor not learn" 16 "Spare tyre sensor not learned" 15 "(FL+FR+RR +RL)tyre snsor not lea" 14 "(FR+RR +RL)tyre sensor not lea" 13 "(FL+RR +RL)tyre sensor not lea" 12 "(RR +RL)tyre sensor not learned" 11 "(FL+FR +RL)tyre sensor not lea" 10 "(FR +RL)tyre sensor not learned" 9 "(FL +RL)tyre sensor not learned" 8 "RL tyre sensor not learned" 7 "(FL+FR +RR)tyre sensor not le" 6 "(FR +RR)tyre sensor not learned" 5 "(FL +RR)tyre sensor not learned" 4 "RR tyre sensor not learned" 3 "(FL +FR)tyre sensor not learned" 2 "FR tyre sensor not learned" 1 "FL tyre sensor not learned" 0 "All sensor learned / Default" ;
VAL_ 537 STS_TPMS_LED_TPMS 7 "Reserved" 6 "Reserved" 5 "Reserved" 4 "Reserved" 3 "Continously ON" 2 "Blinking pattern 2" 1 "Blinking pattern 1" 0 "OFF / Default value" ;
VAL_ 537 SPARE_TYRE_SWAP_TPMS 7 "Signal Invalid" 4 "RL tyre swapped" 3 "RR tyre swapped" 2 "FR tyre swapped" 1 "FL tyre swapped" 0 "No spare tyre swap / default " ;
VAL_ 537 REQ_TFA_PATTERN 5 "Pattern 5" 4 "Pattern 4" 3 "Pattern 3" 2 "Pattern 2" 1 "Pattern 1" 0 "Default" ;
VAL_ 537 REQ_TFA_DISPLAY_TPMS 1 "TFA display request" 0 "No Request / Default" ;
VAL_ 537 LOW_TYRE_PRESSURE_TPMS 31 "All tyre low pressure" 30 "(FR+RR+RL+spare) tyre low press" 29 "(FL+RR+RL+spare) tyre low press" 28 "(RR+RL+spare) tyre low pressure" 27 "(FL+FR+RL+spare) tyre low press" 26 "(FR+RL+spare) tyre low pressure" 25 "(FL+RL+spare) tyre low pressure" 24 "(RL+spare) tyre low pressure" 23 "(FL+FR+RR+Spare) tyre low press" 22 "(FR+RR+Spare) tyre low press" 21 "(FL+RR+Spare) tyre low pressure" 20 "(RR+Spare) tyre low pressure" 19 "(FL+FR+Spare) tyre low pressure" 18 "(FR+Spare) tyre low pressure" 17 "(FL+Spare) tyre low pressure" 16 "Spare tyre low pressure" 15 "(FL+FR+RR +RL)tyre low pressure" 14 "(FR+RR +RL)tyre low pressure" 13 "(FL+RR +RL)tyre low pressure" 12 "(RR +RL)tyre low pressure" 11 "(FL+FR +RL)tyre low pressure" 10 "(FR +RL)tyre low pressure" 9 "(FL +RL)tyre low pressure" 8 "RL tyre low pressure" 7 "(FL+FR +RR)tyre low pressure" 6 "(FR +RR)tyre low pressure" 5 "(FL +RR)tyre low pressure" 4 "RR tyre low pressure" 3 "(FL +FR)tyre low pressure" 2 "FR tyre low pressure" 1 "FL tyre low pressure" 0 "All tyre normal / Default value" ;
VAL_ 537 HIGH_TYRE_TEMPERATURE_TPMS 31 "All tyre high  temp" 30 "(FR+RR+RL+spare) tyre high  temp" 29 "(FL+RR+RL+spare) tyre high  temp" 28 "(RR+RL+spare) tyre high  temp" 27 "(FL+FR+RL+spare) tyre high  temp" 26 "(FR+RL+spare) tyre high  temp" 25 "(FL+RL+spare) tyre high  temp" 24 "(RL+spare) tyre high  temp" 23 "(FL+FR+RR+Spare) tyre high  temp" 22 "(FR+RR+Spare) tyre high  temp" 21 "(FL+RR+Spare) tyre high  temp" 20 "(RR+Spare) tyre high  temp" 19 "(FL+FR+Spare) tyre high  temp" 18 "(FR+Spare) tyre high  temp" 17 "(FL+Spare) tyre high  temp" 16 "Spare tyre high  temp" 15 "(FL+FR+RR +RL)tyre high  temp" 14 "(FR+RR +RL)tyre high  temp" 13 "(FL+RR +RL)tyre high  temp" 12 "(RR +RL)tyre high  temp" 11 "(FL+FR +RL)tyre high  temp" 10 "(FR +RL)tyre high  temp" 9 "(FL +RL)tyre high  temp" 8 "RL tyre high  temp" 7 "(FL+FR +RR)tyre high  temp" 6 "(FR +RR)tyre high  temp" 5 "(FL +RR)tyre high  temp" 4 "RR tyre high  temp" 3 "(FL +FR)tyre high  temp" 2 "FR tyre high temp" 1 "FL tyre high temp" 0 "All tyre normal / Default value" ;
VAL_ 537 HIGH_TYRE_PRESSURE_TPMS 31 "All tyre high pressure" 30 "(FR+RR+RL+spare) tyre high press" 29 "(FL+RR+RL+spare) tyre high press" 28 "(RR+RL+spare) tyre high pressure" 27 "(FL+FR+RL+spare) tyre high press" 26 "(FR+RL+spare) tyre high pressure" 25 "(FL+RL+spare) tyre high pressure" 24 "(RL+spare) tyre high pressure" 23 "(FL+FR+RR+Spare) tyre high press" 22 "(FR+RR+Spare) tyre high press" 21 "(FL+RR+Spare) tyre high pressure" 20 "(RR+Spare) tyre high pressure" 19 "(FL+FR+Spare) tyre high pressure" 18 "(FR+Spare) tyre high pressure" 17 "(FL+Spare) tyre high pressure" 16 "Spare tyre high pressure" 15 "(FL+FR+RR +RL)tyre high pressure" 14 "(FR+RR +RL)tyre high pressure" 13 "(FL+RR +RL)tyre high pressure" 12 "(RR +RL)tyre high pressure" 11 "(FL+FR +RL)tyre high pressure" 10 "(FR +RL)tyre high pressure" 9 "(FL +RL)tyre high pressure" 8 "RL tyre high pressure" 7 "(FL+FR +RR)tyre high pressure" 6 "(FR +RR)tyre high pressure" 5 "(FL +RR)tyre high pressure" 4 "RR tyre high pressure" 3 "(FL +FR)tyre high pressure" 2 "FR tyre high pressure" 1 "FL tyre high pressure" 0 "All tyre normal / Default value" ;
VAL_ 970 TPMS_PRESSURE_FORMAT_IS 1 "kpa" 0 "Default Value/psi" ;
VAL_ 970 TEMPERATURE_FORMAT_IS 1 "Deg F" 0 "Deg C/ Default Value" ;
VAL_ 970 CALENDER_FORMAT_IS 1 "MM/DD/YY" 0 "DD/MM/YY" ;
VAL_ 970 STS_NAV_ROUTE 3 "Carplay Nav Route Set" 2 "Android Auto NAV Route set" 1 "Native NAV Route set" 0 "No Active Route / DV" ;
VAL_ 970 NATIVE_NAV_TURN_INDC 15 "Undefined turn" 14 "Bear Right" 13 "Bear Left" 12 "Round about Left 270 Deg" 11 "Round about Left 180 Deg" 10 "Round about Left 90 Deg" 9 "Round about Right 270 Deg" 8 "Round about Right 180 Deg" 7 "Round about Right 90 Deg" 6 "Destination Reached" 5 "U Turn Right" 4 "U Turn Left" 3 "Turn Right" 2 "Turn Left" 1 "Straight" 0 "No Alert / Default" ;
VAL_ 970 NATIVE_NAV_DIST 51 "0x33 to 0xFD - reserved" 255 "Signal Invalid" 254 "Distance above 500 mts" 0 "Default" ;
VAL_ 970 CLOCK_FORMAT 1 "24 Hour mode" 0 "12 Hour mode / Default" ;
VAL_ 970 MEDIA_STATE 1 "ON" 0 "OFF/Default Value" ;
VAL_ 769 DPF_BAD_REGEN_EFFICIENCY 3 "Reserved" 2 "Red" 1 "Yellow" 0 "Green / Default" ;
VAL_ 555 FLOAT_SENSOR_RESISTANCE_RAW 1 "Signal invalid" 0 "Default value" ;
VAL_ 555 DTE_CALCULATED_AFE 511 "Signal invalid" 0 "Default value" ;
VAL_ 555 CALCULATED_DTE 1023 "signal invalid" 0 "default value" ;
VAL_ 555 CALCULATED_AFE 511 "Signal invalid" 0 "Default value" ;
VAL_ 555 VEHICLE_SPEED_IC 65535 "Signal Invalid" 65534 "Default Value" ;
VAL_ 547 CALCULATED_AFE_GD 511 "Signal invalid" 0 "Default value" ;
VAL_ 547 FLOAT_RESISTANCE_FILTER 1023 "Signal Invalid" 1022 "Empty tank / default value" ;
VAL_ 547 FLOAT_RESISTANCE_RAW 1023 "Signal Invalid" 1022 "Empty Tank / Default value" ;
VAL_ 547 FUEL_LVL_DTE_FILTER 65535 "Signal Invalid" 65534 "Default value" ;
VAL_ 547 FUEL_LVL_RAW 65535 "Signal Invalid" 65534 "Default value" ;
VAL_ 548 FUEL_CONSMP_ACCUMULATED 65535 "Signal Invalid" 0 "Default value" ;
VAL_ 548 AFE_ACCUMULATED_FUEL_CONSMP 8191 "Signal Invalid" 0 "Default Value" ;
VAL_ 548 AFE_ACCUMULATED_DISTANCE 2047 "Signal Invalid" 0 "Default Value" ;
VAL_ 918 HBA_USM_FB 3 "Signal Invalid" 2 "ON" 1 "OFF" 0 "No option / Default" ;
VAL_ 918 HBA_STS 3 "HBA System failure" 2 "HBA On & High Beam On" 1 "HBA On & High Beam Off" 0 "HBA OFF / Default" ;
VAL_ 918 HBA_LAMP_STS 1 "On" 0 "Off / Default" ;
VAL_ 902 ACC_HVIL_STATUS 3 "Signal Invalid" 2 "Reserved" 1 "Open/ Fault" 0 "Closed/ No fault" ;
VAL_ 902 COMPRESSOR_TEMPERATURE 255 "Signal Invalid" 0 "Default Value" ;
VAL_ 902 ACC_CTRL_OUTPUT_POWER 65535 "Signal Invalid" 0 "Default Value" ;
VAL_ 901 STS_ACC_COMPRESSOR 1 "Not OK" 0 "OK / Default Value" ;
VAL_ 901 ACC_CONTROLLER_OVERHEAT_FAULT 1 "Controller Overheat Fault" 0 "No Fault" ;
VAL_ 901 ACC_OVERCURRENT_FAULT 1 "Overcurrent Fault" 0 "No Fault / Default Value" ;
VAL_ 901 ACC_OVERVOLTAGE_FAULT 1 "Overvoltage Fault" 0 "No Fault / Default Value" ;
VAL_ 901 ACC_UNDERVOLTAGE_FAULT 1 "Undervoltage Fault" 0 "No Fault / Default Value" ;
VAL_ 901 ACC_MOTOR_OVERHEAT_FAULT 1 "Motor Overheat Fault" 0 "No Fault" ;
VAL_ 901 ACC_INPUT_DC_CURRENT 63 "Signal Invalid" 0 "Default Value" ;
VAL_ 901 ACC_COM_FAULT 1 "ACC Communication Fault" 0 "No Fault" ;
VAL_ 632 TGS_MODE 3 "Signal Invalid" 2 "Warm Up" 1 "Manual" 0 "Normal / Default Value" ;
VAL_ 632 INDC_AT_MALFUNC 3 "Signal invalid" 2 "Lamp bliking" 1 "Lamp ON" 0 "Lamp OFF / Default value" ;
VAL_ 632 TRANS_MIL_LAMP 3 "Reserved" 2 "Lamp ON" 1 "Reserved" 0 "Lamp OFF / Default value" ;
VAL_ 632 TGS_LEVER 15 "Signal Invalid" 14 "Middle Position" 13 "Default Value" 12 "M - Forward Drive Position" 11 "Tip -" 10 "Tip +" 9 "Park " 8 "Reverse" 7 "Neutral" 6 "Drive" 5 "Reserved" 4 "Reserved" 3 "Reserved" 2 "Reserved" 1 "Reserved" 0 "Reserved" ;
VAL_ 849 WIPER_VOL_LVL 7 "Reserved" 6 "Reserved" 5 "Reserved" 4 "Level 5" 3 "Level 4" 2 "Level 3" 1 "Level 2" 0 "Level 1" ;
VAL_ 849 SENSOR_LEARNT_STS 1 "Auto Learn Finished" 0 "Auto Learn Not Finished / DV" ;
VAL_ 849 STS_AUTO_LOCATION 1 "Auto Location is Finished" 0 "Auto Location is Not Finished/DV" ;
VAL_ 849 TIRE_BALANCE_STS 3 "Front and Rear Tire Imbalance" 2 "Rear Tire Imbalance" 1 "Front Tire Imbalance" 0 "Normal/ DV" ;
VAL_ 849 ECU_DEFECT 1 "Defect" 0 "Normal/No Defect/ Default" ;
VAL_ 849 STS_WIPER_SWT 3 "High" 2 "Low" 1 "Auto / Intermittent" 0 "OFF/DV" ;
VAL_ 849 STS_SIREN 1 "ON" 0 "OFF" ;
VAL_ 849 STS_REAR_WIPER_SWT 3 "Reserved" 2 "Low" 1 "Intermittent" 0 "Off / Default" ;
VAL_ 849 STS_FRNT_WIPER 3 "Front Wiper in High Speed" 2 "Front Wiper in Low speed" 1 "Front Wiper in Int speed" 0 "Front Wiper No operation" ;
VAL_ 849 STS_AMB_LIGHT 1 "ON" 0 "OFF" ;
VAL_ 369 MASTER_CYL_PRESSURE 65535 "Signal Invalid" 65534 "Default Value" ;
VAL_ 368 YAW_RATE 65535 "Signal Invalid" 0 "Default Value" ;
VAL_ 368 LONG_ACCEL 65535 "Signal Invalid" 0 "Default Value" ;
VAL_ 368 LATTERAL_ACCEL 65535 "Signal Invalid" 0 "Default Value" ;
VAL_ 271 STS_IGN_ESC 3 "Reserved" 2 "Reserved" 1 "IGN ON" 0 "IGN OFF / Default" ;
VAL_ 271 WHL_RR_SPD 4095 "Signal invalid" 0 "Default" ;
VAL_ 271 WHL_RL_SPD 4095 "Signal invalid" 0 "Default" ;
VAL_ 271 WHL_FR_SPD 4095 "Signal invalid" 0 "Default value" ;
VAL_ 271 WHL_FL_SPD 4095 "Signal Invalid" 0 "Default Value" ;
VAL_ 544 FRONT_RIGHT_SET_TEMP_IS 255 "Signal Invalid" 254 "Default Value" ;
VAL_ 544 FRONT_LEFT_SET_TEMP_IS 255 "Signal Invalid" 254 "Default Value" ;
VAL_ 544 DISP_DUAL_IS 3 "Signal Invalid" 2 "Default Value" 1 "SINGLE Zone" 0 "DUAL Zone" ;
VAL_ 544 VALET_MODE_STATE 3 "Reserved" 2 "Reserved" 1 "Activate Valet Mode" 0 "Normal Mode / Default Value" ;
VAL_ 544 STS_REAR_DEFOG_IS 3 "Signal Invalid" 2 "ON" 1 "OFF" 0 "Default Value" ;
VAL_ 544 STS_REAR_AC_IS 3 "Signal Invalid" 2 "Default Value" 1 "ON" 0 "OFF" ;
VAL_ 544 MEM_DISP_IS 2 "ON/Pressed" 1 "Off / Not Pressed" 0 "Default Value" ;
VAL_ 544 REQ_TRIP_RESET 1 "Reset request" 0 "Default Value" ;
VAL_ 544 ILLUMINATION_LEVEL 15 "Signal Invalid" 8 "Illumination Level 8" 7 "Illumination Level 7" 6 "Illumination Level 6" 5 "Illumination Level 5" 4 "Illumination Level 4" 3 "Illumination Level 3" 2 "Illumination Level 2" 1 "Illumination Level 1" 0 "Default Value" ;
VAL_ 544 FRESH_RECIRC_IS 3 "Signal Invalid" 2 "Default Value" 1 "Recirculation" 0 "Freash" ;
VAL_ 544 IS_RVC_VIDEO_ENBL 7 "Description for the value '0x7'" 6 "Description for the value '0x6'" 5 "Description for the value '0x5'" 4 "Description for the value '0x4'" 3 "Description for the value '0x3'" 2 "Description for the value '0x2'" 1 "Description for the value '0x1'" 0 "Description for the value '0x0'" ;
VAL_ 544 CMD_USER_INPUT1 7 "Reserved" 6 "Zoom Out" 5 "Zoom In" 4 "Reset to parallel parking" 3 "Normal parking" 2 "Angle Parking" 1 "Parallel Parking" 0 "No Input/ Default" ;
VAL_ 544 RESET_AFE 1 "Reset Request" 0 "No Reset Request / Default" ;
VAL_ 544 DRL_EN_SW 1 "DRL OFF" 0 "DRL ON / Default" ;
VAL_ 544 DISP_OFF_IS 3 "Signal Invalid" 2 "HVAC system OFF(Blower OFF)" 1 "ON" 0 "Default Value" ;
VAL_ 544 DISP_ECON_IS 3 "Signal Invalid" 2 "Default Value" 1 "ECON ON" 0 "ECON OFF" ;
VAL_ 544 DISP_BLOWER_IS 15 "Signal Invalid" 14 "Default Value" 13 "Reserved" 12 "Reserved" 11 "Reserved" 10 "Reserved" 9 "8 - Step" 8 "7 - Step" 7 "6 - Step" 6 "5 - Step" 5 "4 - Step" 4 "3 - Step" 3 "2 - Step" 2 "1 - Step" 1 "0 - Step" 0 "OFF" ;
VAL_ 544 DISP_AUTO_IS 3 "Signal Invalid" 2 "Default Value" 1 "Auto ON" 0 "Auto OFF" ;
VAL_ 544 AC_REQ_IS 3 "Signal Invalid" 2 "Default Value" 1 "AC ON" 0 "AC OFF" ;
VAL_ 544 DISP_MODE_IS 15 "Signal Invalid" 14 "Default Value" 13 "Reserved" 12 "Reserved" 11 "Reserved" 10 "Reserved" 9 "Reserved" 8 "Reserved" 7 "Reserved" 6 "Reserved" 5 "Def" 4 "Floor / Def" 3 "Floor" 2 "Vent / Floor" 1 "Vent" 0 "OFF" ;
VAL_ 704 STS_SEAT_BLT_PSGR 3 "Reserved" 2 "Buckle Faulty" 1 "Buckled" 0 "Not Buckled / Default value" ;
VAL_ 704 STS_SEAT_BLT_DRV 3 "Reserved" 2 "Buckle Faulty" 1 "Buckled" 0 "Not Buckled / Default value" ;
VAL_ 704 STS_CRASH_OUTPUT 3 "Left Hand Side" 2 "Right Hand Side" 1 "Front Crash" 0 "No Crash / Default" ;
VAL_ 704 EVEN_PARITY_BIT 1 "Even" 0 "Odd / DV" ;
VAL_ 704 INDC_PADL 1 "Lamp ON" 0 "Lamp OFF/DV" ;
VAL_ 704 STS_CRASH 1 "CRASH(Request to stop engine)" 0 "No Request / Default" ;
VAL_ 704 DOOR_UNLOCK 1 "Request to Unlock Doors" 0 "No Request / DV" ;
VAL_ 704 INDC_SRS 3 "Flashing 1Hz" 2 "Signal Invalid" 1 "Lamp ON" 0 "Lamp OFF / DV" ;
VAL_ 276 STS_SAS_TRIM 1 "Sensor Trimed" 0 "Sensor Not Trimed" ;
VAL_ 276 STS_SAS_FAILURE 1 "Information valid" 0 "Information invalid / default" ;
VAL_ 276 STS_SAS_CALIB 1 "Sensor  calibrated" 0 "Sensor not calibrated / Default" ;
VAL_ 276 ANGLE_SPD 255 "Signal Invalid" 0 "Default" ;
VAL_ 276 ABSOLUTE_ANGLE 32767 "Signal invalid" 0 "Default" ;
VAL_ 540 SUNROOF_REMINDER 1 "ON" 0 "Off / Default" ;
VAL_ 540 TRANSFER_MODE_IC 3 "Signal Invalid" 2 "4WD Low" 1 "4WD High" 0 "2WD / Default Value" ;
VAL_ 540 SPARE_TYRE_TEMP 255 "Signal invalid" 0 "Default Value" ;
VAL_ 540 SPARE_TYRE_PRESSURE 255 "Signal Invalid" 0 "Default value" ;
VAL_ 540 AUTO_RAIN 1 "Auto Wiper ON" 0 "Auto Wiper OFF / Default value" ;
VAL_ 540 AUTO_LIGHT 1 "AUTO LIGHT ON" 0 "AUTO LIGHT OFF / Default value" ;
VAL_ 540 BATT_VOLT 0 "Default" 255 "Signal Invalid" ;
VAL_ 540 BRAKE_LAMP_FAULT 3 "Reserved" 2 "Short to Batt" 1 "Short to Ground/Open" 0 "No Fault/Default Value" ;
VAL_ 540 HAND_BRAKE_REMINDER 1 "ON" 0 "Off / Default" ;
VAL_ 306 T50_STATUS 3 "Signal Invalid" 2 "Reserved" 1 "T50" 0 "Default value" ;
VAL_ 960 VIN_INDEX 3 "Signal Invalid" 2 "VIN_DATA2" 1 "VIN_DATA1" 0 "VIN_DATA0" ;
VAL_ 960 VIN_DATA_2 0 "DEFAULT VALUE" ;
VAL_ 960 VIN_DATA_1 0 "DEFAULT VALUE" ;
VAL_ 960 VIN_DATA_0 0 "DEFAULT VALUE" ;
VAL_ 293 ENG_SPD_RATE 4095 "Signal Invalid" 0 "Default Value" ;
VAL_ 293 ODO_DISTANCE_EMS 65535 "Signal Invalid" 0 "Default Value" ;
VAL_ 293 VEHICLE_SPEED_EMS 65535 "Signal Invalid" 65534 "Default" ;
VAL_ 292 BRK_PEDAL 3 "Signal Invalid" 2 "Reserved" 1 "Depressed" 0 "Not Pressed / Default" ;
VAL_ 292 INJ_QTY 2047 "Signal Invalid" 0 "Default" ;
VAL_ 292 STS_CRUISE_KEYPAD 7 "Signal Invalid" 6 "Time Gap" 5 "ON /OFF" 4 "Cencel key Pressed" 3 "Resume key pressed" 2 "Set - pressed" 1 "Set + Pressed" 0 "No key Pressed / Default" ;
VAL_ 292 CURRENT_GEAR_MT 15 "Signal Invalid" 14 "Reserved" 13 "Reserved" 12 "Reserved" 11 "Reserved" 10 "reserved" 9 "Reserved" 8 "Reserved" 7 "Reverse" 6 "Sixth" 5 "Fifth" 4 "Fourth" 3 "Third" 2 "Second" 1 "First" 0 "Neutral/Default" ;
VAL_ 292 STS_AC_COMPRESSOR 3 "Signal Invalid" 2 "Reserved" 1 "ON" 0 "OFF/Default" ;
VAL_ 292 ENG_SPD 65535 "Signal Invalid" 0 "Default" ;
VAL_ 292 ACC_PED 255 "Signal Invalid" 0 "Default" ;
VAL_ 292 STS_WATER_IN_FUEL 1 "Water in Fuel" 0 "No Water in Fuel / Default" ;
VAL_ 292 INDC_GLOW_PLUG 7 "Signal Invalid" 6 "Reserved" 5 "Reserved" 4 "Reserved" 3 "Reserved" 2 "Reserved" 1 "Glow ON" 0 "Glow OFF/Default" ;
VAL_ 292 ENG_TEMP 255 "Signal Invalid" 130 "Default" ;
VAL_ 292 INDC_CRUISE 3 "Signal Invalid" 2 "Reserved" 1 "ON" 0 "OFF / Default" ;
VAL_ 292 STS_ENG 7 "Reserved" 6 "Reserved" 5 "Engine cranking due to ESS" 4 "Engine Stalled" 3 "Engine Auto Stop(ESS)" 2 "Engine Running" 1 "Engine Cranking dut to T50" 0 "Engine Not Running / Default" ;
VAL_ 269 ESC_ACTIVE 1 "Active" 0 "Inactive / Default Value" ;
VAL_ 269 EBD_ACTIVE 1 "Active" 0 "Not Active / Default" ;
VAL_ 269 ABS_ACTIVE 1 "Active" 0 "Inactive / Default Value" ;
VAL_ 269 STS_ESC 3 "ESP lamp check" 2 "Not Available due to ESC passive" 1 "ESC Available" 0 "Not Available / Default Value" ;
VAL_ 312 VACCUM_PUMP_LIFE 1 "Pump Life Reached" 0 "Pump Life OK / Default Value" ;
VAL_ 312 VACCUM_CONTROL 3 "Reserved" 2 "Faulty No Operation" 1 "Faulty in Back Up Operation" 0 "Healthy / Default Value" ;
VAL_ 312 WHL_RR_SPD 4095 "Signal invalid" 0 "Default" ;
VAL_ 312 WHL_RL_SPD 4095 "Signal invalid" 0 "Default" ;
VAL_ 312 WHL_FR_SPD 4095 "Signal invalid" 0 "Default value" ;
VAL_ 312 WHL_FL_SPD 4095 "Signal Invalid" 0 "Default Value" ;
VAL_ 716 ODO_DISTANCE_ESC 65535 "Signal Invalid" 0 "Default value" ;
VAL_ 716 HDC_ACTIVE 3 "HDC Failure" 2 "Active & In Control" 1 "Active but control not necessary" 0 "Inactive / Default" ;
VAL_ 716 STS_HDC 1 "Available" 0 "Not Available / Default" ;
VAL_ 716 HHC_ACTIVE 1 "Active" 0 "Not Active / Default" ;
VAL_ 716 STS_ABS 1 "Available/Lamp OFF" 0 "Not Available/Lamp ON/DV" ;
VAL_ 716 STS_HHC 1 "Available" 0 "Not Available / Default" ;
VAL_ 716 STS_EBD 1 "Available/Lamp OFF" 0 "Not Available/Lamp ON/DV" ;
VAL_ 716 VEHICLE_SPEED_ESC 65535 "Signal Invalid" 65534 "Default Value" ;
VAL_ 832 TRANSFER_MODE_IC 3 "Signal Invalid" 2 "4WD Low" 1 "4WD High" 0 "2WD / Default Value" ;
VAL_ 832 SEAT_BELT_REMAINDER_FL_REAR 3 "Reserved" 2 "Reserved" 1 "Pattern 3" 0 "Default Value" ;
VAL_ 832 MANUAL_REGEN_REQ 1 "Start manual regeneration" 0 "Default value/No request" ;
VAL_ 832 FEEDBK_AT_AMT 1 "Telltale faulty" 0 "Telltale OK / Default" ;
VAL_ 832 FEEDBK_ESS_LAMP 1 "Telltale Faulty" 0 "Telltale OK / Default" ;
VAL_ 832 STS_BRAKE_FLUID_LVL 1 "Low" 0 "Normal / Default" ;
VAL_ 832 FEEDBK_CRUISE_LAMP 1 "Telltale Faulty" 0 "Telltale OK / Default" ;
VAL_ 832 PSGR_AIRBAG_SW_IC 1 "PAB OFF" 0 "PAB ON / Default" ;
VAL_ 832 AVG_KMPL_GD 511 "Signal Invalid" 0 "Default value" ;
VAL_ 832 AEE_RESET_REQ 1 "request" 0 "Default/no request" ;
VAL_ 832 FEEDBK_PARK_BRK 1 "Telltale faulty" 0 "Telltale OK / Default" ;
VAL_ 832 FEEDBK_ESC_MALFUNC 1 "Telltale Faulty" 0 "Telltale OK / Default" ;
VAL_ 832 FEEDBK_EPS 1 "Telltale faulty" 0 "Telltale OK / Default" ;
VAL_ 832 FEEDBK_ABS_LAMP 1 "Telltale Faulty" 0 "Telltale OK / Default" ;
VAL_ 832 ODOMTR_READING 1048575 "Signal Invalid" 0 "Default Value" ;
VAL_ 529 FUEL_LEVEL 65535 "Signal invalid" 65534 "Default value" ;
VAL_ 529 ENG_COOLANT_TEMP 1 "High Coolant Temp" 0 "Low Coolant Temp / Default" ;
VAL_ 529 AVG_KMPL 511 "Signal Invalid" 0 "Default value" ;
VAL_ 529 INDC_LOW_FUEL 1 "Low Fuel Warning" 0 "Normal Fuel / DV" ;
VAL_ 529 INSTANT_KMPL 511 "Signal Invalid" 0 "Default value" ;
VAL_ 529 FEEDBK_MIL 1 "Telltale Faulty" 0 "Telltale OK / Default" ;
VAL_ 529 RST_ACK_AFE 3 "Signal Invalid" 2 "Reserved" 1 "Reset acknowledged / done" 0 "Default Value" ;
VAL_ 529 DIST_TO_EMPTY 1023 "Signal Invalid" 0 "Default value" ;
VAL_ 529 SERVICE_REMINDER 7 "7th service" 6 "6th service" 5 "5th service" 4 "4th service" 3 "3rd service" 2 "2nd service" 1 "1st service" 0 "Default value" ;
VAL_ 529 CLU_FLEX_STEER_SW 1 "ON" 0 "OFF" ;
VAL_ 529 INDC_HIGH_SPD 1 "High Speed" 0 "Normal Speed / Default" ;
VAL_ 529 FEEDBK_SYSLAMP 1 "Telltale Faulty" 0 "Telltale OK / Default" ;
VAL_ 529 FEEDBK_SRS_LAMP 1 "Telltale faulty" 0 "Telltale OK / Default value" ;
VAL_ 529 TPMS_ENTER_PR 1 "Enter TPMS program mode" 0 "Normal/Default" ;
VAL_ 529 STS_PARK_BRK_IC 1 "Enguage" 0 "Default" ;
VAL_ 840 SECURITY_LED_MBFM 3 "Reserved" 2 "Pattern 5" 1 "Pattern 4" 0 "OFF/Default Value" ;
VAL_ 840 PARK_LAMP_ON_REMINDER 1 "Buzzer ON" 0 "Buzzer OFF/Default value" ;
VAL_ 840 KEY_IN_REMINDER 1 "Buzzer ON" 0 "Buzzer OFF/Default value" ;
VAL_ 840 STS_BRAKE_FLUID_LVL 1 "Low" 0 "Normal / Default" ;
VAL_ 840 INDC_PARK_BRK 1 "Engaged" 0 "Disengaged / Default value" ;
VAL_ 840 INDC_REAR_FOG 1 "Lamp ON" 0 "Lamp OFF / Default Value" ;
VAL_ 840 STS_IGN 7 "Signal Invalid" 6 "Reserved" 5 "ESS Crank" 4 "Key Crank KL50" 3 "Ignition KL15/Default Value" 2 "Acc KL15a" 1 "OFF - Key In" 0 "OFF - Key Out" ;
VAL_ 840 STS_RKE 7 "TG unarmed,veh armed,door locked" 6 "TG unarmed,veh armed,door unlock" 5 "reserved" 4 "reserved" 3 "TG armed, veh armed,door locked" 2 "TG armed,veh armed,door unlocked" 1 "All doors locked unarmed" 0 "All doors unlocked unarmed / DV" ;
VAL_ 840 STS_TRAILER 1 "Trailer connected" 0 "Trailer not connected / Default value" ;
VAL_ 840 STS_RKE_BATT 1 "Battery LOW" 0 "Battery OK / Default" ;
VAL_ 840 ENG_OFF_TIME 2047 "Signal Invalid" 0 "Default value" ;
VAL_ 840 STS_REAR_DEFOG_LOAD 1 "ON" 0 "OFF / Default" ;
VAL_ 840 STS_LOW_BEAM 1 "Lamp ON" 0 "Lamp OFF / Default value" ;
VAL_ 840 STS_HIGH_BEAM 1 "Lamp ON" 0 "Lamp OFF / Default value" ;
VAL_ 840 INDC_TURN_FLSHR 3 "HAZARD" 2 "RIGHT TURN" 1 "LEFT TURN" 0 "Lamp OFF / Default value" ;
VAL_ 840 STS_SEAT_BLT_PSGR_MBFM 3 "Reserved" 2 "Buckle Faulty" 1 "Buckled" 0 "Not Buckled / Default value" ;
VAL_ 840 STS_SEAT_BLT_DRV_MBFM 3 "Reserved" 2 "Buckle Faulty" 1 "Buckled" 0 "Not Buckled / Default value" ;
VAL_ 840 STS_DOOR 63 "All Door Open" 32 "Only RR Door Open" 16 "Only RL Door Open" 8 "Only FR Door Open" 4 "Only FL Door Open" 2 "Only Hood Open" 1 "Only Back Door Open" 0 "All Closed / Default" ;
VAL_ 840 STS_PARKLAMP 3 "Reserved" 2 "Reserved" 1 "ON" 0 "OFF / Default" ;
VAL_ 840 INDC_FRNT_FOG 1 "ON" 0 "OFF/DV" ;
VAL_ 556 LKA_SENSITIVITY 3 "Reserved" 2 "High" 1 "Low" 0 "Normal / Default" ;
VAL_ 556 TJA_MODE 1 "TJA Enabled" 0 "System OFF / Default" ;
VAL_ 556 LDW_LKA_SYS_STATE 7 "Reserved" 6 "Reserved" 5 "System Not Calibrated" 4 "System fail" 3 "Warning" 2 "Active" 1 "Standby" 0 "System Off / Default" ;
VAL_ 556 LKA_HANDSOFF_DISPLAY_WARNING 1 "Display Warning" 0 "No Warning / Default" ;
VAL_ 556 TJA_STATE 7 "System Failure" 6 "Reserved" 5 "Reserved" 4 "In Control" 3 "Control Off" 2 "TJA active" 1 "TJA ready" 0 "TJA Off / Default" ;
VAL_ 556 TJA_HANDSOFF_WARNING 3 "Automatic Off Warning" 2 "Hands Off 2nd Warning" 1 "Hands Off 1st Warning" 0 "No Warning / Default" ;
VAL_ 556 LKA_HANDSOFF_AUDIO_WARNING 1 "Audio Warning" 0 "No Warning / Default" ;
VAL_ 556 LDW_LKA_WARNING 3 "Reserved" 2 "Right Lane Departure Warning " 1 "Left Lane Departure Warning" 0 "No Warning / Default" ;
VAL_ 556 LDW_LKA_LANE_RECOGN 3 "Both Lane " 2 "Right Lane " 1 "Left Lane " 0 "No Recognition / Default" ;
VAL_ 556 LDW_LKA_MODE 3 "Signal Invalid" 2 "LDW+LKA / Default" 1 "LDW" 0 "LDW+LKA OFF" ;
VAL_ 776 DISP_AMBT_TEMP_EMS 0 "Default Value" 255 "Invalid value" ;
VAL_ 776 STS_REMOTE_ENG 3 "Reserved" 2 "Remotely Engine stopped" 1 "Veh Spd restic ON / Remote Start" 0 "Veh Spd restic Off / Normal Mode" ;
VAL_ 776 VALET_MODE_STATUS 1 "Valet Mode" 0 "Normal Mode / Default Value" ;
VAL_ 776 ENG_ON_TIME 65535 "Signal invalid" 0 "Default value" ;
VAL_ 778 Reduce_Power_Mode_TT 3 "Reserved" 2 "Reduce Pwr ModeTT Blink" 1 "Reduce Pwr ModeTT ON" 0 "Reduce Pwr ModeTT OFF/default" ;
VAL_ 778 REGEN_LEVELS 7 "Signal Invalid" 6 "Reserved" 5 "Reserved" 4 "Reserved" 3 "Level 3" 2 "Level 2" 1 "Level 1" 0 "Level 0" ;
VAL_ 778 Sts_Regen_Cutoff_TT 1 "Regen Cutoff from EPT" 0 "Regen Available from EPT" ;
VAL_ 778 LOW_AUX_BATT_TT 3 "Reserved" 2 "Low AUX Battery Blink" 1 "Low AUX Battery ON" 0 "Low AUX Battery OFF / Default" ;
VAL_ 778 HIGH_TEMP_LIGHT_OP 3 "Reserved" 2 "TEMP Light Blink" 1 "TEMP Light ON" 0 "TEMP Light OFF / Default" ;
VAL_ 778 STS_SERVICE_LIGHT_TT 3 "Reserved" 2 "Service Light Blink" 1 "Service Light ON" 0 "Service Light OFF / Default" ;
VAL_ 778 STS_HV_BATT_TT 3 "Reserved" 2 "Blink" 1 "ON" 0 "OFF / Default Value" ;
VAL_ 778 STS_EVWARNING_TT 3 "Reserved" 2 "EV Warning Blink" 1 "EV Warning ON" 0 "EV Warning OFF / Default" ;
VAL_ 778 STS_CHARGE_LIGHT_TT 3 "Reserved" 2 "Charge Light Blink" 1 "Charge Light ON" 0 "Charge Light OFF / Default" ;
VAL_ 778 ALERT_MSGS 45 "RESERVED" 44 "Coolant low temperature" 43 "Stop & leave the vehicle" 42 "Battery Low Temperature" 41 "RESERVED" 40 "Stay In Park" 39 "Park Motor Failure" 38 "PRESS BRAKE" 37 "Press Start-Stop to Start" 36 "Turn Ign Key to Start vehicle" 35 "HVIL FAULT" 34 "PRECONDITIONING" 33 "ENGAGE PARK" 32 "CHARGING" 31 "Reserved" 30 "HV BATT HIGH TEMP" 29 "EPT HIGH TEMP" 28 "HILL HOLD DEACTIVE" 27 "GO SLOW (FLASH)" 26 "ISOLATION FAULT" 25 "REVIVE UNSUCCESSFULL" 24 "REVIVE MODE" 23 "REVIVE" 22 "ACTIVATE REVIVE" 21 "CHARGE CAR" 20 "RESERVED" 19 "RESERVED" 18 "TURN ON MAINS" 17 "UNPLUG CAR" 16 "RELEASE THROTTLE" 15 "SHIFT GEAR TO N" 14 "POWER SAVE MODE" 13 "INSERT PLUG FULL" 12 "Vehicle is about to STOP" 11 "SERVICE DUE" 10 "RESERVED" 9 "RESTART" 8 "DRIVE FAULT" 7 "SAFE MODE" 6 "Reserved" 5 "Please Stop the CAR" 4 "GO SLOW" 3 "CHARGE TERMINATE" 2 "CHARGE COMPLETE" 1 "CHARGE FAULT" 0 "No Message / Default Value" ;
VAL_ 778 PRESS_BRAKE 0 "NOT READY/DEFAULT/NO TT" 1 "READY/DISPLAY TT" ;
VAL_ 778 EV_READY_TT 3 "RESERVED" 2 "BLINKING" 1 "ON" 0 "OFF/DEFAULT" ;
VAL_ 778 DRIVE_EFFICIENCY 255 "Signal Invalid" 100 "Default value" ;
VAL_ 778 TIME_TO_CHARGE_VCU 255 "signal invalid" 0 "default" ;
VAL_ 778 STATE_OF_CHARGE 255 "Signal Invalid" 0 "Default Value" ;
VAL_ 778 INDC_DRIVE_ENABLE 3 "Reserved" 2 "Reserved" 1 "Drive enabled/Activate Vehicle" 0 "Default/Vehicle not enabled" ;
VAL_ 778 AEE_RESET_REQ_FB 1 "Reset success" 0 "Default value/Request failed" ;
VAL_ 778 GEAR_ACTUAL_VCU 7 "Signal Invalid" 6 "Reserved" 5 "Park Mode" 4 "Reserved" 3 "Low Mode" 2 "Reverse Mode" 1 "Forward Mode" 0 "Neutral Mode / Default" ;
VAL_ 1424 AVAIL_PWR_COMPRESSOR 255 "Signal Invalid" 0 "Default Value" ;
VAL_ 1424 AVAIL_PWR_CABIN_HEATER 255 "Signal Invalid" 0 "Default Value" ;
VAL_ 1424 DTE 1023 "Signal Invalid" 0 "Default Value" ;
VAL_ 1424 VEHICLE_MODE 7 "Signal Invalid" 6 "Reserved" 5 "Reserved" 4 "Fastcharge Mode" 3 "Drive Mode" 2 "Nomral Charge Mode" 1 "Idle Mode" 0 "Invalid Mode" ;
VAL_ 1424 VESS_DISABLE 1 "Disbale" 0 "Enable / Default" ;
